VERSION "2023_6_12_103836"

NS_ :

BS_:

BU_: XPU SRR_RL Tester
BO_ 618 S4_SRR_RL_Obj_Mes_3: 64 SRR_RL
 SG_ S4_SRR_RL_Obj_ID_9 : 7|7@0+ (1,0) [0|126] "" Vector__XXX
 SG_ S4_SRR_RL_Obj_DistX_9 : 0|13@0+ (0.0625,-255.9375) [-255.9375|255.9375] "m" Vector__XXX
 SG_ S4_SRR_RL_Obj_RelVelX_9 : 19|11@0+ (0.125,-128) [-128|127.875] "mps" Vector__XXX
 SG_ S4_SRR_RL_Obj_AccelX_9 : 24|10@0+ (0.125,-44.5) [-44.5|44.5] "mps2" Vector__XXX
 SG_ S4_SRR_RL_Obj_DistY_9 : 46|13@0+ (0.0625,-255.9375) [-255.9375|255.9375] "m" Vector__XXX
 SG_ S4_SRR_RL_Obj_RelVelY_9 : 49|11@0+ (0.125,-128) [-128|127.875] "mps" Vector__XXX
 SG_ S4_SRR_RL_Obj_AccelY_9 : 70|10@0+ (0.125,-44.5) [-44.5|44.5] "mps2" Vector__XXX
 SG_ S4_SRR_RL_Obj_DistXStd_9 : 76|8@0+ (0.05,0) [0|12.75] "m" Vector__XXX
 SG_ S4_SRR_RL_Obj_RelVelXStd_9 : 84|6@0+ (0.2,0) [0|12.6] "mps" Vector__XXX
 SG_ S4_SRR_RL_Obj_RAccelXStd_9 : 94|5@0+ (0.35,0) [0|10.85] "mps2" Vector__XXX
 SG_ S4_SRR_RL_Obj_DistYStd_9 : 89|8@0+ (0.1,0) [0|25.5] "m" Vector__XXX
 SG_ S4_SRR_RL_Obj_RelVelYStd_9 : 97|6@0+ (0.2,0) [0|12.6] "mps" Vector__XXX
 SG_ S4_SRR_RL_Obj_RAccelYStd_9 : 107|5@0+ (0.35,0) [0|10.85] "mps2" Vector__XXX
 SG_ S4_SRR_RL_Obj_ValidFlag_9 : 118|1@0+ (1,0) [0|1] "" Vector__XXX
 SG_ S4_SRR_RL_Obj_UpdateFlag_9 : 117|1@0+ (1,0) [0|1] "" Vector__XXX
 SG_ S4_SRR_RL_Obj_ExistProb_9 : 116|7@0+ (1,0) [0|100] "percent" Vector__XXX
 SG_ S4_SRR_RL_Obj_Type_9 : 125|4@0+ (1,0) [0|15] "" Vector__XXX
 SG_ S4_SRR_RL_Obj_EDynProp_9 : 121|4@0+ (1,0) [0|15] "" Vector__XXX
 SG_ S4_SRR_RL_Obj_UiLifeCycles_9 : 133|7@0+ (1,0) [0|127] "" Vector__XXX
 SG_ S4_SRR_RL_Obj_RCS_9 : 142|11@0+ (0.1,-100) [-100|100] "dBm" Vector__XXX
 SG_ S4_SRR_RL_Obj_ID_10 : 147|7@0+ (1,0) [0|126] "" Vector__XXX
 SG_ S4_SRR_RL_Obj_DistX_10 : 156|13@0+ (0.0625,-255.9375) [-255.9375|255.9375] "m" Vector__XXX
 SG_ S4_SRR_RL_Obj_RelVelX_10 : 175|11@0+ (0.125,-128) [-128|127.875] "mps" Vector__XXX
 SG_ S4_SRR_RL_Obj_AccelX_10 : 180|10@0+ (0.125,-44.5) [-44.5|44.5] "mps2" Vector__XXX
 SG_ S4_SRR_RL_Obj_DistY_10 : 186|13@0+ (0.0625,-255.9375) [-255.9375|255.9375] "m" Vector__XXX
 SG_ S4_SRR_RL_Obj_RelVelY_10 : 205|11@0+ (0.125,-128) [-128|127.875] "mps" Vector__XXX
 SG_ S4_SRR_RL_Obj_AccelY_10 : 210|10@0+ (0.125,-44.5) [-44.5|44.5] "mps2" Vector__XXX
 SG_ S4_SRR_RL_Obj_DistXStd_10 : 216|8@0+ (0.05,0) [0|12.75] "m" Vector__XXX
 SG_ S4_SRR_RL_Obj_RelVelXStd_10 : 224|6@0+ (0.2,0) [0|12.6] "mps" Vector__XXX
 SG_ S4_SRR_RL_Obj_RAccelXStd_10 : 234|5@0+ (0.35,0) [0|10.85] "mps2" Vector__XXX
 SG_ S4_SRR_RL_Obj_DistYStd_10 : 245|8@0+ (0.1,0) [0|25.5] "m" Vector__XXX
 SG_ S4_SRR_RL_Obj_RelVelYStd_10 : 253|6@0+ (0.2,0) [0|12.6] "mps" Vector__XXX
 SG_ S4_SRR_RL_Obj_RAccelYStd_10 : 263|5@0+ (0.35,0) [0|10.85] "mps2" Vector__XXX
 SG_ S4_SRR_RL_Obj_ValidFlag_10 : 258|1@0+ (1,0) [0|1] "" Vector__XXX
 SG_ S4_SRR_RL_Obj_UpdateFlag_10 : 257|1@0+ (1,0) [0|1] "" Vector__XXX
 SG_ S4_SRR_RL_Obj_ExistProb_10 : 256|7@0+ (1,0) [0|100] "percent" Vector__XXX
 SG_ S4_SRR_RL_Obj_Type_10 : 265|4@0+ (1,0) [0|15] "" Vector__XXX
 SG_ S4_SRR_RL_Obj_EDynProp_10 : 277|4@0+ (1,0) [0|15] "" Vector__XXX
 SG_ S4_SRR_RL_Obj_UiLifeCycles_10 : 273|7@0+ (1,0) [0|127] "" Vector__XXX
 SG_ S4_SRR_RL_Obj_RCS_10 : 282|11@0+ (0.1,-100) [-100|100] "dBm" Vector__XXX
 SG_ S4_SRR_RL_Obj_ID_11 : 303|7@0+ (1,0) [0|126] "" Vector__XXX
 SG_ S4_SRR_RL_Obj_DistX_11 : 296|13@0+ (0.0625,-255.9375) [-255.9375|255.9375] "m" Vector__XXX
 SG_ S4_SRR_RL_Obj_RelVelX_11 : 315|11@0+ (0.125,-128) [-128|127.875] "mps" Vector__XXX
 SG_ S4_SRR_RL_Obj_AccelX_11 : 320|10@0+ (0.125,-44.5) [-44.5|44.5] "mps2" Vector__XXX
 SG_ S4_SRR_RL_Obj_DistY_11 : 342|13@0+ (0.0625,-255.9375) [-255.9375|255.9375] "m" Vector__XXX
 SG_ S4_SRR_RL_Obj_RelVelY_11 : 345|11@0+ (0.125,-128) [-128|127.875] "mps" Vector__XXX
 SG_ S4_SRR_RL_Obj_AccelY_11 : 366|10@0+ (0.125,-44.5) [-44.5|44.5] "mps2" Vector__XXX
 SG_ S4_SRR_RL_Obj_DistXStd_11 : 372|8@0+ (0.05,0) [0|12.75] "m" Vector__XXX
 SG_ S4_SRR_RL_Obj_RelVelXStd_11 : 380|6@0+ (0.2,0) [0|12.6] "mps" Vector__XXX
 SG_ S4_SRR_RL_Obj_RAccelXStd_11 : 390|5@0+ (0.35,0) [0|10.85] "mps2" Vector__XXX
 SG_ S4_SRR_RL_Obj_DistYStd_11 : 385|8@0+ (0.1,0) [0|25.5] "m" Vector__XXX
 SG_ S4_SRR_RL_Obj_RelVelYStd_11 : 393|6@0+ (0.2,0) [0|12.6] "mps" Vector__XXX
 SG_ S4_SRR_RL_Obj_RAccelYStd_11 : 403|5@0+ (0.35,0) [0|10.85] "mps2" Vector__XXX
 SG_ S4_SRR_RL_Obj_ValidFlag_11 : 414|1@0+ (1,0) [0|1] "" Vector__XXX
 SG_ S4_SRR_RL_Obj_UpdateFlag_11 : 413|1@0+ (1,0) [0|1] "" Vector__XXX
 SG_ S4_SRR_RL_Obj_ExistProb_11 : 412|7@0+ (1,0) [0|100] "percent" Vector__XXX
 SG_ S4_SRR_RL_Obj_Type_11 : 421|4@0+ (1,0) [0|15] "" Vector__XXX
 SG_ S4_SRR_RL_Obj_EDynProp_11 : 417|4@0+ (1,0) [0|15] "" Vector__XXX
 SG_ S4_SRR_RL_Obj_UiLifeCycles_11 : 429|7@0+ (1,0) [0|127] "" Vector__XXX
 SG_ S4_SRR_RL_Obj_RCS_11 : 438|11@0+ (0.1,-100) [-100|100] "dBm" Vector__XXX
 SG_ S4_SRR_RL_Obj_Mes_3_blockcounter : 503|4@0+ (1,0) [0|15] "" Vector__XXX
 SG_ S4_SRR_RL_Obj_3_MsgCounter : 499|4@0+ (1,0) [0|14] "" Vector__XXX
 SG_ S4_SRR_RL_Obj_3_E2EChecksum : 511|8@0+ (1,0) [0|255] "" Vector__XXX

BO_ 619 S4_SRR_RL_Obj_Mes_4: 64 SRR_RL
 SG_ S4_SRR_RL_Obj_ID_12 : 7|7@0+ (1,0) [0|126] "" Vector__XXX
 SG_ S4_SRR_RL_Obj_DistX_12 : 0|13@0+ (0.0625,-255.9375) [-255.9375|255.9375] "m" Vector__XXX
 SG_ S4_SRR_RL_Obj_RelVelX_12 : 19|11@0+ (0.125,-128) [-128|127.875] "mps" Vector__XXX
 SG_ S4_SRR_RL_Obj_AccelX_12 : 24|10@0+ (0.125,-44.5) [-44.5|44.5] "mps2" Vector__XXX
 SG_ S4_SRR_RL_Obj_DistY_12 : 46|13@0+ (0.0625,-255.9375) [-255.9375|255.9375] "m" Vector__XXX
 SG_ S4_SRR_RL_Obj_RelVelY_12 : 49|11@0+ (0.125,-128) [-128|127.875] "mps" Vector__XXX
 SG_ S4_SRR_RL_Obj_AccelY_12 : 70|10@0+ (0.125,-44.5) [-44.5|44.5] "mps2" Vector__XXX
 SG_ S4_SRR_RL_Obj_DistXStd_12 : 76|8@0+ (0.05,0) [0|12.75] "m" Vector__XXX
 SG_ S4_SRR_RL_Obj_RelVelXStd_12 : 84|6@0+ (0.2,0) [0|12.6] "mps" Vector__XXX
 SG_ S4_SRR_RL_Obj_RAccelXStd_12 : 94|5@0+ (0.35,0) [0|10.85] "mps2" Vector__XXX
 SG_ S4_SRR_RL_Obj_DistYStd_12 : 89|8@0+ (0.1,0) [0|25.5] "m" Vector__XXX
 SG_ S4_SRR_RL_Obj_RelVelYStd_12 : 97|6@0+ (0.2,0) [0|12.6] "mps" Vector__XXX
 SG_ S4_SRR_RL_Obj_RAccelYStd_12 : 107|5@0+ (0.35,0) [0|10.85] "mps2" Vector__XXX
 SG_ S4_SRR_RL_Obj_ValidFlag_12 : 118|1@0+ (1,0) [0|1] "" Vector__XXX
 SG_ S4_SRR_RL_Obj_UpdateFlag_12 : 117|1@0+ (1,0) [0|1] "" Vector__XXX
 SG_ S4_SRR_RL_Obj_ExistProb_12 : 116|7@0+ (1,0) [0|100] "percent" Vector__XXX
 SG_ S4_SRR_RL_Obj_Type_12 : 125|4@0+ (1,0) [0|15] "" Vector__XXX
 SG_ S4_SRR_RL_Obj_EDynProp_12 : 121|4@0+ (1,0) [0|15] "" Vector__XXX
 SG_ S4_SRR_RL_Obj_UiLifeCycles_12 : 133|7@0+ (1,0) [0|127] "" Vector__XXX
 SG_ S4_SRR_RL_Obj_RCS_12 : 142|11@0+ (0.1,-100) [-100|100] "dBm" Vector__XXX
 SG_ S4_SRR_RL_Obj_ID_13 : 147|7@0+ (1,0) [0|126] "" Vector__XXX
 SG_ S4_SRR_RL_Obj_DistX_13 : 156|13@0+ (0.0625,-255.9375) [-255.9375|255.9375] "m" Vector__XXX
 SG_ S4_SRR_RL_Obj_RelVelX_13 : 175|11@0+ (0.125,-128) [-128|127.875] "mps" Vector__XXX
 SG_ S4_SRR_RL_Obj_AccelX_13 : 180|10@0+ (0.125,-44.5) [-44.5|44.5] "mps2" Vector__XXX
 SG_ S4_SRR_RL_Obj_DistY_13 : 186|13@0+ (0.0625,-255.9375) [-255.9375|255.9375] "m" Vector__XXX
 SG_ S4_SRR_RL_Obj_RelVelY_13 : 205|11@0+ (0.125,-128) [-128|127.875] "mps" Vector__XXX
 SG_ S4_SRR_RL_Obj_AccelY_13 : 210|10@0+ (0.125,-44.5) [-44.5|44.5] "mps2" Vector__XXX
 SG_ S4_SRR_RL_Obj_DistXStd_13 : 216|8@0+ (0.05,0) [0|12.75] "m" Vector__XXX
 SG_ S4_SRR_RL_Obj_RelVelXStd_13 : 224|6@0+ (0.2,0) [0|12.6] "mps" Vector__XXX
 SG_ S4_SRR_RL_Obj_RAccelXStd_13 : 234|5@0+ (0.35,0) [0|10.85] "mps2" Vector__XXX
 SG_ S4_SRR_RL_Obj_DistYStd_13 : 245|8@0+ (0.1,0) [0|25.5] "m" Vector__XXX
 SG_ S4_SRR_RL_Obj_RelVelYStd_13 : 253|6@0+ (0.2,0) [0|12.6] "mps" Vector__XXX
 SG_ S4_SRR_RL_Obj_RAccelYStd_13 : 263|5@0+ (0.35,0) [0|10.85] "mps2" Vector__XXX
 SG_ S4_SRR_RL_Obj_ValidFlag_13 : 258|1@0+ (1,0) [0|1] "" Vector__XXX
 SG_ S4_SRR_RL_Obj_UpdateFlag_13 : 257|1@0+ (1,0) [0|1] "" Vector__XXX
 SG_ S4_SRR_RL_Obj_ExistProb_13 : 256|7@0+ (1,0) [0|100] "percent" Vector__XXX
 SG_ S4_SRR_RL_Obj_Type_13 : 265|4@0+ (1,0) [0|15] "" Vector__XXX
 SG_ S4_SRR_RL_Obj_EDynProp_13 : 277|4@0+ (1,0) [0|15] "" Vector__XXX
 SG_ S4_SRR_RL_Obj_UiLifeCycles_13 : 273|7@0+ (1,0) [0|127] "" Vector__XXX
 SG_ S4_SRR_RL_Obj_RCS_13 : 282|11@0+ (0.1,-100) [-100|100] "dBm" Vector__XXX
 SG_ S4_SRR_RL_Obj_ID_14 : 303|7@0+ (1,0) [0|126] "" Vector__XXX
 SG_ S4_SRR_RL_Obj_DistX_14 : 296|13@0+ (0.0625,-255.9375) [-255.9375|255.9375] "m" Vector__XXX
 SG_ S4_SRR_RL_Obj_RelVelX_14 : 315|11@0+ (0.125,-128) [-128|127.875] "mps" Vector__XXX
 SG_ S4_SRR_RL_Obj_AccelX_14 : 320|10@0+ (0.125,-44.5) [-44.5|44.5] "mps2" Vector__XXX
 SG_ S4_SRR_RL_Obj_DistY_14 : 342|13@0+ (0.0625,-255.9375) [-255.9375|255.9375] "m" Vector__XXX
 SG_ S4_SRR_RL_Obj_RelVelY_14 : 345|11@0+ (0.125,-128) [-128|127.875] "mps" Vector__XXX
 SG_ S4_SRR_RL_Obj_AccelY_14 : 366|10@0+ (0.125,-44.5) [-44.5|44.5] "mps2" Vector__XXX
 SG_ S4_SRR_RL_Obj_DistXStd_14 : 372|8@0+ (0.05,0) [0|12.75] "m" Vector__XXX
 SG_ S4_SRR_RL_Obj_RelVelXStd_14 : 380|6@0+ (0.2,0) [0|12.6] "mps" Vector__XXX
 SG_ S4_SRR_RL_Obj_RAccelXStd_14 : 390|5@0+ (0.35,0) [0|10.85] "mps2" Vector__XXX
 SG_ S4_SRR_RL_Obj_DistYStd_14 : 385|8@0+ (0.1,0) [0|25.5] "m" Vector__XXX
 SG_ S4_SRR_RL_Obj_RelVelYStd_14 : 393|6@0+ (0.2,0) [0|12.6] "mps" Vector__XXX
 SG_ S4_SRR_RL_Obj_RAccelYStd_14 : 403|5@0+ (0.35,0) [0|10.85] "mps2" Vector__XXX
 SG_ S4_SRR_RL_Obj_ValidFlag_14 : 414|1@0+ (1,0) [0|1] "" Vector__XXX
 SG_ S4_SRR_RL_Obj_UpdateFlag_14 : 413|1@0+ (1,0) [0|1] "" Vector__XXX
 SG_ S4_SRR_RL_Obj_ExistProb_14 : 412|7@0+ (1,0) [0|100] "percent" Vector__XXX
 SG_ S4_SRR_RL_Obj_Type_14 : 421|4@0+ (1,0) [0|15] "" Vector__XXX
 SG_ S4_SRR_RL_Obj_EDynProp_14 : 417|4@0+ (1,0) [0|15] "" Vector__XXX
 SG_ S4_SRR_RL_Obj_UiLifeCycles_14 : 429|7@0+ (1,0) [0|127] "" Vector__XXX
 SG_ S4_SRR_RL_Obj_RCS_14 : 438|11@0+ (0.1,-100) [-100|100] "dBm" Vector__XXX
 SG_ S4_SRR_RL_Obj_Mes_4_blockcounter : 503|4@0+ (1,0) [0|15] "" Vector__XXX
 SG_ S4_SRR_RL_Obj_4_MsgCounter : 499|4@0+ (1,0) [0|14] "" Vector__XXX
 SG_ S4_SRR_RL_Obj_4_E2EChecksum : 511|8@0+ (1,0) [0|255] "" Vector__XXX

BO_ 620 S4_SRR_RL_Obj_Mes_5: 64 SRR_RL
 SG_ S4_SRR_RL_Obj_ID_15 : 7|7@0+ (1,0) [0|126] "" Vector__XXX
 SG_ S4_SRR_RL_Obj_DistX_15 : 0|13@0+ (0.0625,-255.9375) [-255.9375|255.9375] "m" Vector__XXX
 SG_ S4_SRR_RL_Obj_RelVelX_15 : 19|11@0+ (0.125,-128) [-128|127.875] "mps" Vector__XXX
 SG_ S4_SRR_RL_Obj_AccelX_15 : 24|10@0+ (0.125,-44.5) [-44.5|44.5] "mps2" Vector__XXX
 SG_ S4_SRR_RL_Obj_DistY_15 : 46|13@0+ (0.0625,-255.9375) [-255.9375|255.9375] "m" Vector__XXX
 SG_ S4_SRR_RL_Obj_RelVelY_15 : 49|11@0+ (0.125,-128) [-128|127.875] "mps" Vector__XXX
 SG_ S4_SRR_RL_Obj_AccelY_15 : 70|10@0+ (0.125,-44.5) [-44.5|44.5] "mps2" Vector__XXX
 SG_ S4_SRR_RL_Obj_DistXStd_15 : 76|8@0+ (0.05,0) [0|12.75] "m" Vector__XXX
 SG_ S4_SRR_RL_Obj_RelVelXStd_15 : 84|6@0+ (0.2,0) [0|12.6] "mps" Vector__XXX
 SG_ S4_SRR_RL_Obj_RAccelXStd_15 : 94|5@0+ (0.35,0) [0|10.85] "mps2" Vector__XXX
 SG_ S4_SRR_RL_Obj_DistYStd_15 : 89|8@0+ (0.1,0) [0|25.5] "m" Vector__XXX
 SG_ S4_SRR_RL_Obj_RelVelYStd_15 : 97|6@0+ (0.2,0) [0|12.6] "mps" Vector__XXX
 SG_ S4_SRR_RL_Obj_RAccelYStd_15 : 107|5@0+ (0.35,0) [0|10.85] "mps2" Vector__XXX
 SG_ S4_SRR_RL_Obj_ValidFlag_15 : 118|1@0+ (1,0) [0|1] "" Vector__XXX
 SG_ S4_SRR_RL_Obj_UpdateFlag_15 : 117|1@0+ (1,0) [0|1] "" Vector__XXX
 SG_ S4_SRR_RL_Obj_ExistProb_15 : 116|7@0+ (1,0) [0|100] "percent" Vector__XXX
 SG_ S4_SRR_RL_Obj_Type_15 : 125|4@0+ (1,0) [0|15] "" Vector__XXX
 SG_ S4_SRR_RL_Obj_EDynProp_15 : 121|4@0+ (1,0) [0|15] "" Vector__XXX
 SG_ S4_SRR_RL_Obj_UiLifeCycles_15 : 133|7@0+ (1,0) [0|127] "" Vector__XXX
 SG_ S4_SRR_RL_Obj_RCS_15 : 142|11@0+ (0.1,-100) [-100|100] "dBm" Vector__XXX
 SG_ S4_SRR_RL_Obj_ID_16 : 147|7@0+ (1,0) [0|126] "" Vector__XXX
 SG_ S4_SRR_RL_Obj_DistX_16 : 156|13@0+ (0.0625,-255.9375) [-255.9375|255.9375] "m" Vector__XXX
 SG_ S4_SRR_RL_Obj_RelVelX_16 : 175|11@0+ (0.125,-128) [-128|127.875] "mps" Vector__XXX
 SG_ S4_SRR_RL_Obj_AccelX_16 : 180|10@0+ (0.125,-44.5) [-44.5|44.5] "mps2" Vector__XXX
 SG_ S4_SRR_RL_Obj_DistY_16 : 186|13@0+ (0.0625,-255.9375) [-255.9375|255.9375] "m" Vector__XXX
 SG_ S4_SRR_RL_Obj_RelVelY_16 : 205|11@0+ (0.125,-128) [-128|127.875] "mps" Vector__XXX
 SG_ S4_SRR_RL_Obj_AccelY_16 : 210|10@0+ (0.125,-44.5) [-44.5|44.5] "mps2" Vector__XXX
 SG_ S4_SRR_RL_Obj_DistXStd_16 : 216|8@0+ (0.05,0) [0|12.75] "m" Vector__XXX
 SG_ S4_SRR_RL_Obj_RelVelXStd_16 : 224|6@0+ (0.2,0) [0|12.6] "mps" Vector__XXX
 SG_ S4_SRR_RL_Obj_RAccelXStd_16 : 234|5@0+ (0.35,0) [0|10.85] "mps2" Vector__XXX
 SG_ S4_SRR_RL_Obj_DistYStd_16 : 245|8@0+ (0.1,0) [0|25.5] "m" Vector__XXX
 SG_ S4_SRR_RL_Obj_RelVelYStd_16 : 253|6@0+ (0.2,0) [0|12.6] "mps" Vector__XXX
 SG_ S4_SRR_RL_Obj_RAccelYStd_16 : 263|5@0+ (0.35,0) [0|10.85] "mps2" Vector__XXX
 SG_ S4_SRR_RL_Obj_ValidFlag_16 : 258|1@0+ (1,0) [0|1] "" Vector__XXX
 SG_ S4_SRR_RL_Obj_UpdateFlag_16 : 257|1@0+ (1,0) [0|1] "" Vector__XXX
 SG_ S4_SRR_RL_Obj_ExistProb_16 : 256|7@0+ (1,0) [0|100] "percent" Vector__XXX
 SG_ S4_SRR_RL_Obj_Type_16 : 265|4@0+ (1,0) [0|15] "" Vector__XXX
 SG_ S4_SRR_RL_Obj_EDynProp_16 : 277|4@0+ (1,0) [0|15] "" Vector__XXX
 SG_ S4_SRR_RL_Obj_UiLifeCycles_16 : 273|7@0+ (1,0) [0|127] "" Vector__XXX
 SG_ S4_SRR_RL_Obj_RCS_16 : 282|11@0+ (0.1,-100) [-100|100] "dBm" Vector__XXX
 SG_ S4_SRR_RL_Obj_ID_17 : 303|7@0+ (1,0) [0|126] "" Vector__XXX
 SG_ S4_SRR_RL_Obj_DistX_17 : 296|13@0+ (0.0625,-255.9375) [-255.9375|255.9375] "m" Vector__XXX
 SG_ S4_SRR_RL_Obj_RelVelX_17 : 315|11@0+ (0.125,-128) [-128|127.875] "mps" Vector__XXX
 SG_ S4_SRR_RL_Obj_AccelX_17 : 320|10@0+ (0.125,-44.5) [-44.5|44.5] "mps2" Vector__XXX
 SG_ S4_SRR_RL_Obj_DistY_17 : 342|13@0+ (0.0625,-255.9375) [-255.9375|255.9375] "m" Vector__XXX
 SG_ S4_SRR_RL_Obj_RelVelY_17 : 345|11@0+ (0.125,-128) [-128|127.875] "mps" Vector__XXX
 SG_ S4_SRR_RL_Obj_AccelY_17 : 366|10@0+ (0.125,-44.5) [-44.5|44.5] "mps2" Vector__XXX
 SG_ S4_SRR_RL_Obj_DistXStd_17 : 372|8@0+ (0.05,0) [0|12.75] "m" Vector__XXX
 SG_ S4_SRR_RL_Obj_RelVelXStd_17 : 380|6@0+ (0.2,0) [0|12.6] "mps" Vector__XXX
 SG_ S4_SRR_RL_Obj_RAccelXStd_17 : 390|5@0+ (0.35,0) [0|10.85] "mps2" Vector__XXX
 SG_ S4_SRR_RL_Obj_DistYStd_17 : 385|8@0+ (0.1,0) [0|25.5] "m" Vector__XXX
 SG_ S4_SRR_RL_Obj_RelVelYStd_17 : 393|6@0+ (0.2,0) [0|12.6] "mps" Vector__XXX
 SG_ S4_SRR_RL_Obj_RAccelYStd_17 : 403|5@0+ (0.35,0) [0|10.85] "mps2" Vector__XXX
 SG_ S4_SRR_RL_Obj_ValidFlag_17 : 414|1@0+ (1,0) [0|1] "" Vector__XXX
 SG_ S4_SRR_RL_Obj_UpdateFlag_17 : 413|1@0+ (1,0) [0|1] "" Vector__XXX
 SG_ S4_SRR_RL_Obj_ExistProb_17 : 412|7@0+ (1,0) [0|100] "percent" Vector__XXX
 SG_ S4_SRR_RL_Obj_Type_17 : 421|4@0+ (1,0) [0|15] "" Vector__XXX
 SG_ S4_SRR_RL_Obj_EDynProp_17 : 417|4@0+ (1,0) [0|15] "" Vector__XXX
 SG_ S4_SRR_RL_Obj_UiLifeCycles_17 : 429|7@0+ (1,0) [0|127] "" Vector__XXX
 SG_ S4_SRR_RL_Obj_RCS_17 : 438|11@0+ (0.1,-100) [-100|100] "dBm" Vector__XXX
 SG_ S4_SRR_RL_Obj_Mes_5_blockcounter : 503|4@0+ (1,0) [0|15] "" Vector__XXX
 SG_ S4_SRR_RL_Obj_5_MsgCounter : 499|4@0+ (1,0) [0|14] "" Vector__XXX
 SG_ S4_SRR_RL_Obj_5_E2EChecksum : 511|8@0+ (1,0) [0|255] "" Vector__XXX

BO_ 621 S4_SRR_RL_Obj_Mes_6: 64 SRR_RL
 SG_ S4_SRR_RL_Obj_ID_18 : 7|7@0+ (1,0) [0|126] "" Vector__XXX
 SG_ S4_SRR_RL_Obj_DistX_18 : 0|13@0+ (0.0625,-255.9375) [-255.9375|255.9375] "m" Vector__XXX
 SG_ S4_SRR_RL_Obj_RelVelX_18 : 19|11@0+ (0.125,-128) [-128|127.875] "mps" Vector__XXX
 SG_ S4_SRR_RL_Obj_AccelX_18 : 24|10@0+ (0.125,-44.5) [-44.5|44.5] "mps2" Vector__XXX
 SG_ S4_SRR_RL_Obj_DistY_18 : 46|13@0+ (0.0625,-255.9375) [-255.9375|255.9375] "m" Vector__XXX
 SG_ S4_SRR_RL_Obj_RelVelY_18 : 49|11@0+ (0.125,-128) [-128|127.875] "mps" Vector__XXX
 SG_ S4_SRR_RL_Obj_AccelY_18 : 70|10@0+ (0.125,-44.5) [-44.5|44.5] "mps2" Vector__XXX
 SG_ S4_SRR_RL_Obj_DistXStd_18 : 76|8@0+ (0.05,0) [0|12.75] "m" Vector__XXX
 SG_ S4_SRR_RL_Obj_RelVelXStd_18 : 84|6@0+ (0.2,0) [0|12.6] "mps" Vector__XXX
 SG_ S4_SRR_RL_Obj_RAccelXStd_18 : 94|5@0+ (0.35,0) [0|10.85] "mps2" Vector__XXX
 SG_ S4_SRR_RL_Obj_DistYStd_18 : 89|8@0+ (0.1,0) [0|25.5] "m" Vector__XXX
 SG_ S4_SRR_RL_Obj_RelVelYStd_18 : 97|6@0+ (0.2,0) [0|12.6] "mps" Vector__XXX
 SG_ S4_SRR_RL_Obj_RAccelYStd_18 : 107|5@0+ (0.35,0) [0|10.85] "mps2" Vector__XXX
 SG_ S4_SRR_RL_Obj_ValidFlag_18 : 118|1@0+ (1,0) [0|1] "" Vector__XXX
 SG_ S4_SRR_RL_Obj_UpdateFlag_18 : 117|1@0+ (1,0) [0|1] "" Vector__XXX
 SG_ S4_SRR_RL_Obj_ExistProb_18 : 116|7@0+ (1,0) [0|100] "percent" Vector__XXX
 SG_ S4_SRR_RL_Obj_Type_18 : 125|4@0+ (1,0) [0|15] "" Vector__XXX
 SG_ S4_SRR_RL_Obj_EDynProp_18 : 121|4@0+ (1,0) [0|15] "" Vector__XXX
 SG_ S4_SRR_RL_Obj_UiLifeCycles_18 : 133|7@0+ (1,0) [0|127] "" Vector__XXX
 SG_ S4_SRR_RL_Obj_RCS_18 : 142|11@0+ (0.1,-100) [-100|100] "dBm" Vector__XXX
 SG_ S4_SRR_RL_Obj_ID_19 : 147|7@0+ (1,0) [0|126] "" Vector__XXX
 SG_ S4_SRR_RL_Obj_DistX_19 : 156|13@0+ (0.0625,-255.9375) [-255.9375|255.9375] "m" Vector__XXX
 SG_ S4_SRR_RL_Obj_RelVelX_19 : 175|11@0+ (0.125,-128) [-128|127.875] "mps" Vector__XXX
 SG_ S4_SRR_RL_Obj_AccelX_19 : 180|10@0+ (0.125,-44.5) [-44.5|44.5] "mps2" Vector__XXX
 SG_ S4_SRR_RL_Obj_DistY_19 : 186|13@0+ (0.0625,-255.9375) [-255.9375|255.9375] "m" Vector__XXX
 SG_ S4_SRR_RL_Obj_RelVelY_19 : 205|11@0+ (0.125,-128) [-128|127.875] "mps" Vector__XXX
 SG_ S4_SRR_RL_Obj_AccelY_19 : 210|10@0+ (0.125,-44.5) [-44.5|44.5] "mps2" Vector__XXX
 SG_ S4_SRR_RL_Obj_DistXStd_19 : 216|8@0+ (0.05,0) [0|12.75] "m" Vector__XXX
 SG_ S4_SRR_RL_Obj_RelVelXStd_19 : 224|6@0+ (0.2,0) [0|12.6] "mps" Vector__XXX
 SG_ S4_SRR_RL_Obj_RAccelXStd_19 : 234|5@0+ (0.35,0) [0|10.85] "mps2" Vector__XXX
 SG_ S4_SRR_RL_Obj_DistYStd_19 : 245|8@0+ (0.1,0) [0|25.5] "m" Vector__XXX
 SG_ S4_SRR_RL_Obj_RelVelYStd_19 : 253|6@0+ (0.2,0) [0|12.6] "mps" Vector__XXX
 SG_ S4_SRR_RL_Obj_RAccelYStd_19 : 263|5@0+ (0.35,0) [0|10.85] "mps2" Vector__XXX
 SG_ S4_SRR_RL_Obj_ValidFlag_19 : 258|1@0+ (1,0) [0|1] "" Vector__XXX
 SG_ S4_SRR_RL_Obj_UpdateFlag_19 : 257|1@0+ (1,0) [0|1] "" Vector__XXX
 SG_ S4_SRR_RL_Obj_ExistProb_19 : 256|7@0+ (1,0) [0|100] "percent" Vector__XXX
 SG_ S4_SRR_RL_Obj_Type_19 : 265|4@0+ (1,0) [0|15] "" Vector__XXX
 SG_ S4_SRR_RL_Obj_EDynProp_19 : 277|4@0+ (1,0) [0|15] "" Vector__XXX
 SG_ S4_SRR_RL_Obj_UiLifeCycles_19 : 273|7@0+ (1,0) [0|127] "" Vector__XXX
 SG_ S4_SRR_RL_Obj_RCS_19 : 282|11@0+ (0.1,-100) [-100|100] "dBm" Vector__XXX
 SG_ S4_SRR_RL_Obj_ID_20 : 303|7@0+ (1,0) [0|126] "" Vector__XXX
 SG_ S4_SRR_RL_Obj_DistX_20 : 296|13@0+ (0.0625,-255.9375) [-255.9375|255.9375] "m" Vector__XXX
 SG_ S4_SRR_RL_Obj_RelVelX_20 : 315|11@0+ (0.125,-128) [-128|127.875] "mps" Vector__XXX
 SG_ S4_SRR_RL_Obj_AccelX_20 : 320|10@0+ (0.125,-44.5) [-44.5|44.5] "mps2" Vector__XXX
 SG_ S4_SRR_RL_Obj_DistY_20 : 342|13@0+ (0.0625,-255.9375) [-255.9375|255.9375] "m" Vector__XXX
 SG_ S4_SRR_RL_Obj_RelVelY_20 : 345|11@0+ (0.125,-128) [-128|127.875] "mps" Vector__XXX
 SG_ S4_SRR_RL_Obj_AccelY_20 : 366|10@0+ (0.125,-44.5) [-44.5|44.5] "mps2" Vector__XXX
 SG_ S4_SRR_RL_Obj_DistXStd_20 : 372|8@0+ (0.05,0) [0|12.75] "m" Vector__XXX
 SG_ S4_SRR_RL_Obj_RelVelXStd_20 : 380|6@0+ (0.2,0) [0|12.6] "mps" Vector__XXX
 SG_ S4_SRR_RL_Obj_RAccelXStd_20 : 390|5@0+ (0.35,0) [0|10.85] "mps2" Vector__XXX
 SG_ S4_SRR_RL_Obj_DistYStd_20 : 385|8@0+ (0.1,0) [0|25.5] "m" Vector__XXX
 SG_ S4_SRR_RL_Obj_RelVelYStd_20 : 393|6@0+ (0.2,0) [0|12.6] "mps" Vector__XXX
 SG_ S4_SRR_RL_Obj_RAccelYStd_20 : 403|5@0+ (0.35,0) [0|10.85] "mps2" Vector__XXX
 SG_ S4_SRR_RL_Obj_ValidFlag_20 : 414|1@0+ (1,0) [0|1] "" Vector__XXX
 SG_ S4_SRR_RL_Obj_UpdateFlag_20 : 413|1@0+ (1,0) [0|1] "" Vector__XXX
 SG_ S4_SRR_RL_Obj_ExistProb_20 : 412|7@0+ (1,0) [0|100] "percent" Vector__XXX
 SG_ S4_SRR_RL_Obj_Type_20 : 421|4@0+ (1,0) [0|15] "" Vector__XXX
 SG_ S4_SRR_RL_Obj_EDynProp_20 : 417|4@0+ (1,0) [0|15] "" Vector__XXX
 SG_ S4_SRR_RL_Obj_UiLifeCycles_20 : 429|7@0+ (1,0) [0|127] "" Vector__XXX
 SG_ S4_SRR_RL_Obj_RCS_20 : 438|11@0+ (0.1,-100) [-100|100] "dBm" Vector__XXX
 SG_ S4_SRR_RL_Obj_Mes_6_blockcounter : 503|4@0+ (1,0) [0|15] "" Vector__XXX
 SG_ S4_SRR_RL_Obj_6_MsgCounter : 499|4@0+ (1,0) [0|14] "" Vector__XXX
 SG_ S4_SRR_RL_Obj_6_E2EChecksum : 511|8@0+ (1,0) [0|255] "" Vector__XXX

BO_ 622 S4_SRR_RL_Obj_Mes_7: 64 SRR_RL
 SG_ S4_SRR_RL_Obj_ID_21 : 7|7@0+ (1,0) [0|126] "" Vector__XXX
 SG_ S4_SRR_RL_Obj_DistX_21 : 0|13@0+ (0.0625,-255.9375) [-255.9375|255.9375] "m" Vector__XXX
 SG_ S4_SRR_RL_Obj_RelVelX_21 : 19|11@0+ (0.125,-128) [-128|127.875] "mps" Vector__XXX
 SG_ S4_SRR_RL_Obj_AccelX_21 : 24|10@0+ (0.125,-44.5) [-44.5|44.5] "mps2" Vector__XXX
 SG_ S4_SRR_RL_Obj_DistY_21 : 46|13@0+ (0.0625,-255.9375) [-255.9375|255.9375] "m" Vector__XXX
 SG_ S4_SRR_RL_Obj_RelVelY_21 : 49|11@0+ (0.125,-128) [-128|127.875] "mps" Vector__XXX
 SG_ S4_SRR_RL_Obj_AccelY_21 : 70|10@0+ (0.125,-44.5) [-44.5|44.5] "mps2" Vector__XXX
 SG_ S4_SRR_RL_Obj_DistXStd_21 : 76|8@0+ (0.05,0) [0|12.75] "m" Vector__XXX
 SG_ S4_SRR_RL_Obj_RelVelXStd_21 : 84|6@0+ (0.2,0) [0|12.6] "mps" Vector__XXX
 SG_ S4_SRR_RL_Obj_RAccelXStd_21 : 94|5@0+ (0.35,0) [0|10.85] "mps2" Vector__XXX
 SG_ S4_SRR_RL_Obj_DistYStd_21 : 89|8@0+ (0.1,0) [0|25.5] "m" Vector__XXX
 SG_ S4_SRR_RL_Obj_RelVelYStd_21 : 97|6@0+ (0.2,0) [0|12.6] "mps" Vector__XXX
 SG_ S4_SRR_RL_Obj_RAccelYStd_21 : 107|5@0+ (0.35,0) [0|10.85] "mps2" Vector__XXX
 SG_ S4_SRR_RL_Obj_ValidFlag_21 : 118|1@0+ (1,0) [0|1] "" Vector__XXX
 SG_ S4_SRR_RL_Obj_UpdateFlag_21 : 117|1@0+ (1,0) [0|1] "" Vector__XXX
 SG_ S4_SRR_RL_Obj_ExistProb_21 : 116|7@0+ (1,0) [0|100] "percent" Vector__XXX
 SG_ S4_SRR_RL_Obj_Type_21 : 125|4@0+ (1,0) [0|15] "" Vector__XXX
 SG_ S4_SRR_RL_Obj_EDynProp_21 : 121|4@0+ (1,0) [0|15] "" Vector__XXX
 SG_ S4_SRR_RL_Obj_UiLifeCycles_21 : 133|7@0+ (1,0) [0|127] "" Vector__XXX
 SG_ S4_SRR_RL_Obj_RCS_21 : 142|11@0+ (0.1,-100) [-100|100] "dBm" Vector__XXX
 SG_ S4_SRR_RL_Obj_ID_22 : 147|7@0+ (1,0) [0|126] "" Vector__XXX
 SG_ S4_SRR_RL_Obj_DistX_22 : 156|13@0+ (0.0625,-255.9375) [-255.9375|255.9375] "m" Vector__XXX
 SG_ S4_SRR_RL_Obj_RelVelX_22 : 175|11@0+ (0.125,-128) [-128|127.875] "mps" Vector__XXX
 SG_ S4_SRR_RL_Obj_AccelX_22 : 180|10@0+ (0.125,-44.5) [-44.5|44.5] "mps2" Vector__XXX
 SG_ S4_SRR_RL_Obj_DistY_22 : 186|13@0+ (0.0625,-255.9375) [-255.9375|255.9375] "m" Vector__XXX
 SG_ S4_SRR_RL_Obj_RelVelY_22 : 205|11@0+ (0.125,-128) [-128|127.875] "mps" Vector__XXX
 SG_ S4_SRR_RL_Obj_AccelY_22 : 210|10@0+ (0.125,-44.5) [-44.5|44.5] "mps2" Vector__XXX
 SG_ S4_SRR_RL_Obj_DistXStd_22 : 216|8@0+ (0.05,0) [0|12.75] "m" Vector__XXX
 SG_ S4_SRR_RL_Obj_RelVelXStd_22 : 224|6@0+ (0.2,0) [0|12.6] "mps" Vector__XXX
 SG_ S4_SRR_RL_Obj_RAccelXStd_22 : 234|5@0+ (0.35,0) [0|10.85] "mps2" Vector__XXX
 SG_ S4_SRR_RL_Obj_DistYStd_22 : 245|8@0+ (0.1,0) [0|25.5] "m" Vector__XXX
 SG_ S4_SRR_RL_Obj_RelVelYStd_22 : 253|6@0+ (0.2,0) [0|12.6] "mps" Vector__XXX
 SG_ S4_SRR_RL_Obj_RAccelYStd_22 : 263|5@0+ (0.35,0) [0|10.85] "mps2" Vector__XXX
 SG_ S4_SRR_RL_Obj_ValidFlag_22 : 258|1@0+ (1,0) [0|1] "" Vector__XXX
 SG_ S4_SRR_RL_Obj_UpdateFlag_22 : 257|1@0+ (1,0) [0|1] "" Vector__XXX
 SG_ S4_SRR_RL_Obj_ExistProb_22 : 256|7@0+ (1,0) [0|100] "percent" Vector__XXX
 SG_ S4_SRR_RL_Obj_Type_22 : 265|4@0+ (1,0) [0|15] "" Vector__XXX
 SG_ S4_SRR_RL_Obj_EDynProp_22 : 277|4@0+ (1,0) [0|15] "" Vector__XXX
 SG_ S4_SRR_RL_Obj_UiLifeCycles_22 : 273|7@0+ (1,0) [0|127] "" Vector__XXX
 SG_ S4_SRR_RL_Obj_RCS_22 : 282|11@0+ (0.1,-100) [-100|100] "dBm" Vector__XXX
 SG_ S4_SRR_RL_Obj_ID_23 : 303|7@0+ (1,0) [0|126] "" Vector__XXX
 SG_ S4_SRR_RL_Obj_DistX_23 : 296|13@0+ (0.0625,-255.9375) [-255.9375|255.9375] "m" Vector__XXX
 SG_ S4_SRR_RL_Obj_RelVelX_23 : 315|11@0+ (0.125,-128) [-128|127.875] "mps" Vector__XXX
 SG_ S4_SRR_RL_Obj_AccelX_23 : 320|10@0+ (0.125,-44.5) [-44.5|44.5] "mps2" Vector__XXX
 SG_ S4_SRR_RL_Obj_DistY_23 : 342|13@0+ (0.0625,-255.9375) [-255.9375|255.9375] "m" Vector__XXX
 SG_ S4_SRR_RL_Obj_RelVelY_23 : 345|11@0+ (0.125,-128) [-128|127.875] "mps" Vector__XXX
 SG_ S4_SRR_RL_Obj_AccelY_23 : 366|10@0+ (0.125,-44.5) [-44.5|44.5] "mps2" Vector__XXX
 SG_ S4_SRR_RL_Obj_DistXStd_23 : 372|8@0+ (0.05,0) [0|12.75] "m" Vector__XXX
 SG_ S4_SRR_RL_Obj_RelVelXStd_23 : 380|6@0+ (0.2,0) [0|12.6] "mps" Vector__XXX
 SG_ S4_SRR_RL_Obj_RAccelXStd_23 : 390|5@0+ (0.35,0) [0|10.85] "mps2" Vector__XXX
 SG_ S4_SRR_RL_Obj_DistYStd_23 : 385|8@0+ (0.1,0) [0|25.5] "m" Vector__XXX
 SG_ S4_SRR_RL_Obj_RelVelYStd_23 : 393|6@0+ (0.2,0) [0|12.6] "mps" Vector__XXX
 SG_ S4_SRR_RL_Obj_RAccelYStd_23 : 403|5@0+ (0.35,0) [0|10.85] "mps2" Vector__XXX
 SG_ S4_SRR_RL_Obj_ValidFlag_23 : 414|1@0+ (1,0) [0|1] "" Vector__XXX
 SG_ S4_SRR_RL_Obj_UpdateFlag_23 : 413|1@0+ (1,0) [0|1] "" Vector__XXX
 SG_ S4_SRR_RL_Obj_ExistProb_23 : 412|7@0+ (1,0) [0|100] "percent" Vector__XXX
 SG_ S4_SRR_RL_Obj_Type_23 : 421|4@0+ (1,0) [0|15] "" Vector__XXX
 SG_ S4_SRR_RL_Obj_EDynProp_23 : 417|4@0+ (1,0) [0|15] "" Vector__XXX
 SG_ S4_SRR_RL_Obj_UiLifeCycles_23 : 429|7@0+ (1,0) [0|127] "" Vector__XXX
 SG_ S4_SRR_RL_Obj_RCS_23 : 438|11@0+ (0.1,-100) [-100|100] "dBm" Vector__XXX
 SG_ S4_SRR_RL_Obj_Mes_7_blockcounter : 503|4@0+ (1,0) [0|15] "" Vector__XXX
 SG_ S4_SRR_RL_Obj_7_MsgCounter : 499|4@0+ (1,0) [0|14] "" Vector__XXX
 SG_ S4_SRR_RL_Obj_7_E2EChecksum : 511|8@0+ (1,0) [0|255] "" Vector__XXX

BO_ 623 S4_SRR_RL_Obj_Mes_8: 64 SRR_RL
 SG_ S4_SRR_RL_Obj_ID_24 : 7|7@0+ (1,0) [0|126] "" Vector__XXX
 SG_ S4_SRR_RL_Obj_DistX_24 : 0|13@0+ (0.0625,-255.9375) [-255.9375|255.9375] "m" Vector__XXX
 SG_ S4_SRR_RL_Obj_RelVelX_24 : 19|11@0+ (0.125,-128) [-128|127.875] "mps" Vector__XXX
 SG_ S4_SRR_RL_Obj_AccelX_24 : 24|10@0+ (0.125,-44.5) [-44.5|44.5] "mps2" Vector__XXX
 SG_ S4_SRR_RL_Obj_DistY_24 : 46|13@0+ (0.0625,-255.9375) [-255.9375|255.9375] "m" Vector__XXX
 SG_ S4_SRR_RL_Obj_RelVelY_24 : 49|11@0+ (0.125,-128) [-128|127.875] "mps" Vector__XXX
 SG_ S4_SRR_RL_Obj_AccelY_24 : 70|10@0+ (0.125,-44.5) [-44.5|44.5] "mps2" Vector__XXX
 SG_ S4_SRR_RL_Obj_DistXStd_24 : 76|8@0+ (0.05,0) [0|12.75] "m" Vector__XXX
 SG_ S4_SRR_RL_Obj_RelVelXStd_24 : 84|6@0+ (0.2,0) [0|12.6] "mps" Vector__XXX
 SG_ S4_SRR_RL_Obj_RAccelXStd_24 : 94|5@0+ (0.35,0) [0|10.85] "mps2" Vector__XXX
 SG_ S4_SRR_RL_Obj_DistYStd_24 : 89|8@0+ (0.1,0) [0|25.5] "m" Vector__XXX
 SG_ S4_SRR_RL_Obj_RelVelYStd_24 : 97|6@0+ (0.2,0) [0|12.6] "mps" Vector__XXX
 SG_ S4_SRR_RL_Obj_RAccelYStd_24 : 107|5@0+ (0.35,0) [0|10.85] "mps2" Vector__XXX
 SG_ S4_SRR_RL_Obj_ValidFlag_24 : 118|1@0+ (1,0) [0|1] "" Vector__XXX
 SG_ S4_SRR_RL_Obj_UpdateFlag_24 : 117|1@0+ (1,0) [0|1] "" Vector__XXX
 SG_ S4_SRR_RL_Obj_ExistProb_24 : 116|7@0+ (1,0) [0|100] "percent" Vector__XXX
 SG_ S4_SRR_RL_Obj_Type_24 : 125|4@0+ (1,0) [0|15] "" Vector__XXX
 SG_ S4_SRR_RL_Obj_EDynProp_24 : 121|4@0+ (1,0) [0|15] "" Vector__XXX
 SG_ S4_SRR_RL_Obj_UiLifeCycles_24 : 133|7@0+ (1,0) [0|127] "" Vector__XXX
 SG_ S4_SRR_RL_Obj_RCS_24 : 142|11@0+ (0.1,-100) [-100|100] "dBm" Vector__XXX
 SG_ S4_SRR_RL_Obj_ID_25 : 147|7@0+ (1,0) [0|126] "" Vector__XXX
 SG_ S4_SRR_RL_Obj_DistX_25 : 156|13@0+ (0.0625,-255.9375) [-255.9375|255.9375] "m" Vector__XXX
 SG_ S4_SRR_RL_Obj_RelVelX_25 : 175|11@0+ (0.125,-128) [-128|127.875] "mps" Vector__XXX
 SG_ S4_SRR_RL_Obj_AccelX_25 : 180|10@0+ (0.125,-44.5) [-44.5|44.5] "mps2" Vector__XXX
 SG_ S4_SRR_RL_Obj_DistY_25 : 186|13@0+ (0.0625,-255.9375) [-255.9375|255.9375] "m" Vector__XXX
 SG_ S4_SRR_RL_Obj_RelVelY_25 : 205|11@0+ (0.125,-128) [-128|127.875] "mps" Vector__XXX
 SG_ S4_SRR_RL_Obj_AccelY_25 : 210|10@0+ (0.125,-44.5) [-44.5|44.5] "mps2" Vector__XXX
 SG_ S4_SRR_RL_Obj_DistXStd_25 : 216|8@0+ (0.05,0) [0|12.75] "m" Vector__XXX
 SG_ S4_SRR_RL_Obj_RelVelXStd_25 : 224|6@0+ (0.2,0) [0|12.6] "mps" Vector__XXX
 SG_ S4_SRR_RL_Obj_RAccelXStd_25 : 234|5@0+ (0.35,0) [0|10.85] "mps2" Vector__XXX
 SG_ S4_SRR_RL_Obj_DistYStd_25 : 245|8@0+ (0.1,0) [0|25.5] "m" Vector__XXX
 SG_ S4_SRR_RL_Obj_RelVelYStd_25 : 253|6@0+ (0.2,0) [0|12.6] "mps" Vector__XXX
 SG_ S4_SRR_RL_Obj_RAccelYStd_25 : 263|5@0+ (0.35,0) [0|10.85] "mps2" Vector__XXX
 SG_ S4_SRR_RL_Obj_ValidFlag_25 : 258|1@0+ (1,0) [0|1] "" Vector__XXX
 SG_ S4_SRR_RL_Obj_UpdateFlag_25 : 257|1@0+ (1,0) [0|1] "" Vector__XXX
 SG_ S4_SRR_RL_Obj_ExistProb_25 : 256|7@0+ (1,0) [0|100] "percent" Vector__XXX
 SG_ S4_SRR_RL_Obj_Type_25 : 265|4@0+ (1,0) [0|15] "" Vector__XXX
 SG_ S4_SRR_RL_Obj_EDynProp_25 : 277|4@0+ (1,0) [0|15] "" Vector__XXX
 SG_ S4_SRR_RL_Obj_UiLifeCycles_25 : 273|7@0+ (1,0) [0|127] "" Vector__XXX
 SG_ S4_SRR_RL_Obj_RCS_25 : 282|11@0+ (0.1,-100) [-100|100] "dBm" Vector__XXX
 SG_ S4_SRR_RL_Obj_ID_26 : 303|7@0+ (1,0) [0|126] "" Vector__XXX
 SG_ S4_SRR_RL_Obj_DistX_26 : 296|13@0+ (0.0625,-255.9375) [-255.9375|255.9375] "m" Vector__XXX
 SG_ S4_SRR_RL_Obj_RelVelX_26 : 315|11@0+ (0.125,-128) [-128|127.875] "mps" Vector__XXX
 SG_ S4_SRR_RL_Obj_AccelX_26 : 320|10@0+ (0.125,-44.5) [-44.5|44.5] "mps2" Vector__XXX
 SG_ S4_SRR_RL_Obj_DistY_26 : 342|13@0+ (0.0625,-255.9375) [-255.9375|255.9375] "m" Vector__XXX
 SG_ S4_SRR_RL_Obj_RelVelY_26 : 345|11@0+ (0.125,-128) [-128|127.875] "mps" Vector__XXX
 SG_ S4_SRR_RL_Obj_AccelY_26 : 366|10@0+ (0.125,-44.5) [-44.5|44.5] "mps2" Vector__XXX
 SG_ S4_SRR_RL_Obj_DistXStd_26 : 372|8@0+ (0.05,0) [0|12.75] "m" Vector__XXX
 SG_ S4_SRR_RL_Obj_RelVelXStd_26 : 380|6@0+ (0.2,0) [0|12.6] "mps" Vector__XXX
 SG_ S4_SRR_RL_Obj_RAccelXStd_26 : 390|5@0+ (0.35,0) [0|10.85] "mps2" Vector__XXX
 SG_ S4_SRR_RL_Obj_DistYStd_26 : 385|8@0+ (0.1,0) [0|25.5] "m" Vector__XXX
 SG_ S4_SRR_RL_Obj_RelVelYStd_26 : 393|6@0+ (0.2,0) [0|12.6] "mps" Vector__XXX
 SG_ S4_SRR_RL_Obj_RAccelYStd_26 : 403|5@0+ (0.35,0) [0|10.85] "mps2" Vector__XXX
 SG_ S4_SRR_RL_Obj_ValidFlag_26 : 414|1@0+ (1,0) [0|1] "" Vector__XXX
 SG_ S4_SRR_RL_Obj_UpdateFlag_26 : 413|1@0+ (1,0) [0|1] "" Vector__XXX
 SG_ S4_SRR_RL_Obj_ExistProb_26 : 412|7@0+ (1,0) [0|100] "percent" Vector__XXX
 SG_ S4_SRR_RL_Obj_Type_26 : 421|4@0+ (1,0) [0|15] "" Vector__XXX
 SG_ S4_SRR_RL_Obj_EDynProp_26 : 417|4@0+ (1,0) [0|15] "" Vector__XXX
 SG_ S4_SRR_RL_Obj_UiLifeCycles_26 : 429|7@0+ (1,0) [0|127] "" Vector__XXX
 SG_ S4_SRR_RL_Obj_RCS_26 : 438|11@0+ (0.1,-100) [-100|100] "dBm" Vector__XXX
 SG_ S4_SRR_RL_Obj_Mes_8_blockcounter : 503|4@0+ (1,0) [0|15] "" Vector__XXX
 SG_ S4_SRR_RL_Obj_8_MsgCounter : 499|4@0+ (1,0) [0|14] "" Vector__XXX
 SG_ S4_SRR_RL_Obj_8_E2EChecksum : 511|8@0+ (1,0) [0|255] "" Vector__XXX

BO_ 624 S4_SRR_RL_Obj_Mes_9: 64 SRR_RL
 SG_ S4_SRR_RL_Obj_ID_27 : 7|7@0+ (1,0) [0|126] "" Vector__XXX
 SG_ S4_SRR_RL_Obj_DistX_27 : 0|13@0+ (0.0625,-255.9375) [-255.9375|255.9375] "m" Vector__XXX
 SG_ S4_SRR_RL_Obj_RelVelX_27 : 19|11@0+ (0.125,-128) [-128|127.875] "mps" Vector__XXX
 SG_ S4_SRR_RL_Obj_AccelX_27 : 24|10@0+ (0.125,-44.5) [-44.5|44.5] "mps2" Vector__XXX
 SG_ S4_SRR_RL_Obj_DistY_27 : 46|13@0+ (0.0625,-255.9375) [-255.9375|255.9375] "m" Vector__XXX
 SG_ S4_SRR_RL_Obj_RelVelY_27 : 49|11@0+ (0.125,-128) [-128|127.875] "mps" Vector__XXX
 SG_ S4_SRR_RL_Obj_AccelY_27 : 70|10@0+ (0.125,-44.5) [-44.5|44.5] "mps2" Vector__XXX
 SG_ S4_SRR_RL_Obj_DistXStd_27 : 76|8@0+ (0.05,0) [0|12.75] "m" Vector__XXX
 SG_ S4_SRR_RL_Obj_RelVelXStd_27 : 84|6@0+ (0.2,0) [0|12.6] "mps" Vector__XXX
 SG_ S4_SRR_RL_Obj_RAccelXStd_27 : 94|5@0+ (0.35,0) [0|10.85] "mps2" Vector__XXX
 SG_ S4_SRR_RL_Obj_DistYStd_27 : 89|8@0+ (0.1,0) [0|25.5] "m" Vector__XXX
 SG_ S4_SRR_RL_Obj_RelVelYStd_27 : 97|6@0+ (0.2,0) [0|12.6] "mps" Vector__XXX
 SG_ S4_SRR_RL_Obj_RAccelYStd_27 : 107|5@0+ (0.35,0) [0|10.85] "mps2" Vector__XXX
 SG_ S4_SRR_RL_Obj_ValidFlag_27 : 118|1@0+ (1,0) [0|1] "" Vector__XXX
 SG_ S4_SRR_RL_Obj_UpdateFlag_27 : 117|1@0+ (1,0) [0|1] "" Vector__XXX
 SG_ S4_SRR_RL_Obj_ExistProb_27 : 116|7@0+ (1,0) [0|100] "percent" Vector__XXX
 SG_ S4_SRR_RL_Obj_Type_27 : 125|4@0+ (1,0) [0|15] "" Vector__XXX
 SG_ S4_SRR_RL_Obj_EDynProp_27 : 121|4@0+ (1,0) [0|15] "" Vector__XXX
 SG_ S4_SRR_RL_Obj_UiLifeCycles_27 : 133|7@0+ (1,0) [0|127] "" Vector__XXX
 SG_ S4_SRR_RL_Obj_RCS_27 : 142|11@0+ (0.1,-100) [-100|100] "dBm" Vector__XXX
 SG_ S4_SRR_RL_Obj_ID_28 : 147|7@0+ (1,0) [0|126] "" Vector__XXX
 SG_ S4_SRR_RL_Obj_DistX_28 : 156|13@0+ (0.0625,-255.9375) [-255.9375|255.9375] "m" Vector__XXX
 SG_ S4_SRR_RL_Obj_RelVelX_28 : 175|11@0+ (0.125,-128) [-128|127.875] "mps" Vector__XXX
 SG_ S4_SRR_RL_Obj_AccelX_28 : 180|10@0+ (0.125,-44.5) [-44.5|44.5] "mps2" Vector__XXX
 SG_ S4_SRR_RL_Obj_DistY_28 : 186|13@0+ (0.0625,-255.9375) [-255.9375|255.9375] "m" Vector__XXX
 SG_ S4_SRR_RL_Obj_RelVelY_28 : 205|11@0+ (0.125,-128) [-128|127.875] "mps" Vector__XXX
 SG_ S4_SRR_RL_Obj_AccelY_28 : 210|10@0+ (0.125,-44.5) [-44.5|44.5] "mps2" Vector__XXX
 SG_ S4_SRR_RL_Obj_DistXStd_28 : 216|8@0+ (0.05,0) [0|12.75] "m" Vector__XXX
 SG_ S4_SRR_RL_Obj_RelVelXStd_28 : 224|6@0+ (0.2,0) [0|12.6] "mps" Vector__XXX
 SG_ S4_SRR_RL_Obj_RAccelXStd_28 : 234|5@0+ (0.35,0) [0|10.85] "mps2" Vector__XXX
 SG_ S4_SRR_RL_Obj_DistYStd_28 : 245|8@0+ (0.1,0) [0|25.5] "m" Vector__XXX
 SG_ S4_SRR_RL_Obj_RelVelYStd_28 : 253|6@0+ (0.2,0) [0|12.6] "mps" Vector__XXX
 SG_ S4_SRR_RL_Obj_RAccelYStd_28 : 263|5@0+ (0.35,0) [0|10.85] "mps2" Vector__XXX
 SG_ S4_SRR_RL_Obj_ValidFlag_28 : 258|1@0+ (1,0) [0|1] "" Vector__XXX
 SG_ S4_SRR_RL_Obj_UpdateFlag_28 : 257|1@0+ (1,0) [0|1] "" Vector__XXX
 SG_ S4_SRR_RL_Obj_ExistProb_28 : 256|7@0+ (1,0) [0|100] "percent" Vector__XXX
 SG_ S4_SRR_RL_Obj_Type_28 : 265|4@0+ (1,0) [0|15] "" Vector__XXX
 SG_ S4_SRR_RL_Obj_EDynProp_28 : 277|4@0+ (1,0) [0|15] "" Vector__XXX
 SG_ S4_SRR_RL_Obj_UiLifeCycles_28 : 273|7@0+ (1,0) [0|127] "" Vector__XXX
 SG_ S4_SRR_RL_Obj_RCS_28 : 282|11@0+ (0.1,-100) [-100|100] "dBm" Vector__XXX
 SG_ S4_SRR_RL_Obj_ID_29 : 303|7@0+ (1,0) [0|126] "" Vector__XXX
 SG_ S4_SRR_RL_Obj_DistX_29 : 296|13@0+ (0.0625,-255.9375) [-255.9375|255.9375] "m" Vector__XXX
 SG_ S4_SRR_RL_Obj_RelVelX_29 : 315|11@0+ (0.125,-128) [-128|127.875] "mps" Vector__XXX
 SG_ S4_SRR_RL_Obj_AccelX_29 : 320|10@0+ (0.125,-44.5) [-44.5|44.5] "mps2" Vector__XXX
 SG_ S4_SRR_RL_Obj_DistY_29 : 342|13@0+ (0.0625,-255.9375) [-255.9375|255.9375] "m" Vector__XXX
 SG_ S4_SRR_RL_Obj_RelVelY_29 : 345|11@0+ (0.125,-128) [-128|127.875] "mps" Vector__XXX
 SG_ S4_SRR_RL_Obj_AccelY_29 : 366|10@0+ (0.125,-44.5) [-44.5|44.5] "mps2" Vector__XXX
 SG_ S4_SRR_RL_Obj_DistXStd_29 : 372|8@0+ (0.05,0) [0|12.75] "m" Vector__XXX
 SG_ S4_SRR_RL_Obj_RelVelXStd_29 : 380|6@0+ (0.2,0) [0|12.6] "mps" Vector__XXX
 SG_ S4_SRR_RL_Obj_RAccelXStd_29 : 390|5@0+ (0.35,0) [0|10.85] "mps2" Vector__XXX
 SG_ S4_SRR_RL_Obj_DistYStd_29 : 385|8@0+ (0.1,0) [0|25.5] "m" Vector__XXX
 SG_ S4_SRR_RL_Obj_RelVelYStd_29 : 393|6@0+ (0.2,0) [0|12.6] "mps" Vector__XXX
 SG_ S4_SRR_RL_Obj_RAccelYStd_29 : 403|5@0+ (0.35,0) [0|10.85] "mps2" Vector__XXX
 SG_ S4_SRR_RL_Obj_ValidFlag_29 : 414|1@0+ (1,0) [0|1] "" Vector__XXX
 SG_ S4_SRR_RL_Obj_UpdateFlag_29 : 413|1@0+ (1,0) [0|1] "" Vector__XXX
 SG_ S4_SRR_RL_Obj_ExistProb_29 : 412|7@0+ (1,0) [0|100] "percent" Vector__XXX
 SG_ S4_SRR_RL_Obj_Type_29 : 421|4@0+ (1,0) [0|15] "" Vector__XXX
 SG_ S4_SRR_RL_Obj_EDynProp_29 : 417|4@0+ (1,0) [0|15] "" Vector__XXX
 SG_ S4_SRR_RL_Obj_UiLifeCycles_29 : 429|7@0+ (1,0) [0|127] "" Vector__XXX
 SG_ S4_SRR_RL_Obj_RCS_29 : 438|11@0+ (0.1,-100) [-100|100] "dBm" Vector__XXX
 SG_ S4_SRR_RL_Obj_Mes_9_blockcounter : 503|4@0+ (1,0) [0|15] "" Vector__XXX
 SG_ S4_SRR_RL_Obj_9_MsgCounter : 499|4@0+ (1,0) [0|14] "" Vector__XXX
 SG_ S4_SRR_RL_Obj_9_E2EChecksum : 511|8@0+ (1,0) [0|255] "" Vector__XXX

BO_ 627 S4_SRR_RL_Obj_Mes_10: 64 SRR_RL
 SG_ S4_SRR_RL_Obj_ID_30 : 7|7@0+ (1,0) [0|126] "" Vector__XXX
 SG_ S4_SRR_RL_Obj_DistX_30 : 0|13@0+ (0.0625,-255.9375) [-255.9375|255.9375] "m" Vector__XXX
 SG_ S4_SRR_RL_Obj_RelVelX_30 : 19|11@0+ (0.125,-128) [-128|127.875] "mps" Vector__XXX
 SG_ S4_SRR_RL_Obj_AccelX_30 : 24|10@0+ (0.125,-44.5) [-44.5|44.5] "mps2" Vector__XXX
 SG_ S4_SRR_RL_Obj_DistY_30 : 46|13@0+ (0.0625,-255.9375) [-255.9375|255.9375] "m" Vector__XXX
 SG_ S4_SRR_RL_Obj_RelVelY_30 : 49|11@0+ (0.125,-128) [-128|127.875] "mps" Vector__XXX
 SG_ S4_SRR_RL_Obj_AccelY_30 : 70|10@0+ (0.125,-44.5) [-44.5|44.5] "mps2" Vector__XXX
 SG_ S4_SRR_RL_Obj_DistXStd_30 : 76|8@0+ (0.05,0) [0|12.75] "m" Vector__XXX
 SG_ S4_SRR_RL_Obj_RelVelXStd_30 : 84|6@0+ (0.2,0) [0|12.6] "mps" Vector__XXX
 SG_ S4_SRR_RL_Obj_RAccelXStd_30 : 94|5@0+ (0.35,0) [0|10.85] "mps2" Vector__XXX
 SG_ S4_SRR_RL_Obj_DistYStd_30 : 89|8@0+ (0.1,0) [0|25.5] "m" Vector__XXX
 SG_ S4_SRR_RL_Obj_RelVelYStd_30 : 97|6@0+ (0.2,0) [0|12.6] "mps" Vector__XXX
 SG_ S4_SRR_RL_Obj_RAccelYStd_30 : 107|5@0+ (0.35,0) [0|10.85] "mps2" Vector__XXX
 SG_ S4_SRR_RL_Obj_ValidFlag_30 : 118|1@0+ (1,0) [0|1] "" Vector__XXX
 SG_ S4_SRR_RL_Obj_UpdateFlag_30 : 117|1@0+ (1,0) [0|1] "" Vector__XXX
 SG_ S4_SRR_RL_Obj_ExistProb_30 : 116|7@0+ (1,0) [0|100] "percent" Vector__XXX
 SG_ S4_SRR_RL_Obj_Type_30 : 125|4@0+ (1,0) [0|15] "" Vector__XXX
 SG_ S4_SRR_RL_Obj_EDynProp_30 : 121|4@0+ (1,0) [0|15] "" Vector__XXX
 SG_ S4_SRR_RL_Obj_UiLifeCycles_30 : 133|7@0+ (1,0) [0|127] "" Vector__XXX
 SG_ S4_SRR_RL_Obj_RCS_30 : 142|11@0+ (0.1,-100) [-100|100] "dBm" Vector__XXX
 SG_ S4_SRR_RL_Obj_ID_31 : 147|7@0+ (1,0) [0|126] "" Vector__XXX
 SG_ S4_SRR_RL_Obj_DistX_31 : 156|13@0+ (0.0625,-255.9375) [-255.9375|255.9375] "m" Vector__XXX
 SG_ S4_SRR_RL_Obj_RelVelX_31 : 175|11@0+ (0.125,-128) [-128|127.875] "mps" Vector__XXX
 SG_ S4_SRR_RL_Obj_AccelX_31 : 180|10@0+ (0.125,-44.5) [-44.5|44.5] "mps2" Vector__XXX
 SG_ S4_SRR_RL_Obj_DistY_31 : 186|13@0+ (0.0625,-255.9375) [-255.9375|255.9375] "m" Vector__XXX
 SG_ S4_SRR_RL_Obj_RelVelY_31 : 205|11@0+ (0.125,-128) [-128|127.875] "mps" Vector__XXX
 SG_ S4_SRR_RL_Obj_AccelY_31 : 210|10@0+ (0.125,-44.5) [-44.5|44.5] "mps2" Vector__XXX
 SG_ S4_SRR_RL_Obj_DistXStd_31 : 216|8@0+ (0.05,0) [0|12.75] "m" Vector__XXX
 SG_ S4_SRR_RL_Obj_RelVelXStd_31 : 224|6@0+ (0.2,0) [0|12.6] "mps" Vector__XXX
 SG_ S4_SRR_RL_Obj_RAccelXStd_31 : 234|5@0+ (0.35,0) [0|10.85] "mps2" Vector__XXX
 SG_ S4_SRR_RL_Obj_DistYStd_31 : 245|8@0+ (0.1,0) [0|25.5] "m" Vector__XXX
 SG_ S4_SRR_RL_Obj_RelVelYStd_31 : 253|6@0+ (0.2,0) [0|12.6] "mps" Vector__XXX
 SG_ S4_SRR_RL_Obj_RAccelYStd_31 : 263|5@0+ (0.35,0) [0|10.85] "mps2" Vector__XXX
 SG_ S4_SRR_RL_Obj_ValidFlag_31 : 258|1@0+ (1,0) [0|1] "" Vector__XXX
 SG_ S4_SRR_RL_Obj_UpdateFlag_31 : 257|1@0+ (1,0) [0|1] "" Vector__XXX
 SG_ S4_SRR_RL_Obj_ExistProb_31 : 256|7@0+ (1,0) [0|100] "percent" Vector__XXX
 SG_ S4_SRR_RL_Obj_Type_31 : 265|4@0+ (1,0) [0|15] "" Vector__XXX
 SG_ S4_SRR_RL_Obj_EDynProp_31 : 277|4@0+ (1,0) [0|15] "" Vector__XXX
 SG_ S4_SRR_RL_Obj_UiLifeCycles_31 : 273|7@0+ (1,0) [0|127] "" Vector__XXX
 SG_ S4_SRR_RL_Obj_RCS_31 : 282|11@0+ (0.1,-100) [-100|100] "dBm" Vector__XXX
 SG_ S4_SRR_RL_Obj_ID_32 : 303|7@0+ (1,0) [0|126] "" Vector__XXX
 SG_ S4_SRR_RL_Obj_DistX_32 : 296|13@0+ (0.0625,-255.9375) [-255.9375|255.9375] "m" Vector__XXX
 SG_ S4_SRR_RL_Obj_RelVelX_32 : 315|11@0+ (0.125,-128) [-128|127.875] "mps" Vector__XXX
 SG_ S4_SRR_RL_Obj_AccelX_32 : 320|10@0+ (0.125,-44.5) [-44.5|44.5] "mps2" Vector__XXX
 SG_ S4_SRR_RL_Obj_DistY_32 : 342|13@0+ (0.0625,-255.9375) [-255.9375|255.9375] "m" Vector__XXX
 SG_ S4_SRR_RL_Obj_RelVelY_32 : 345|11@0+ (0.125,-128) [-128|127.875] "mps" Vector__XXX
 SG_ S4_SRR_RL_Obj_AccelY_32 : 366|10@0+ (0.125,-44.5) [-44.5|44.5] "mps2" Vector__XXX
 SG_ S4_SRR_RL_Obj_DistXStd_32 : 372|8@0+ (0.05,0) [0|12.75] "m" Vector__XXX
 SG_ S4_SRR_RL_Obj_RelVelXStd_32 : 380|6@0+ (0.2,0) [0|12.6] "mps" Vector__XXX
 SG_ S4_SRR_RL_Obj_RAccelXStd_32 : 390|5@0+ (0.35,0) [0|10.85] "mps2" Vector__XXX
 SG_ S4_SRR_RL_Obj_DistYStd_32 : 385|8@0+ (0.1,0) [0|25.5] "m" Vector__XXX
 SG_ S4_SRR_RL_Obj_RelVelYStd_32 : 393|6@0+ (0.2,0) [0|12.6] "mps" Vector__XXX
 SG_ S4_SRR_RL_Obj_RAccelYStd_32 : 403|5@0+ (0.35,0) [0|10.85] "mps2" Vector__XXX
 SG_ S4_SRR_RL_Obj_ValidFlag_32 : 414|1@0+ (1,0) [0|1] "" Vector__XXX
 SG_ S4_SRR_RL_Obj_UpdateFlag_32 : 413|1@0+ (1,0) [0|1] "" Vector__XXX
 SG_ S4_SRR_RL_Obj_ExistProb_32 : 412|7@0+ (1,0) [0|100] "percent" Vector__XXX
 SG_ S4_SRR_RL_Obj_Type_32 : 421|4@0+ (1,0) [0|15] "" Vector__XXX
 SG_ S4_SRR_RL_Obj_EDynProp_32 : 417|4@0+ (1,0) [0|15] "" Vector__XXX
 SG_ S4_SRR_RL_Obj_UiLifeCycles_32 : 429|7@0+ (1,0) [0|127] "" Vector__XXX
 SG_ S4_SRR_RL_Obj_RCS_32 : 438|11@0+ (0.1,-100) [-100|100] "dBm" Vector__XXX
 SG_ S4_SRR_RL_Obj_Mes_10_blockcounter : 503|4@0+ (1,0) [0|15] "" Vector__XXX
 SG_ S4_SRR_RL_Obj_10_MsgCounter : 499|4@0+ (1,0) [0|14] "" Vector__XXX
 SG_ S4_SRR_RL_Obj_10_E2EChecksum : 511|8@0+ (1,0) [0|255] "" Vector__XXX

BO_ 629 S4_SRR_RL_Obj_Mes_11: 64 SRR_RL
 SG_ S4_SRR_RL_Obj_ID_33 : 7|7@0+ (1,0) [0|126] "" Vector__XXX
 SG_ S4_SRR_RL_Obj_DistX_33 : 0|13@0+ (0.0625,-255.9375) [-255.9375|255.9375] "m" Vector__XXX
 SG_ S4_SRR_RL_Obj_RelVelX_33 : 19|11@0+ (0.125,-128) [-128|127.875] "mps" Vector__XXX
 SG_ S4_SRR_RL_Obj_AccelX_33 : 24|10@0+ (0.125,-44.5) [-44.5|44.5] "mps2" Vector__XXX
 SG_ S4_SRR_RL_Obj_DistY_33 : 46|13@0+ (0.0625,-255.9375) [-255.9375|255.9375] "m" Vector__XXX
 SG_ S4_SRR_RL_Obj_RelVelY_33 : 49|11@0+ (0.125,-128) [-128|127.875] "mps" Vector__XXX
 SG_ S4_SRR_RL_Obj_AccelY_33 : 70|10@0+ (0.125,-44.5) [-44.5|44.5] "mps2" Vector__XXX
 SG_ S4_SRR_RL_Obj_DistXStd_33 : 76|8@0+ (0.05,0) [0|12.75] "m" Vector__XXX
 SG_ S4_SRR_RL_Obj_RelVelXStd_33 : 84|6@0+ (0.2,0) [0|12.6] "mps" Vector__XXX
 SG_ S4_SRR_RL_Obj_RAccelXStd_33 : 94|5@0+ (0.35,0) [0|10.85] "mps2" Vector__XXX
 SG_ S4_SRR_RL_Obj_DistYStd_33 : 89|8@0+ (0.1,0) [0|25.5] "m" Vector__XXX
 SG_ S4_SRR_RL_Obj_RelVelYStd_33 : 97|6@0+ (0.2,0) [0|12.6] "mps" Vector__XXX
 SG_ S4_SRR_RL_Obj_RAccelYStd_33 : 107|5@0+ (0.35,0) [0|10.85] "mps2" Vector__XXX
 SG_ S4_SRR_RL_Obj_ValidFlag_33 : 118|1@0+ (1,0) [0|1] "" Vector__XXX
 SG_ S4_SRR_RL_Obj_UpdateFlag_33 : 117|1@0+ (1,0) [0|1] "" Vector__XXX
 SG_ S4_SRR_RL_Obj_ExistProb_33 : 116|7@0+ (1,0) [0|100] "percent" Vector__XXX
 SG_ S4_SRR_RL_Obj_Type_33 : 125|4@0+ (1,0) [0|15] "" Vector__XXX
 SG_ S4_SRR_RL_Obj_EDynProp_33 : 121|4@0+ (1,0) [0|15] "" Vector__XXX
 SG_ S4_SRR_RL_Obj_UiLifeCycles_33 : 133|7@0+ (1,0) [0|127] "" Vector__XXX
 SG_ S4_SRR_RL_Obj_RCS_33 : 142|11@0+ (0.1,-100) [-100|100] "dBm" Vector__XXX
 SG_ S4_SRR_RL_Obj_ID_34 : 147|7@0+ (1,0) [0|126] "" Vector__XXX
 SG_ S4_SRR_RL_Obj_DistX_34 : 156|13@0+ (0.0625,-255.9375) [-255.9375|255.9375] "m" Vector__XXX
 SG_ S4_SRR_RL_Obj_RelVelX_34 : 175|11@0+ (0.125,-128) [-128|127.875] "mps" Vector__XXX
 SG_ S4_SRR_RL_Obj_AccelX_34 : 180|10@0+ (0.125,-44.5) [-44.5|44.5] "mps2" Vector__XXX
 SG_ S4_SRR_RL_Obj_DistY_34 : 186|13@0+ (0.0625,-255.9375) [-255.9375|255.9375] "m" Vector__XXX
 SG_ S4_SRR_RL_Obj_RelVelY_34 : 205|11@0+ (0.125,-128) [-128|127.875] "mps" Vector__XXX
 SG_ S4_SRR_RL_Obj_AccelY_34 : 210|10@0+ (0.125,-44.5) [-44.5|44.5] "mps2" Vector__XXX
 SG_ S4_SRR_RL_Obj_DistXStd_34 : 216|8@0+ (0.05,0) [0|12.75] "m" Vector__XXX
 SG_ S4_SRR_RL_Obj_RelVelXStd_34 : 224|6@0+ (0.2,0) [0|12.6] "mps" Vector__XXX
 SG_ S4_SRR_RL_Obj_RAccelXStd_34 : 234|5@0+ (0.35,0) [0|10.85] "mps2" Vector__XXX
 SG_ S4_SRR_RL_Obj_DistYStd_34 : 245|8@0+ (0.1,0) [0|25.5] "m" Vector__XXX
 SG_ S4_SRR_RL_Obj_RelVelYStd_34 : 253|6@0+ (0.2,0) [0|12.6] "mps" Vector__XXX
 SG_ S4_SRR_RL_Obj_RAccelYStd_34 : 263|5@0+ (0.35,0) [0|10.85] "mps2" Vector__XXX
 SG_ S4_SRR_RL_Obj_ValidFlag_34 : 258|1@0+ (1,0) [0|1] "" Vector__XXX
 SG_ S4_SRR_RL_Obj_UpdateFlag_34 : 257|1@0+ (1,0) [0|1] "" Vector__XXX
 SG_ S4_SRR_RL_Obj_ExistProb_34 : 256|7@0+ (1,0) [0|100] "percent" Vector__XXX
 SG_ S4_SRR_RL_Obj_Type_34 : 265|4@0+ (1,0) [0|15] "" Vector__XXX
 SG_ S4_SRR_RL_Obj_EDynProp_34 : 277|4@0+ (1,0) [0|15] "" Vector__XXX
 SG_ S4_SRR_RL_Obj_UiLifeCycles_34 : 273|7@0+ (1,0) [0|127] "" Vector__XXX
 SG_ S4_SRR_RL_Obj_RCS_34 : 282|11@0+ (0.1,-100) [-100|100] "dBm" Vector__XXX
 SG_ S4_SRR_RL_Obj_ID_35 : 303|7@0+ (1,0) [0|126] "" Vector__XXX
 SG_ S4_SRR_RL_Obj_DistX_35 : 296|13@0+ (0.0625,-255.9375) [-255.9375|255.9375] "m" Vector__XXX
 SG_ S4_SRR_RL_Obj_RelVelX_35 : 315|11@0+ (0.125,-128) [-128|127.875] "mps" Vector__XXX
 SG_ S4_SRR_RL_Obj_AccelX_35 : 320|10@0+ (0.125,-44.5) [-44.5|44.5] "mps2" Vector__XXX
 SG_ S4_SRR_RL_Obj_DistY_35 : 342|13@0+ (0.0625,-255.9375) [-255.9375|255.9375] "m" Vector__XXX
 SG_ S4_SRR_RL_Obj_RelVelY_35 : 345|11@0+ (0.125,-128) [-128|127.875] "mps" Vector__XXX
 SG_ S4_SRR_RL_Obj_AccelY_35 : 366|10@0+ (0.125,-44.5) [-44.5|44.5] "mps2" Vector__XXX
 SG_ S4_SRR_RL_Obj_DistXStd_35 : 372|8@0+ (0.05,0) [0|12.75] "m" Vector__XXX
 SG_ S4_SRR_RL_Obj_RelVelXStd_35 : 380|6@0+ (0.2,0) [0|12.6] "mps" Vector__XXX
 SG_ S4_SRR_RL_Obj_RAccelXStd_35 : 390|5@0+ (0.35,0) [0|10.85] "mps2" Vector__XXX
 SG_ S4_SRR_RL_Obj_DistYStd_35 : 385|8@0+ (0.1,0) [0|25.5] "m" Vector__XXX
 SG_ S4_SRR_RL_Obj_RelVelYStd_35 : 393|6@0+ (0.2,0) [0|12.6] "mps" Vector__XXX
 SG_ S4_SRR_RL_Obj_RAccelYStd_35 : 403|5@0+ (0.35,0) [0|10.85] "mps2" Vector__XXX
 SG_ S4_SRR_RL_Obj_ValidFlag_35 : 414|1@0+ (1,0) [0|1] "" Vector__XXX
 SG_ S4_SRR_RL_Obj_UpdateFlag_35 : 413|1@0+ (1,0) [0|1] "" Vector__XXX
 SG_ S4_SRR_RL_Obj_ExistProb_35 : 412|7@0+ (1,0) [0|100] "percent" Vector__XXX
 SG_ S4_SRR_RL_Obj_Type_35 : 421|4@0+ (1,0) [0|15] "" Vector__XXX
 SG_ S4_SRR_RL_Obj_EDynProp_35 : 417|4@0+ (1,0) [0|15] "" Vector__XXX
 SG_ S4_SRR_RL_Obj_UiLifeCycles_35 : 429|7@0+ (1,0) [0|127] "" Vector__XXX
 SG_ S4_SRR_RL_Obj_RCS_35 : 438|11@0+ (0.1,-100) [-100|100] "dBm" Vector__XXX
 SG_ S4_SRR_RL_Obj_Mes_11_blockcounter : 503|4@0+ (1,0) [0|15] "" Vector__XXX
 SG_ S4_SRR_RL_Obj_11_MsgCounter : 499|4@0+ (1,0) [0|14] "" Vector__XXX
 SG_ S4_SRR_RL_Obj_11_E2EChecksum : 511|8@0+ (1,0) [0|255] "" Vector__XXX

BO_ 630 S4_SRR_RL_Obj_Mes_12: 64 SRR_RL
 SG_ S4_SRR_RL_Obj_ID_36 : 7|7@0+ (1,0) [0|126] "" Vector__XXX
 SG_ S4_SRR_RL_Obj_DistX_36 : 0|13@0+ (0.0625,-255.9375) [-255.9375|255.9375] "m" Vector__XXX
 SG_ S4_SRR_RL_Obj_RelVelX_36 : 19|11@0+ (0.125,-128) [-128|127.875] "mps" Vector__XXX
 SG_ S4_SRR_RL_Obj_AccelX_36 : 24|10@0+ (0.125,-44.5) [-44.5|44.5] "mps2" Vector__XXX
 SG_ S4_SRR_RL_Obj_DistY_36 : 46|13@0+ (0.0625,-255.9375) [-255.9375|255.9375] "m" Vector__XXX
 SG_ S4_SRR_RL_Obj_RelVelY_36 : 49|11@0+ (0.125,-128) [-128|127.875] "mps" Vector__XXX
 SG_ S4_SRR_RL_Obj_AccelY_36 : 70|10@0+ (0.125,-44.5) [-44.5|44.5] "mps2" Vector__XXX
 SG_ S4_SRR_RL_Obj_DistXStd_36 : 76|8@0+ (0.05,0) [0|12.75] "m" Vector__XXX
 SG_ S4_SRR_RL_Obj_RelVelXStd_36 : 84|6@0+ (0.2,0) [0|12.6] "mps" Vector__XXX
 SG_ S4_SRR_RL_Obj_RAccelXStd_36 : 94|5@0+ (0.35,0) [0|10.85] "mps2" Vector__XXX
 SG_ S4_SRR_RL_Obj_DistYStd_36 : 89|8@0+ (0.1,0) [0|25.5] "m" Vector__XXX
 SG_ S4_SRR_RL_Obj_RelVelYStd_36 : 97|6@0+ (0.2,0) [0|12.6] "mps" Vector__XXX
 SG_ S4_SRR_RL_Obj_RAccelYStd_36 : 107|5@0+ (0.35,0) [0|10.85] "mps2" Vector__XXX
 SG_ S4_SRR_RL_Obj_ValidFlag_36 : 118|1@0+ (1,0) [0|1] "" Vector__XXX
 SG_ S4_SRR_RL_Obj_UpdateFlag_36 : 117|1@0+ (1,0) [0|1] "" Vector__XXX
 SG_ S4_SRR_RL_Obj_ExistProb_36 : 116|7@0+ (1,0) [0|100] "percent" Vector__XXX
 SG_ S4_SRR_RL_Obj_Type_36 : 125|4@0+ (1,0) [0|15] "" Vector__XXX
 SG_ S4_SRR_RL_Obj_EDynProp_36 : 121|4@0+ (1,0) [0|15] "" Vector__XXX
 SG_ S4_SRR_RL_Obj_UiLifeCycles_36 : 133|7@0+ (1,0) [0|127] "" Vector__XXX
 SG_ S4_SRR_RL_Obj_RCS_36 : 142|11@0+ (0.1,-100) [-100|100] "dBm" Vector__XXX
 SG_ S4_SRR_RL_Obj_ID_37 : 147|7@0+ (1,0) [0|126] "" Vector__XXX
 SG_ S4_SRR_RL_Obj_DistX_37 : 156|13@0+ (0.0625,-255.9375) [-255.9375|255.9375] "m" Vector__XXX
 SG_ S4_SRR_RL_Obj_RelVelX_37 : 175|11@0+ (0.125,-128) [-128|127.875] "mps" Vector__XXX
 SG_ S4_SRR_RL_Obj_AccelX_37 : 180|10@0+ (0.125,-44.5) [-44.5|44.5] "mps2" Vector__XXX
 SG_ S4_SRR_RL_Obj_DistY_37 : 186|13@0+ (0.0625,-255.9375) [-255.9375|255.9375] "m" Vector__XXX
 SG_ S4_SRR_RL_Obj_RelVelY_37 : 205|11@0+ (0.125,-128) [-128|127.875] "mps" Vector__XXX
 SG_ S4_SRR_RL_Obj_AccelY_37 : 210|10@0+ (0.125,-44.5) [-44.5|44.5] "mps2" Vector__XXX
 SG_ S4_SRR_RL_Obj_DistXStd_37 : 216|8@0+ (0.05,0) [0|12.75] "m" Vector__XXX
 SG_ S4_SRR_RL_Obj_RelVelXStd_37 : 224|6@0+ (0.2,0) [0|12.6] "mps" Vector__XXX
 SG_ S4_SRR_RL_Obj_RAccelXStd_37 : 234|5@0+ (0.35,0) [0|10.85] "mps2" Vector__XXX
 SG_ S4_SRR_RL_Obj_DistYStd_37 : 245|8@0+ (0.1,0) [0|25.5] "m" Vector__XXX
 SG_ S4_SRR_RL_Obj_RelVelYStd_37 : 253|6@0+ (0.2,0) [0|12.6] "mps" Vector__XXX
 SG_ S4_SRR_RL_Obj_RAccelYStd_37 : 263|5@0+ (0.35,0) [0|10.85] "mps2" Vector__XXX
 SG_ S4_SRR_RL_Obj_ValidFlag_37 : 258|1@0+ (1,0) [0|1] "" Vector__XXX
 SG_ S4_SRR_RL_Obj_UpdateFlag_37 : 257|1@0+ (1,0) [0|1] "" Vector__XXX
 SG_ S4_SRR_RL_Obj_ExistProb_37 : 256|7@0+ (1,0) [0|100] "percent" Vector__XXX
 SG_ S4_SRR_RL_Obj_Type_37 : 265|4@0+ (1,0) [0|15] "" Vector__XXX
 SG_ S4_SRR_RL_Obj_EDynProp_37 : 277|4@0+ (1,0) [0|15] "" Vector__XXX
 SG_ S4_SRR_RL_Obj_UiLifeCycles_37 : 273|7@0+ (1,0) [0|127] "" Vector__XXX
 SG_ S4_SRR_RL_Obj_RCS_37 : 282|11@0+ (0.1,-100) [-100|100] "dBm" Vector__XXX
 SG_ S4_SRR_RL_Obj_ID_38 : 303|7@0+ (1,0) [0|126] "" Vector__XXX
 SG_ S4_SRR_RL_Obj_DistX_38 : 296|13@0+ (0.0625,-255.9375) [-255.9375|255.9375] "m" Vector__XXX
 SG_ S4_SRR_RL_Obj_RelVelX_38 : 315|11@0+ (0.125,-128) [-128|127.875] "mps" Vector__XXX
 SG_ S4_SRR_RL_Obj_AccelX_38 : 320|10@0+ (0.125,-44.5) [-44.5|44.5] "mps2" Vector__XXX
 SG_ S4_SRR_RL_Obj_DistY_38 : 342|13@0+ (0.0625,-255.9375) [-255.9375|255.9375] "m" Vector__XXX
 SG_ S4_SRR_RL_Obj_RelVelY_38 : 345|11@0+ (0.125,-128) [-128|127.875] "mps" Vector__XXX
 SG_ S4_SRR_RL_Obj_AccelY_38 : 366|10@0+ (0.125,-44.5) [-44.5|44.5] "mps2" Vector__XXX
 SG_ S4_SRR_RL_Obj_DistXStd_38 : 372|8@0+ (0.05,0) [0|12.75] "m" Vector__XXX
 SG_ S4_SRR_RL_Obj_RelVelXStd_38 : 380|6@0+ (0.2,0) [0|12.6] "mps" Vector__XXX
 SG_ S4_SRR_RL_Obj_RAccelXStd_38 : 390|5@0+ (0.35,0) [0|10.85] "mps2" Vector__XXX
 SG_ S4_SRR_RL_Obj_DistYStd_38 : 385|8@0+ (0.1,0) [0|25.5] "m" Vector__XXX
 SG_ S4_SRR_RL_Obj_RelVelYStd_38 : 393|6@0+ (0.2,0) [0|12.6] "mps" Vector__XXX
 SG_ S4_SRR_RL_Obj_RAccelYStd_38 : 403|5@0+ (0.35,0) [0|10.85] "mps2" Vector__XXX
 SG_ S4_SRR_RL_Obj_ValidFlag_38 : 414|1@0+ (1,0) [0|1] "" Vector__XXX
 SG_ S4_SRR_RL_Obj_UpdateFlag_38 : 413|1@0+ (1,0) [0|1] "" Vector__XXX
 SG_ S4_SRR_RL_Obj_ExistProb_38 : 412|7@0+ (1,0) [0|100] "percent" Vector__XXX
 SG_ S4_SRR_RL_Obj_Type_38 : 421|4@0+ (1,0) [0|15] "" Vector__XXX
 SG_ S4_SRR_RL_Obj_EDynProp_38 : 417|4@0+ (1,0) [0|15] "" Vector__XXX
 SG_ S4_SRR_RL_Obj_UiLifeCycles_38 : 429|7@0+ (1,0) [0|127] "" Vector__XXX
 SG_ S4_SRR_RL_Obj_RCS_38 : 438|11@0+ (0.1,-100) [-100|100] "dBm" Vector__XXX
 SG_ S4_SRR_RL_Obj_Mes_12_blockcounter : 503|4@0+ (1,0) [0|15] "" Vector__XXX
 SG_ S4_SRR_RL_Obj_12_MsgCounter : 499|4@0+ (1,0) [0|14] "" Vector__XXX
 SG_ S4_SRR_RL_Obj_12_E2EChecksum : 511|8@0+ (1,0) [0|255] "" Vector__XXX

BO_ 631 S4_SRR_RL_Obj_Mes_13: 64 SRR_RL
 SG_ S4_SRR_RL_Obj_ID_39 : 7|7@0+ (1,0) [0|126] "" Vector__XXX
 SG_ S4_SRR_RL_Obj_DistX_39 : 0|13@0+ (0.0625,-255.9375) [-255.9375|255.9375] "m" Vector__XXX
 SG_ S4_SRR_RL_Obj_RelVelX_39 : 19|11@0+ (0.125,-128) [-128|127.875] "mps" Vector__XXX
 SG_ S4_SRR_RL_Obj_AccelX_39 : 24|10@0+ (0.125,-44.5) [-44.5|44.5] "mps2" Vector__XXX
 SG_ S4_SRR_RL_Obj_DistY_39 : 46|13@0+ (0.0625,-255.9375) [-255.9375|255.9375] "m" Vector__XXX
 SG_ S4_SRR_RL_Obj_RelVelY_39 : 49|11@0+ (0.125,-128) [-128|127.875] "mps" Vector__XXX
 SG_ S4_SRR_RL_Obj_AccelY_39 : 70|10@0+ (0.125,-44.5) [-44.5|44.5] "mps2" Vector__XXX
 SG_ S4_SRR_RL_Obj_DistXStd_39 : 76|8@0+ (0.05,0) [0|12.75] "m" Vector__XXX
 SG_ S4_SRR_RL_Obj_RelVelXStd_39 : 84|6@0+ (0.2,0) [0|12.6] "mps" Vector__XXX
 SG_ S4_SRR_RL_Obj_RAccelXStd_39 : 94|5@0+ (0.35,0) [0|10.85] "mps2" Vector__XXX
 SG_ S4_SRR_RL_Obj_DistYStd_39 : 89|8@0+ (0.1,0) [0|25.5] "m" Vector__XXX
 SG_ S4_SRR_RL_Obj_RelVelYStd_39 : 97|6@0+ (0.2,0) [0|12.6] "mps" Vector__XXX
 SG_ S4_SRR_RL_Obj_RAccelYStd_39 : 107|5@0+ (0.35,0) [0|10.85] "mps2" Vector__XXX
 SG_ S4_SRR_RL_Obj_ValidFlag_39 : 118|1@0+ (1,0) [0|1] "" Vector__XXX
 SG_ S4_SRR_RL_Obj_UpdateFlag_39 : 117|1@0+ (1,0) [0|1] "" Vector__XXX
 SG_ S4_SRR_RL_Obj_ExistProb_39 : 116|7@0+ (1,0) [0|100] "percent" Vector__XXX
 SG_ S4_SRR_RL_Obj_Type_39 : 125|4@0+ (1,0) [0|15] "" Vector__XXX
 SG_ S4_SRR_RL_Obj_EDynProp_39 : 121|4@0+ (1,0) [0|15] "" Vector__XXX
 SG_ S4_SRR_RL_Obj_UiLifeCycles_39 : 133|7@0+ (1,0) [0|127] "" Vector__XXX
 SG_ S4_SRR_RL_Obj_RCS_39 : 142|11@0+ (0.1,-100) [-100|100] "dBm" Vector__XXX
 SG_ S4_SRR_RL_Obj_Mes_13_blockcounter : 503|4@0+ (1,0) [0|15] "" Vector__XXX
 SG_ S4_SRR_RL_Obj_13_MsgCounter : 499|4@0+ (1,0) [0|14] "" Vector__XXX
 SG_ S4_SRR_RL_Obj_13_E2EChecksum : 511|8@0+ (1,0) [0|255] "" Vector__XXX

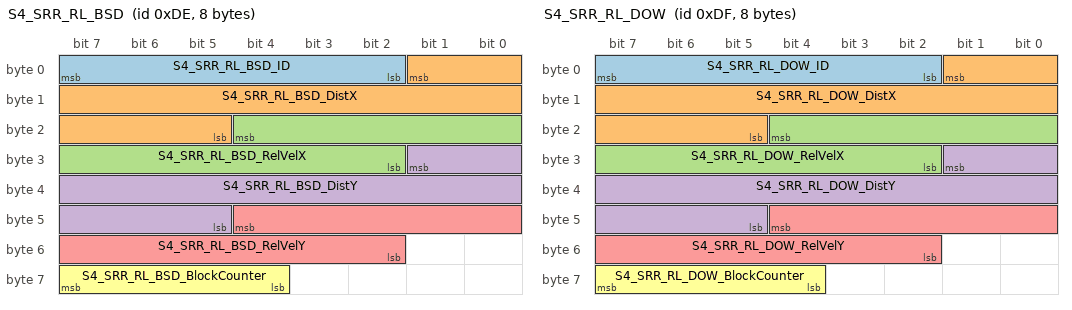
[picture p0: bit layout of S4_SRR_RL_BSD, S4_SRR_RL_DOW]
BO_ 222 S4_SRR_RL_BSD: 8 SRR_RL
 SG_ S4_SRR_RL_BSD_ID : 7|6@0+ (1,0) [0|62] "" Vector__XXX
 SG_ S4_SRR_RL_BSD_DistX : 1|13@0+ (0.0625,-255.9375) [-255.9375|255.9375] "" Vector__XXX
 SG_ S4_SRR_RL_BSD_RelVelX : 20|11@0+ (0.125,-128) [-128|127.875] "" Vector__XXX
 SG_ S4_SRR_RL_BSD_DistY : 25|13@0+ (0.0625,-255.9375) [-255.9375|255.9375] "" Vector__XXX
 SG_ S4_SRR_RL_BSD_RelVelY : 44|11@0+ (0.125,-128) [-128|127.875] "" Vector__XXX
 SG_ S4_SRR_RL_BSD_BlockCounter : 63|4@0+ (1,0) [0|15] "" Vector__XXX

BO_ 223 S4_SRR_RL_DOW: 8 SRR_RL
 SG_ S4_SRR_RL_DOW_ID : 7|6@0+ (1,0) [0|62] "" Vector__XXX
 SG_ S4_SRR_RL_DOW_DistX : 1|13@0+ (0.0625,-255.9375) [-255.9375|255.9375] "" Vector__XXX
 SG_ S4_SRR_RL_DOW_RelVelX : 20|11@0+ (0.125,-128) [-128|127.875] "" Vector__XXX
 SG_ S4_SRR_RL_DOW_DistY : 25|13@0+ (0.0625,-255.9375) [-255.9375|255.9375] "" Vector__XXX
 SG_ S4_SRR_RL_DOW_RelVelY : 44|11@0+ (0.125,-128) [-128|127.875] "" Vector__XXX
 SG_ S4_SRR_RL_DOW_BlockCounter : 63|4@0+ (1,0) [0|15] "" Vector__XXX

BO_ 634 S4_SRR_RL_AssistSysSt: 24 SRR_RL
 SG_ S4_SRR_RL_Clu_Valid : 7|1@0+ (1,0) [0|1] "" Vector__XXX
 SG_ S4_SRR_RL_Obj_Valid : 6|1@0+ (1,0) [0|1] "" Vector__XXX
 SG_ S4_SRR_RL_HWFailureSt : 4|1@0+ (1,0) [0|1] "" Vector__XXX
 SG_ S4_SRR_RL_EolHoriAng : 2|11@0+ (0.01,-10) [-10|10] "" Vector__XXX
 SG_ S4_SRR_RL_OnlineHoriAng : 28|11@0+ (0.01,-10) [-10|10] "" Vector__XXX
 SG_ S4_SRR_RL_MisAliSt : 54|1@0+ (1,0) [0|1] "" Vector__XXX
 SG_ S4_SRR_RL_BlockSt : 53|1@0+ (1,0) [0|1] "" Vector__XXX
 SG_ S4_SRR_RL_ICTemp : 52|8@0+ (1,-50) [-50|205] "deg" Vector__XXX
 SG_ S4_SRR_RL_TempOutofRange : 60|1@0+ (1,0) [0|1] "" Vector__XXX
 SG_ S4_SRR_RL_Modulation_Status : 59|2@0+ (1,0) [0|3] "" Vector__XXX
 SG_ S4_SRR_RL_BSDLeftSt : 44|3@0+ (1,0) [0|7] "" Vector__XXX
 SG_ S4_SRR_RL_BSDLeftWarning : 71|2@0+ (1,0) [0|3] "" Vector__XXX
 SG_ S4_SRR_RL_DOWLeft : 47|3@0+ (1,0) [0|7] "" Vector__XXX
 SG_ S4_SRR_RL_DOWLeftWarning : 67|2@0+ (1,0) [0|3] "" Vector__XXX
 SG_ S4_SRR_RL_RCTALeftSt : 79|3@0+ (1,0) [0|7] "" Vector__XXX
 SG_ S4_SRR_RL_RCTALeftWarning : 65|2@0+ (1,0) [0|3] "" Vector__XXX
 SG_ S4_SRR_RL_RCWLeftSt : 76|3@0+ (1,0) [0|7] "" Vector__XXX
 SG_ S4_SRR_RL_RCWLeftWarn : 73|2@0+ (1,0) [0|3] "" Vector__XXX
 SG_ S4_SRR_RL_TStampGlobNsec_ObjSt : 87|32@0+ (1,0) [0|4294967295] "ns" Vector__XXX
 SG_ S4_SRR_RL_TStampGlobsec_ObjSt : 119|32@0+ (1,0) [0|4294967295] "s" Vector__XXX
 SG_ S4_SRR_RL_CalibratedSt : 31|3@0+ (1,0) [0|7] "" Vector__XXX
 SG_ S4_SRR_RL_RadarEmissionSt : 41|3@0+ (1,0) [0|7] "" Vector__XXX
 SG_ S4_SRR_RL_DataUpload_St : 23|3@0+ (1,0) [0|7] "" Vector__XXX
 SG_ S4_SRR_RL_EolVerAng : 151|11@0+ (0.01,-5) [-5|5] "" Vector__XXX
 SG_ S4_SRR_RL_OnlineVerAng : 156|11@0+ (0.01,-5) [-5|5] "" Vector__XXX
 SG_ S4_SRR_RL_Assist_MsgCounter : 175|8@0+ (1,0) [0|255] "" Vector__XXX
 SG_ S4_SRR_RL_Assist_CRC16Checksum : 183|16@0+ (1,0) [0|65535] "" Vector__XXX
 SG_ S4_SRR_RL_InitialState : 20|3@0+ (1,0) [0|3] "" Vector__XXX

BO_ 950 S4_SRR_RL_DTC: 16 SRR_RL
 SG_ S4_SRR_RL_VBAT_HIGH : 0|1@0+ (1,0) [0|1] "" Vector__XXX
 SG_ S4_SRR_RL_VBAT_LOW : 1|1@0+ (1,0) [0|1] "" Vector__XXX
 SG_ S4_SRR_RL_SFCAN_CANBUS : 2|1@0+ (1,0) [0|1] "" Vector__XXX
 SG_ S4_SRR_RL_XPU_TIMEOUT : 3|1@0+ (1,0) [0|1] "" Vector__XXX
 SG_ S4_SRR_RL_OVERTEMP_FAIL : 4|1@0+ (1,0) [0|1] "" Vector__XXX
 SG_ S4_SRR_RL_UNDERTEMP_FAIL : 5|1@0+ (1,0) [0|1] "" Vector__XXX
 SG_ S4_SRR_RL_RFCOM_ERROR : 6|1@0+ (1,0) [0|1] "" Vector__XXX
 SG_ S4_SRR_RL_SPT_ERROR : 7|1@0+ (1,0) [0|1] "" Vector__XXX
 SG_ S4_SRR_RL_RFWAVE_CHECK_ERROR : 8|1@0+ (1,0) [0|1] "" Vector__XXX
 SG_ S4_SRR_RL_SWEXETIMING_VIOLATION : 9|1@0+ (1,0) [0|1] "" Vector__XXX
 SG_ S4_SRR_RL_SRR_PERMHW_FAIL : 10|1@0+ (1,0) [0|1] "" Vector__XXX
 SG_ S4_SRR_RL_ECU_SELFTEST_FAIL : 11|1@0+ (1,0) [0|1] "" Vector__XXX
 SG_ S4_SRR_RL_SWHW_COMPAT_CHECK : 12|1@0+ (1,0) [0|1] "" Vector__XXX
 SG_ S4_SRR_RL_PLCM_SYS_ERROR : 13|1@0+ (1,0) [0|1] "" Vector__XXX
 SG_ S4_SRR_RL_RF_VOLT_FAULT : 14|1@0+ (1,0) [0|1] "" Vector__XXX
 SG_ S4_SRR_RL_RF_TEMP_FAULT : 15|1@0+ (1,0) [0|1] "" Vector__XXX
 SG_ S4_SRR_RL_SRR_NVM_FAIL : 16|1@0+ (1,0) [0|1] "" Vector__XXX
 SG_ S4_SRR_RL_TIME_SYN_FAIL : 17|1@0+ (1,0) [0|1] "" Vector__XXX
 SG_ S4_SRR_RL_SRR_POSNOTCONFIG : 18|1@0+ (1,0) [0|1] "" Vector__XXX
 SG_ S4_SRR_RL_SRR_POSCONFIG_FAIL : 19|1@0+ (1,0) [0|1] "" Vector__XXX
 SG_ S4_SRR_RL_SRR_POSCONFIG_UPDATE : 20|1@0+ (1,0) [0|1] "" Vector__XXX
 SG_ S4_SRR_RL_SRR_VDY_SIG_EXCEPTION : 21|1@0+ (1,0) [0|1] "" Vector__XXX
 SG_ S4_SRR_RL_CDCU_TotOdo_Miss_ERR : 22|1@0+ (1,0) [0|1] "" Vector__XXX
 SG_ S4_SRR_RL_LDCU_SysSt_Miss_ERR : 23|1@0+ (1,0) [0|1] "" Vector__XXX
 SG_ S4_SRR_RL_LDCU_BSysSt1_Miss_ERR : 24|1@0+ (1,0) [0|1] "" Vector__XXX
 SG_ S4_SRR_RL_RDCU_BSysSt1_Miss_ERR : 25|1@0+ (1,0) [0|1] "" Vector__XXX
 SG_ S4_SRR_RL_RDCU_BSysSt2_Miss_ERR : 26|1@0+ (1,0) [0|1] "" Vector__XXX
 SG_ S4_SRR_RL_ESP_SpdInfoF_Miss_ERR : 27|1@0+ (1,0) [0|1] "" Vector__XXX
 SG_ S4_SRR_RL_ESP_SpdInfoR_ERR : 28|1@0+ (1,0) [0|1] "" Vector__XXX
 SG_ S4_SRR_RL_ESP_SysSt_ERR : 29|1@0+ (1,0) [0|1] "" Vector__XXX
 SG_ S4_SRR_RL_ESP_Accel_ERR : 30|1@0+ (1,0) [0|1] "" Vector__XXX
 SG_ S4_SRR_RL_ESP_AccelOffset_ERR : 31|1@0+ (1,0) [0|1] "" Vector__XXX
 SG_ S4_SRR_RL_EPS_SASInfo_ERR : 32|1@0+ (1,0) [0|1] "" Vector__XXX
 SG_ S4_SRR_RL_TBOX_TimeInfo_ERR : 33|1@0+ (1,0) [0|1] "" Vector__XXX
 SG_ S4_SRR_RL_TBOX_GPSInfo_ERR : 34|1@0+ (1,0) [0|1] "" Vector__XXX
 SG_ S4_SRR_RL_LDCU_ALC_ERR : 35|1@0+ (1,0) [0|1] "" Vector__XXX
 SG_ S4_SRR_RL_ESP_ALC_ERR : 36|1@0+ (1,0) [0|1] "" Vector__XXX
 SG_ S4_SRR_RL_EPS_ALC_ERR : 37|1@0+ (1,0) [0|1] "" Vector__XXX
 SG_ S4_SRR_RL_XPU_ALC_ERR : 38|1@0+ (1,0) [0|1] "" Vector__XXX
 SG_ S4_SRR_RL_LDCU_CRC_ERR : 39|1@0+ (1,0) [0|1] "" Vector__XXX
 SG_ S4_SRR_RL_ESP_CRC_ERR : 40|1@0+ (1,0) [0|1] "" Vector__XXX
 SG_ S4_SRR_RL_EPS_CRC_ERR : 41|1@0+ (1,0) [0|1] "" Vector__XXX
 SG_ S4_SRR_RL_XPU_CRC_ERR : 42|1@0+ (1,0) [0|1] "" Vector__XXX
 SG_ S4_SRR_RL_ESP_WHLSPD_INVALID : 43|1@0+ (1,0) [0|1] "" Vector__XXX
 SG_ S4_SRR_RL_EPS_SASFAULT_INVALID : 44|1@0+ (1,0) [0|1] "" Vector__XXX
 SG_ S4_SRR_RL_ESP_LGTACCE_INVALID : 45|1@0+ (1,0) [0|1] "" Vector__XXX
 SG_ S4_SRR_RL_ESP_LATACCE_INVALID : 46|1@0+ (1,0) [0|1] "" Vector__XXX
 SG_ S4_SRR_RL_ESP_YAWRATE_INVALID : 47|1@0+ (1,0) [0|1] "" Vector__XXX
 SG_ S4_SRR_RL_ESP_WHLMOVGDIR_IVD : 48|1@0+ (1,0) [0|1] "" Vector__XXX
 SG_ S4_SRR_RL_EPS_SAVD_INVALID : 49|1@0+ (1,0) [0|1] "" Vector__XXX
 SG_ S4_SRR_RL_EPS_SASCALST_INVALID : 50|1@0+ (1,0) [0|1] "" Vector__XXX
 SG_ S4_SRR_RL_LDCU_CurGearLev_ivd : 51|1@0+ (1,0) [0|1] "" Vector__XXX
 SG_ S4_SRR_RL_LDCU_AccPedalSig_IVD : 52|1@0+ (1,0) [0|1] "" Vector__XXX
 SG_ S4_SRR_RL_LDCU_BrkPedalSt_IVD : 53|1@0+ (1,0) [0|1] "" Vector__XXX
 SG_ S4_SRR_RL_EPS_SASPDSIG_IVD : 54|1@0+ (1,0) [0|1] "" Vector__XXX
 SG_ S4_SRR_RL_SRR_BLIND_FAIL : 55|1@0+ (1,0) [0|1] "" Vector__XXX
 SG_ S4_SRR_RL_SENSOR_POS_FAIL : 56|1@0+ (1,0) [0|1] "" Vector__XXX
 SG_ S4_SRR_RL_SRR_NOT_ALN_FAIL : 57|1@0+ (1,0) [0|1] "" Vector__XXX
 SG_ S4_SRR_RL_SENSOR_MISALN_FAIL : 58|1@0+ (1,0) [0|1] "" Vector__XXX
 SG_ S4_SRR_RL_Distortion_Flag : 59|1@0+ (1,0) [0|1] "" Vector__XXX
 SG_ S4_SRR_RL_Absorption_Flag : 60|1@0+ (1,0) [0|1] "" Vector__XXX
 SG_ S4_SRR_RL_Distortion_Indicator : 71|8@0+ (0.01,0) [0|1] "" Vector__XXX
 SG_ S4_SRR_RL_Absorption_Indicator : 79|8@0+ (0.01,0) [0|1] "" Vector__XXX
 SG_ S4_SRR_RL_Location_Num : 87|8@0+ (1,0) [0|255] "" Vector__XXX
 SG_ S4_SRR_RL_Object_Num : 95|8@0+ (1,0) [0|255] "" Vector__XXX
 SG_ S4_SRR_RL_Driverset_Active_FAIL : 61|1@0+ (1,0) [0|1] "" Vector__XXX
 SG_ S4_SRR_RL_Production_Data_FAIL : 62|1@0+ (1,0) [0|1] "" Vector__XXX
 SG_ S4_SRR_RL_Powermanege_Over_Voltage_FAIL : 63|1@0+ (1,0) [0|1] "" Vector__XXX
 SG_ S4_SRR_RL_MMIC_Over_Voltage_FAIL : 96|1@0+ (1,0) [0|1] "" Vector__XXX
 SG_ S4_SRR_RL_Powermanege_Under_Voltage_FAIL : 97|1@0+ (1,0) [0|1] "" Vector__XXX
 SG_ S4_SRR_RL_MMIC_Under_Voltage_FAIL : 98|1@0+ (1,0) [0|1] "" Vector__XXX
 SG_ S4_SRR_RL_Modulation_config_FAIL : 99|1@0+ (1,0) [0|1] "" Vector__XXX
 SG_ S4_SRR_RL_Modulation_FAIL : 100|1@0+ (1,0) [0|1] "" Vector__XXX
 SG_ S4_SRR_RL_SW_FAIL : 101|1@0+ (1,0) [0|1] "" Vector__XXX
 SG_ S4_SRR_RL_SW_TEMP_FAIL : 102|1@0+ (1,0) [0|1] "" Vector__XXX
 SG_ S4_SRR_RL_UC_Over_TEMP_FAIL : 103|1@0+ (1,0) [0|1] "" Vector__XXX
 SG_ S4_SRR_RL_Radar_HW_FAIL : 104|1@0+ (1,0) [0|1] "" Vector__XXX
 SG_ S4_SRR_RL_Production_Mode_FAIL : 105|1@0+ (1,0) [0|1] "" Vector__XXX
 SG_ S4_SRR_RL_SYNC_timebase_FAIL : 106|1@0+ (1,0) [0|1] "" Vector__XXX
 SG_ S4_SRR_RL_SYNC_timeout_FAIL : 107|1@0+ (1,0) [0|1] "" Vector__XXX
 SG_ S4_SRR_RL_SYNC_timeleap_FAIL : 108|1@0+ (1,0) [0|1] "" Vector__XXX
 SG_ S4_SRR_RL_Variant_FAIL : 109|1@0+ (1,0) [0|1] "" Vector__XXX
 SG_ S4_SRR_RL_ESP_SysSt_E2E_ERR : 110|1@0+ (1,0) [0|1] "" Vector__XXX
 SG_ S4_SRR_RL_AS_SysSt1_Missing_ERR : 111|1@0+ (1,0) [0|1] "" Vector__XXX
 SG_ S4_SRR_RL_AS_SysSt2_Missing_ERR : 112|1@0+ (1,0) [0|1] "" Vector__XXX
 SG_ S4_SRR_RL_RWS_Sys_Missing_ERR : 113|1@0+ (1,0) [0|1] "" Vector__XXX
 SG_ S4_SRR_RL_RWS_CRC_ERR : 114|1@0+ (1,0) [0|1] "" Vector__XXX
 SG_ S4_SRR_RL_RWS_ALC_ERR : 115|1@0+ (1,0) [0|1] "" Vector__XXX
 SG_ S4_SRR_RL_IPB_Wheelspd_INVALID : 116|1@0+ (1,0) [0|1] "" Vector__XXX
 SG_ S4_SRR_RL_ESP_ABS_fault : 117|1@0+ (1,0) [0|1] "" Vector__XXX
 SG_ S4_SRR_RL_ESP_Standstill_INVALID : 118|1@0+ (1,0) [0|1] "" Vector__XXX
 SG_ S4_SRR_RL_IPB_LGTACCE_INVALID : 119|1@0+ (1,0) [0|1] "" Vector__XXX
 SG_ S4_SRR_RL_IPB_LATACCE_INVALID : 120|1@0+ (1,0) [0|1] "" Vector__XXX
 SG_ S4_SRR_RL_IPB_YAWRATE_INVALID : 121|1@0+ (1,0) [0|1] "" Vector__XXX
 SG_ S4_SRR_RL_AS_level_invalid : 122|1@0+ (1,0) [0|1] "" Vector__XXX
 SG_ S4_SRR_RL_RWS_wheelangle_invalid : 123|1@0+ (1,0) [0|1] "" Vector__XXX

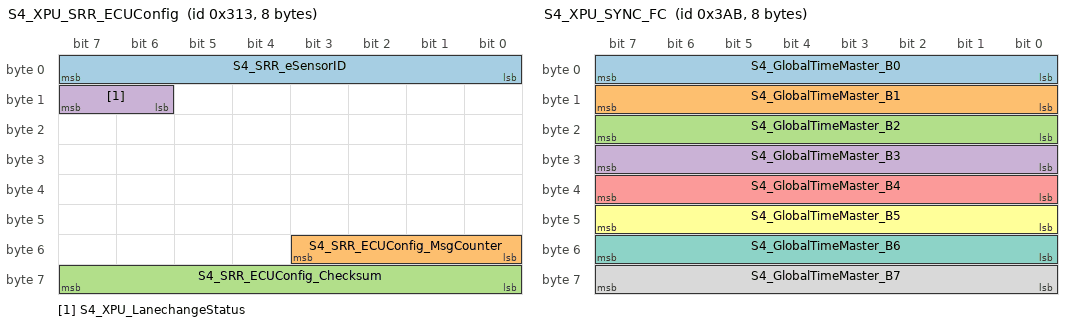
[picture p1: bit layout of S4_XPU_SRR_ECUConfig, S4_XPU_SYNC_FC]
BO_ 787 S4_XPU_SRR_ECUConfig: 8 XPU
 SG_ S4_SRR_eSensorID : 7|8@0+ (1,0) [0|255] "" SRR_RL
 SG_ S4_SRR_ECUConfig_MsgCounter : 51|4@0+ (1,0) [0|15] "" SRR_RL
 SG_ S4_SRR_ECUConfig_Checksum : 63|8@0+ (1,0) [0|255] "" SRR_RL
 SG_ S4_XPU_LanechangeStatus : 15|2@0+ (1,0) [0|3] "" SRR_RL

BO_ 939 S4_XPU_SYNC_FC: 8 XPU
 SG_ S4_GlobalTimeMaster_B0 : 7|8@0+ (1,0) [0|255] "" SRR_RL
 SG_ S4_GlobalTimeMaster_B1 : 15|8@0+ (1,0) [0|255] "" SRR_RL
 SG_ S4_GlobalTimeMaster_B2 : 23|8@0+ (1,0) [0|255] "" SRR_RL
 SG_ S4_GlobalTimeMaster_B3 : 31|8@0+ (1,0) [0|255] "" SRR_RL
 SG_ S4_GlobalTimeMaster_B4 : 39|8@0+ (1,0) [0|255] "" SRR_RL
 SG_ S4_GlobalTimeMaster_B5 : 47|8@0+ (1,0) [0|255] "" SRR_RL
 SG_ S4_GlobalTimeMaster_B6 : 55|8@0+ (1,0) [0|255] "" SRR_RL
 SG_ S4_GlobalTimeMaster_B7 : 63|8@0+ (1,0) [0|255] "" SRR_RL

BO_ 1842 S4_TESTER_SRR_RL_DiagReq: 64 Tester
 SG_ S4_TETSER_SRR_RL_DiagReq_Sig : 7|64@0+ (1,0) [0|65535] "" SRR_RL

BO_ 1970 S4_SRR_RL_TESTER_DiagResp: 64 SRR_RL
 SG_ S4_SRR_RL_TETSER_DiagResp_Sig : 7|64@0+ (1,0) [0|65535] "" Vector__XXX

BO_ 2015 S4_TESTER_FunctionDiagReq: 64 Tester
 SG_ S4_TETSER_FunctionDiagReq_Sig : 7|64@0+ (1,0) [0|65535] "" SRR_RL

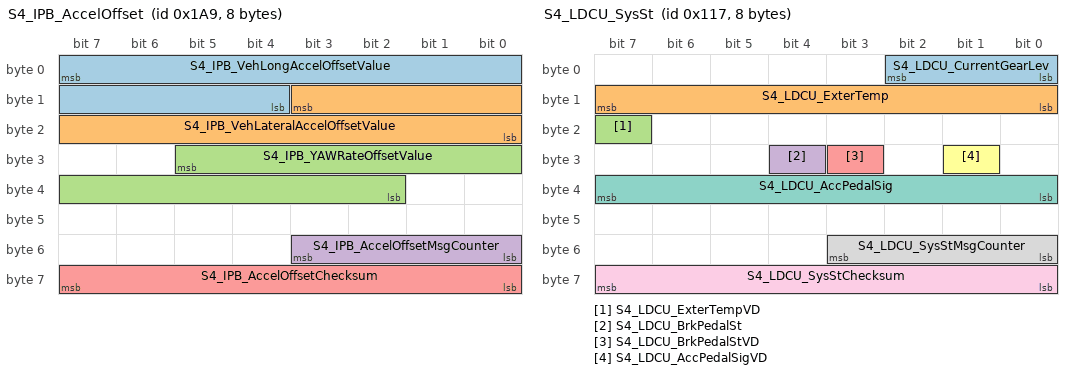
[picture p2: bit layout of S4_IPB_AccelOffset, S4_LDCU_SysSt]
BO_ 425 S4_IPB_AccelOffset: 8 XPU
 SG_ S4_IPB_VehLongAccelOffsetValue : 7|12@0+ (0.002768,-1.73) [-1.73|1.73] "g" SRR_RL
 SG_ S4_IPB_VehLateralAccelOffsetValue : 11|12@0+ (0.002768,-1.73) [-1.73|1.73] "g" SRR_RL
 SG_ S4_IPB_YAWRateOffsetValue : 29|12@0+ (0.0625,-93) [-93|93] "degps" SRR_RL
 SG_ S4_IPB_AccelOffsetMsgCounter : 51|4@0+ (1,0) [0|15] "" SRR_RL
 SG_ S4_IPB_AccelOffsetChecksum : 63|8@0+ (1,0) [0|255] "" SRR_RL

BO_ 279 S4_LDCU_SysSt: 8 XPU
 SG_ S4_LDCU_CurrentGearLev : 2|3@0+ (1,0) [0|7] "" SRR_RL
 SG_ S4_LDCU_ExterTemp : 15|8@0+ (0.5,-40) [-40|87.5] "degC" SRR_RL
 SG_ S4_LDCU_ExterTempVD : 23|1@0+ (1,0) [0|1] "" SRR_RL
 SG_ S4_LDCU_BrkPedalSt : 28|1@0+ (1,0) [0|1] "" SRR_RL
 SG_ S4_LDCU_BrkPedalStVD : 27|1@0+ (1,0) [0|1] "" SRR_RL
 SG_ S4_LDCU_AccPedalSigVD : 25|1@0+ (1,0) [0|1] "" SRR_RL
 SG_ S4_LDCU_AccPedalSig : 39|8@0+ (1,0) [0|100] "" SRR_RL
 SG_ S4_LDCU_SysStMsgCounter : 51|4@0+ (1,0) [0|15] "" SRR_RL
 SG_ S4_LDCU_SysStChecksum : 63|8@0+ (1,0) [0|255] "" SRR_RL

BO_ 870 S4_CDCU_TotalOdoMeter: 8 XPU
 SG_ S4_CDCU_TotalOdometer : 7|20@0+ (1,0) [0|999999] "km" SRR_RL
 SG_ S4_CDCU_TotalOdometerVD : 19|1@0+ (1,0) [0|1] "" SRR_RL

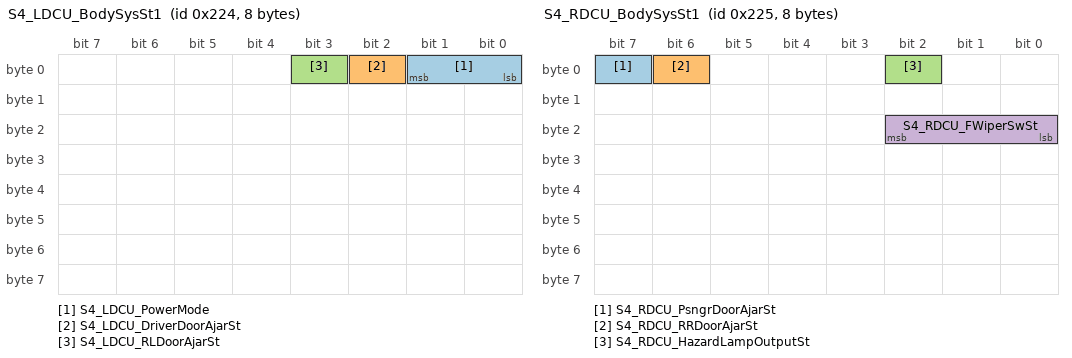
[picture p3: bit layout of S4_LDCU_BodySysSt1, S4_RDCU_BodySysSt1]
BO_ 548 S4_LDCU_BodySysSt1: 8 XPU
 SG_ S4_LDCU_PowerMode : 1|2@0+ (1,0) [0|3] "" SRR_RL
 SG_ S4_LDCU_DriverDoorAjarSt : 2|1@0+ (1,0) [0|1] "" SRR_RL
 SG_ S4_LDCU_RLDoorAjarSt : 3|1@0+ (1,0) [0|1] "" SRR_RL

BO_ 549 S4_RDCU_BodySysSt1: 8 XPU
 SG_ S4_RDCU_PsngrDoorAjarSt : 7|1@0+ (1,0) [0|1] "" SRR_RL
 SG_ S4_RDCU_RRDoorAjarSt : 6|1@0+ (1,0) [0|1] "" SRR_RL
 SG_ S4_RDCU_HazardLampOutputSt : 2|1@0+ (1,0) [0|1] "" SRR_RL
 SG_ S4_RDCU_FWiperSwSt : 18|3@0+ (1,0) [0|7] "" SRR_RL

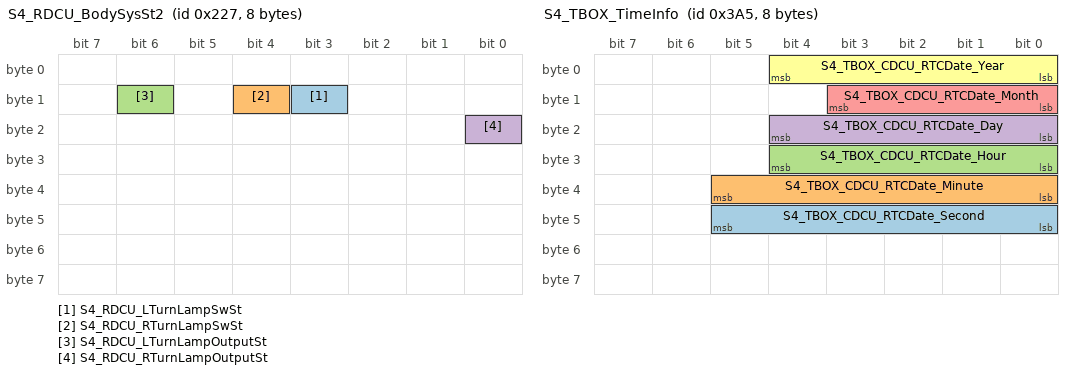
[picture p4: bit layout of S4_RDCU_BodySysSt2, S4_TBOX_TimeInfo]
BO_ 551 S4_RDCU_BodySysSt2: 8 XPU
 SG_ S4_RDCU_LTurnLampSwSt : 11|1@0+ (1,0) [0|1] "" SRR_RL
 SG_ S4_RDCU_RTurnLampSwSt : 12|1@0+ (1,0) [0|1] "" SRR_RL
 SG_ S4_RDCU_LTurnLampOutputSt : 14|1@0+ (1,0) [0|1] "" SRR_RL
 SG_ S4_RDCU_RTurnLampOutputSt : 16|1@0+ (1,0) [0|1] "" SRR_RL

BO_ 933 S4_TBOX_TimeInfo: 8 XPU
 SG_ S4_TBOX_CDCU_RTCDate_Second : 45|6@0+ (1,0) [0|60] "" SRR_RL
 SG_ S4_TBOX_CDCU_RTCDate_Minute : 37|6@0+ (1,0) [0|60] "" SRR_RL
 SG_ S4_TBOX_CDCU_RTCDate_Hour : 28|5@0+ (1,0) [0|24] "" SRR_RL
 SG_ S4_TBOX_CDCU_RTCDate_Day : 20|5@0+ (1,0) [0|31] "" SRR_RL
 SG_ S4_TBOX_CDCU_RTCDate_Month : 11|4@0+ (1,0) [0|12] "" SRR_RL
 SG_ S4_TBOX_CDCU_RTCDate_Year : 4|5@0+ (1,2015) [2015|2046] "" SRR_RL

BO_ 539 S4_CDCU_AssistSysSwSt: 16 XPU
 SG_ S4_CDCU_BSDSwSt : 13|2@0+ (1,0) [0|3] "" SRR_RL
 SG_ S4_CDCU_RCTASwSt : 11|2@0+ (1,0) [0|3] "" SRR_RL
 SG_ S4_CDCU_RCWSwSt : 9|2@0+ (1,0) [0|3] "" SRR_RL
 SG_ S4_CDCU_DOWSwSt : 23|2@0+ (1,0) [0|3] "" SRR_RL
 SG_ S4_CDCU_RadarEmissionSwSt : 31|2@0+ (1,0) [0|3] "" SRR_RL

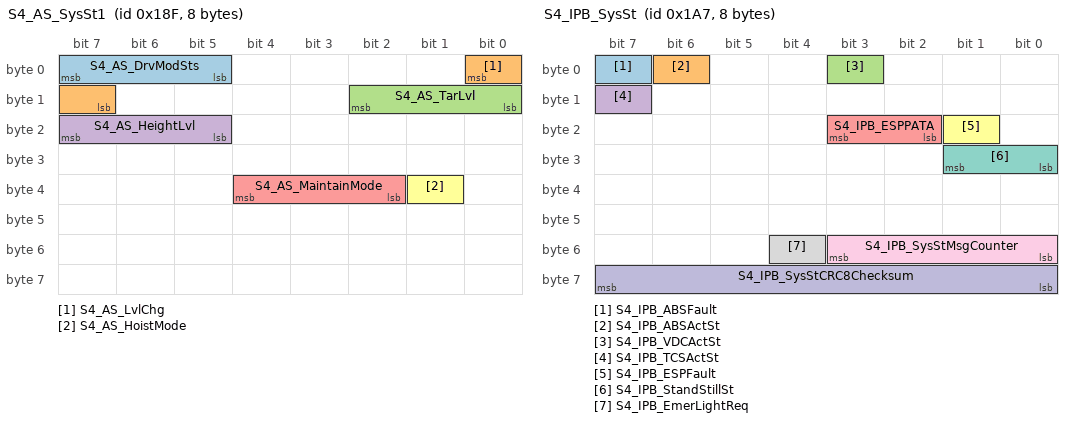
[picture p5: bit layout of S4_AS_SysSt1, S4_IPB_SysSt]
BO_ 399 S4_AS_SysSt1: 8 XPU
 SG_ S4_AS_DrvModSts : 7|3@0+ (1,0) [0|7] "" SRR_RL
 SG_ S4_AS_LvlChg : 0|2@0+ (1,0) [0|3] "" SRR_RL
 SG_ S4_AS_TarLvl : 10|3@0+ (1,0) [0|7] "" SRR_RL
 SG_ S4_AS_HeightLvl : 23|3@0+ (1,0) [0|7] "" SRR_RL
 SG_ S4_AS_MaintainMode : 36|3@0+ (1,0) [0|7] "" SRR_RL
 SG_ S4_AS_HoistMode : 33|1@0+ (1,0) [0|1] "" SRR_RL

BO_ 658 S4_AS_SysSt2: 48 XPU
 SG_ S4_AS_wheelPosFLFilt_mm : 7|11@0+ (1,-1000) [-1000|1000] "mm" SRR_RL
 SG_ S4_AS_wheelPosFRFilt_mm : 12|11@0+ (1,-1000) [-1000|1000] "mm" SRR_RL
 SG_ S4_AS_wheelPosRLFilt_mm : 17|11@0+ (1,-1000) [-1000|1000] "mm" SRR_RL
 SG_ S4_AS_wheelPosRRFilt_mm : 38|11@0+ (1,-1000) [-1000|1000] "mm" SRR_RL
 SG_ S4_AS_PVlvBlk_kPa : 43|12@0+ (1,0) [0|3000] "kPa" SRR_RL
 SG_ S4_AS_LvlFLVD : 56|1@0+ (1,0) [0|1] "" SRR_RL
 SG_ S4_AS_LvlFRVD : 57|1@0+ (1,0) [0|1] "" SRR_RL
 SG_ S4_AS_LvlRLVD : 58|1@0+ (1,0) [0|1] "" SRR_RL
 SG_ S4_AS_LvlRRVD : 59|1@0+ (1,0) [0|1] "" SRR_RL
 SG_ S4_AS_bodyHeaveAccRaw_g : 63|4@0+ (1,-2) [-2|2] "g" SRR_RL

BO_ 281 S4_RWS_Sys: 16 XPU
 SG_ S4_RWS_Wheelangle : 7|16@0+ (0.0005,-16.384) [-16.384|16.3835] "deg" SRR_RL
 SG_ S4_RWS_WheelangleValid : 31|1@0+ (1,0) [0|1] "" SRR_RL
 SG_ S4_RWS_SysWarning : 30|2@0+ (1,0) [0|3] "" SRR_RL
 SG_ S4_RWS_ActualSts : 28|4@0+ (1,0) [0|15] "" SRR_RL
 SG_ S4_RWS_EndVMCCtrlReason : 23|8@0+ (1,0) [0|255] "" SRR_RL
 SG_ S4_RWS_Sys_RollingCounter : 115|4@0+ (1,0) [0|14] "" SRR_RL
 SG_ S4_RWS_Sys_E2EChecksum : 127|8@0+ (1,0) [0|255] "" SRR_RL

BO_ 294 S4_IPB_SpdInfo_E2E: 16 XPU
 SG_ S4_IPB_FLWheelSpd_E2E : 7|15@0+ (0.01,0) [0|239.99] "kmph" SRR_RL
 SG_ S4_IPB_FLWheelSpdVD_E2E : 8|1@0+ (1,0) [0|1] "" SRR_RL
 SG_ S4_IPB_FRWheelSpd_E2E : 23|15@0+ (0.01,0) [0|239.99] "kmph" SRR_RL
 SG_ S4_IPB_FRWheelSpdVD_E2E : 24|1@0+ (1,0) [0|1] "" SRR_RL
 SG_ S4_IPB_VehSpd_E2E : 39|15@0+ (0.01,0) [0|239.99] "kmph" SRR_RL
 SG_ S4_IPB_VehSpdVD_E2E : 53|2@0+ (1,0) [0|3] "" SRR_RL
 SG_ S4_IPB_RLWheelSpd_E2E : 63|15@0+ (0.01,0) [0|239.99] "kmph" SRR_RL
 SG_ S4_IPB_RLWheelSpdVD_E2E : 64|1@0+ (1,0) [0|1] "" SRR_RL
 SG_ S4_IPB_RRWheelSpd_E2E : 79|15@0+ (0.01,0) [0|239.99] "kmph" SRR_RL
 SG_ S4_IPB_RRWheelSpdVD_E2E : 80|1@0+ (1,0) [0|1] "" SRR_RL
 SG_ S4_IPB_SpdInfo1_E2EMsgCounter : 115|4@0+ (1,0) [0|14] "" SRR_RL
 SG_ S4_IPB_SpdInfo1_E2EChecksum : 127|8@0+ (1,0) [0|255] "" SRR_RL

BO_ 422 S4_IPB_SysSt_E2E: 12 XPU
 SG_ S4_IPB_BrkPedalSt_E2E : 7|1@0+ (1,0) [0|1] "" SRR_RL
 SG_ S4_IPB_BrkPedalStVD_E2E : 6|1@0+ (1,0) [0|1] "" SRR_RL
 SG_ S4_IPB_CDPAvl_E2E : 5|1@0+ (1,0) [0|1] "" SRR_RL
 SG_ S4_IPB_HpsAcknowledge_E2E : 4|1@0+ (1,0) [0|1] "" SRR_RL
 SG_ S4_IPB_HpsAvailability_E2E : 3|1@0+ (1,0) [0|1] "" SRR_RL
 SG_ S4_IPB_ABSFault_E2E : 2|1@0+ (1,0) [0|1] "" SRR_RL
 SG_ S4_IPB_ABSActSt_E2E : 1|1@0+ (1,0) [0|1] "" SRR_RL
 SG_ S4_IPB_VDCActSt_E2E : 0|1@0+ (1,0) [0|1] "" SRR_RL
 SG_ S4_IPB_TCSActSt_E2E : 15|1@0+ (1,0) [0|1] "" SRR_RL
 SG_ S4_IPB_BrkLightOnReq_E2E : 14|1@0+ (1,0) [0|1] "" SRR_RL
 SG_ S4_IPB_CDDFaultSt_E2E : 13|1@0+ (1,0) [0|1] "" SRR_RL
 SG_ S4_IPB_CddAvl_E2E : 12|1@0+ (1,0) [0|1] "" SRR_RL
 SG_ S4_IPB_VehLongAccel_E2E : 11|12@0+ (0.002768,-1.73) [-1.73|1.73] "g" SRR_RL
 SG_ S4_IPB_VehLateralAccel_E2E : 31|12@0+ (0.002768,-1.73) [-1.73|1.73] "g" SRR_RL
 SG_ S4_IPB_VehLongAccelVD_E2E : 35|1@0+ (1,0) [0|1] "" SRR_RL
 SG_ S4_IPB_VehLateralAccelVD_E2E : 34|1@0+ (1,0) [0|1] "" SRR_RL
 SG_ S4_IPB_YAWRate_E2E : 33|12@0+ (0.0625,-93) [-93|93] "degps" SRR_RL
 SG_ S4_IPB_YAWRateVD_E2E : 53|1@0+ (1,0) [0|1] "" SRR_RL
 SG_ S4_IPB_FLWheelRotatedDirct_E2E : 52|2@0+ (1,0) [0|3] "" SRR_RL
 SG_ S4_IPB_FLWheelRotatedDirctVD_E2E : 50|1@0+ (1,0) [0|1] "" SRR_RL
 SG_ S4_IPB_FRWheelRotatedDirct_E2E : 49|2@0+ (1,0) [0|3] "" SRR_RL
 SG_ S4_IPB_FRWheelRotatedDirctVD_E2E : 63|1@0+ (1,0) [0|1] "" SRR_RL
 SG_ S4_IPB_RLWheelRotatedDirct_E2E : 62|2@0+ (1,0) [0|3] "" SRR_RL
 SG_ S4_IPB_RLWheelRotatedDirctVD_E2E : 60|1@0+ (1,0) [0|1] "" SRR_RL
 SG_ S4_IPB_RRWheelRotatedDirct_E2E : 59|2@0+ (1,0) [0|3] "" SRR_RL
 SG_ S4_IPB_RRWheelRotatedDirctVD_E2E : 71|1@0+ (1,0) [0|1] "" SRR_RL
 SG_ S4_IPB_EPB_ParkReq_E2E : 57|2@0+ (1,0) [0|3] "" SRR_RL
 SG_ S4_IPB_SysSt_E2EMsgCounter : 83|4@0+ (1,0) [0|14] "" SRR_RL
 SG_ S4_IPB_SysSt_E2EChecksum : 95|8@0+ (1,0) [0|255] "" SRR_RL

BO_ 275 S4_EPS_SASInfo_E2E: 16 XPU
 SG_ S4_EPS_SteeringAngleVD_E2E : 7|1@0+ (1,0) [0|1] "" SRR_RL
 SG_ S4_EPS_SASCalibratedSt_E2E : 6|1@0+ (1,0) [0|1] "" SRR_RL
 SG_ S4_EPS_SASFault_E2E : 5|1@0+ (1,0) [0|1] "" SRR_RL
 SG_ S4_EPS_SASInterStFlags_E2E : 4|5@0+ (1,0) [0|1] "" SRR_RL
 SG_ S4_EPS_SteeringAngle_E2E : 15|16@0+ (0.1,-780) [-780|779.9] "deg" SRR_RL
 SG_ S4_EPS_LDWCtrlSt_E2E : 31|2@0+ (1,0) [0|3] "" SRR_RL
 SG_ S4_EPS_PowerVoltage_E2E : 29|8@0+ (1,0) [0|33] "V" SRR_RL
 SG_ S4_EPS_SteeringAngleSpd_E2E : 37|15@0+ (1,-1016) [-1016|1016] "degps" SRR_RL
 SG_ S4_EPS_TorqCtrlMode : 95|3@0+ (1,0) [0|7] "" SRR_RL
 SG_ S4_EPS_SASInfo_E2EMsgCounter : 115|4@0+ (1,0) [0|14] "" SRR_RL
 SG_ S4_EPS_SASInfo_E2EChecksum : 127|8@0+ (1,0) [0|255] "" SRR_RL

BO_ 423 S4_IPB_SysSt: 8 XPU
 SG_ S4_IPB_ABSFault : 7|1@0+ (1,0) [0|1] "" SRR_RL
 SG_ S4_IPB_ABSActSt : 6|1@0+ (1,0) [0|1] "" SRR_RL
 SG_ S4_IPB_VDCActSt : 3|1@0+ (1,0) [0|1] "" SRR_RL
 SG_ S4_IPB_TCSActSt : 15|1@0+ (1,0) [0|1] "" SRR_RL
 SG_ S4_IPB_ESPPATA : 19|2@0+ (1,0) [0|3] "" SRR_RL
 SG_ S4_IPB_ESPFault : 17|1@0+ (1,0) [0|1] "" SRR_RL
 SG_ S4_IPB_StandStillSt : 25|2@0+ (1,0) [0|3] "" SRR_RL
 SG_ S4_IPB_EmerLightReq : 52|1@0+ (1,0) [0|1] "" SRR_RL
 SG_ S4_IPB_SysStMsgCounter : 51|4@0+ (1,0) [0|15] "" SRR_RL
 SG_ S4_IPB_SysStCRC8Checksum : 63|8@0+ (1,0) [0|255] "" SRR_RL

BO_ 638 S4_TTM_MotorSysSt: 8 XPU
 SG_ S4_TTM_HookStatus : 5|2@0+ (1,0) [0|3] "" SRR_RL
 SG_ S4_TTM_SysErr : 1|1@0+ (1,0) [0|1] "" SRR_RL

CM_ BO_ 618 "The sending period is unstable, ranging from 40 to 80ms
E2E Profile1 Message";
CM_ SG_ 618 S4_SRR_RL_Obj_ID_9 "E2E_Order1";
CM_ SG_ 618 S4_SRR_RL_Obj_DistX_9 "E2E_Order2";
CM_ SG_ 618 S4_SRR_RL_Obj_RelVelX_9 "E2E_Order3";
CM_ SG_ 618 S4_SRR_RL_Obj_AccelX_9 "E2E_Order4";
CM_ SG_ 618 S4_SRR_RL_Obj_DistY_9 "E2E_Order5";
CM_ SG_ 618 S4_SRR_RL_Obj_RelVelY_9 "E2E_Order6";
CM_ SG_ 618 S4_SRR_RL_Obj_AccelY_9 "E2E_Order7";
CM_ SG_ 618 S4_SRR_RL_Obj_DistXStd_9 "E2E_Order8";
CM_ SG_ 618 S4_SRR_RL_Obj_RelVelXStd_9 "E2E_Order9";
CM_ SG_ 618 S4_SRR_RL_Obj_RAccelXStd_9 "E2E_Order10";
CM_ SG_ 618 S4_SRR_RL_Obj_DistYStd_9 "E2E_Order11";
CM_ SG_ 618 S4_SRR_RL_Obj_RelVelYStd_9 "E2E_Order12";
CM_ SG_ 618 S4_SRR_RL_Obj_RAccelYStd_9 "E2E_Order13";
CM_ SG_ 618 S4_SRR_RL_Obj_ValidFlag_9 "E2E_Order14";
CM_ SG_ 618 S4_SRR_RL_Obj_UpdateFlag_9 "E2E_Order15";
CM_ SG_ 618 S4_SRR_RL_Obj_ExistProb_9 "E2E_Order16";
CM_ SG_ 618 S4_SRR_RL_Obj_Type_9 "E2E_Order17";
CM_ SG_ 618 S4_SRR_RL_Obj_EDynProp_9 "E2E_Order18";
CM_ SG_ 618 S4_SRR_RL_Obj_UiLifeCycles_9 "E2E_Order19";
CM_ SG_ 618 S4_SRR_RL_Obj_RCS_9 "E2E_Order20";
CM_ SG_ 618 S4_SRR_RL_Obj_ID_10 "E2E_Order21";
CM_ SG_ 618 S4_SRR_RL_Obj_DistX_10 "E2E_Order22";
CM_ SG_ 618 S4_SRR_RL_Obj_RelVelX_10 "E2E_Order23";
CM_ SG_ 618 S4_SRR_RL_Obj_AccelX_10 "E2E_Order24";
CM_ SG_ 618 S4_SRR_RL_Obj_DistY_10 "E2E_Order25";
CM_ SG_ 618 S4_SRR_RL_Obj_RelVelY_10 "E2E_Order26";
CM_ SG_ 618 S4_SRR_RL_Obj_AccelY_10 "E2E_Order27";
CM_ SG_ 618 S4_SRR_RL_Obj_DistXStd_10 "E2E_Order28";
CM_ SG_ 618 S4_SRR_RL_Obj_RelVelXStd_10 "E2E_Order29";
CM_ SG_ 618 S4_SRR_RL_Obj_RAccelXStd_10 "E2E_Order30";
CM_ SG_ 618 S4_SRR_RL_Obj_DistYStd_10 "E2E_Order31";
CM_ SG_ 618 S4_SRR_RL_Obj_RelVelYStd_10 "E2E_Order32";
CM_ SG_ 618 S4_SRR_RL_Obj_RAccelYStd_10 "E2E_Order33";
CM_ SG_ 618 S4_SRR_RL_Obj_ValidFlag_10 "E2E_Order34";
CM_ SG_ 618 S4_SRR_RL_Obj_UpdateFlag_10 "E2E_Order35";
CM_ SG_ 618 S4_SRR_RL_Obj_ExistProb_10 "E2E_Order36";
CM_ SG_ 618 S4_SRR_RL_Obj_Type_10 "E2E_Order37";
CM_ SG_ 618 S4_SRR_RL_Obj_EDynProp_10 "E2E_Order38";
CM_ SG_ 618 S4_SRR_RL_Obj_UiLifeCycles_10 "E2E_Order39";
CM_ SG_ 618 S4_SRR_RL_Obj_RCS_10 "E2E_Order40";
CM_ SG_ 618 S4_SRR_RL_Obj_ID_11 "E2E_Order41";
CM_ SG_ 618 S4_SRR_RL_Obj_DistX_11 "E2E_Order42";
CM_ SG_ 618 S4_SRR_RL_Obj_RelVelX_11 "E2E_Order43";
CM_ SG_ 618 S4_SRR_RL_Obj_AccelX_11 "E2E_Order44";
CM_ SG_ 618 S4_SRR_RL_Obj_DistY_11 "E2E_Order45";
CM_ SG_ 618 S4_SRR_RL_Obj_RelVelY_11 "E2E_Order46";
CM_ SG_ 618 S4_SRR_RL_Obj_AccelY_11 "E2E_Order47";
CM_ SG_ 618 S4_SRR_RL_Obj_DistXStd_11 "E2E_Order48";
CM_ SG_ 618 S4_SRR_RL_Obj_RelVelXStd_11 "E2E_Order49";
CM_ SG_ 618 S4_SRR_RL_Obj_RAccelXStd_11 "E2E_Order50";
CM_ SG_ 618 S4_SRR_RL_Obj_DistYStd_11 "E2E_Order51";
CM_ SG_ 618 S4_SRR_RL_Obj_RelVelYStd_11 "E2E_Order52";
CM_ SG_ 618 S4_SRR_RL_Obj_RAccelYStd_11 "E2E_Order53";
CM_ SG_ 618 S4_SRR_RL_Obj_ValidFlag_11 "E2E_Order54";
CM_ SG_ 618 S4_SRR_RL_Obj_UpdateFlag_11 "E2E_Order55";
CM_ SG_ 618 S4_SRR_RL_Obj_ExistProb_11 "E2E_Order56";
CM_ SG_ 618 S4_SRR_RL_Obj_Type_11 "E2E_Order57";
CM_ SG_ 618 S4_SRR_RL_Obj_EDynProp_11 "E2E_Order58";
CM_ SG_ 618 S4_SRR_RL_Obj_UiLifeCycles_11 "E2E_Order59";
CM_ SG_ 618 S4_SRR_RL_Obj_RCS_11 "E2E_Order60";
CM_ SG_ 618 S4_SRR_RL_Obj_3_E2EChecksum "DataID = 0xA62";
CM_ BO_ 619 "The sending period is unstable, ranging from 40 to 80ms
E2E Profile1 Message";
CM_ SG_ 619 S4_SRR_RL_Obj_ID_12 "E2E_Order1";
CM_ SG_ 619 S4_SRR_RL_Obj_DistX_12 "E2E_Order2";
CM_ SG_ 619 S4_SRR_RL_Obj_RelVelX_12 "E2E_Order3";
CM_ SG_ 619 S4_SRR_RL_Obj_AccelX_12 "E2E_Order4";
CM_ SG_ 619 S4_SRR_RL_Obj_DistY_12 "E2E_Order5";
CM_ SG_ 619 S4_SRR_RL_Obj_RelVelY_12 "E2E_Order6";
CM_ SG_ 619 S4_SRR_RL_Obj_AccelY_12 "E2E_Order7";
CM_ SG_ 619 S4_SRR_RL_Obj_DistXStd_12 "E2E_Order8";
CM_ SG_ 619 S4_SRR_RL_Obj_RelVelXStd_12 "E2E_Order9";
CM_ SG_ 619 S4_SRR_RL_Obj_RAccelXStd_12 "E2E_Order10";
CM_ SG_ 619 S4_SRR_RL_Obj_DistYStd_12 "E2E_Order11";
CM_ SG_ 619 S4_SRR_RL_Obj_RelVelYStd_12 "E2E_Order12";
CM_ SG_ 619 S4_SRR_RL_Obj_RAccelYStd_12 "E2E_Order13";
CM_ SG_ 619 S4_SRR_RL_Obj_ValidFlag_12 "E2E_Order14";
CM_ SG_ 619 S4_SRR_RL_Obj_UpdateFlag_12 "E2E_Order15";
CM_ SG_ 619 S4_SRR_RL_Obj_ExistProb_12 "E2E_Order16";
CM_ SG_ 619 S4_SRR_RL_Obj_Type_12 "E2E_Order17";
CM_ SG_ 619 S4_SRR_RL_Obj_EDynProp_12 "E2E_Order18";
CM_ SG_ 619 S4_SRR_RL_Obj_UiLifeCycles_12 "E2E_Order19";
CM_ SG_ 619 S4_SRR_RL_Obj_RCS_12 "E2E_Order20";
CM_ SG_ 619 S4_SRR_RL_Obj_ID_13 "E2E_Order21";
CM_ SG_ 619 S4_SRR_RL_Obj_DistX_13 "E2E_Order22";
CM_ SG_ 619 S4_SRR_RL_Obj_RelVelX_13 "E2E_Order23";
CM_ SG_ 619 S4_SRR_RL_Obj_AccelX_13 "E2E_Order24";
CM_ SG_ 619 S4_SRR_RL_Obj_DistY_13 "E2E_Order25";
CM_ SG_ 619 S4_SRR_RL_Obj_RelVelY_13 "E2E_Order26";
CM_ SG_ 619 S4_SRR_RL_Obj_AccelY_13 "E2E_Order27";
CM_ SG_ 619 S4_SRR_RL_Obj_DistXStd_13 "E2E_Order28";
CM_ SG_ 619 S4_SRR_RL_Obj_RelVelXStd_13 "E2E_Order29";
CM_ SG_ 619 S4_SRR_RL_Obj_RAccelXStd_13 "E2E_Order30";
CM_ SG_ 619 S4_SRR_RL_Obj_DistYStd_13 "E2E_Order31";
CM_ SG_ 619 S4_SRR_RL_Obj_RelVelYStd_13 "E2E_Order32";
CM_ SG_ 619 S4_SRR_RL_Obj_RAccelYStd_13 "E2E_Order33";
CM_ SG_ 619 S4_SRR_RL_Obj_ValidFlag_13 "E2E_Order34";
CM_ SG_ 619 S4_SRR_RL_Obj_UpdateFlag_13 "E2E_Order35";
CM_ SG_ 619 S4_SRR_RL_Obj_ExistProb_13 "E2E_Order36";
CM_ SG_ 619 S4_SRR_RL_Obj_Type_13 "E2E_Order37";
CM_ SG_ 619 S4_SRR_RL_Obj_EDynProp_13 "E2E_Order38";
CM_ SG_ 619 S4_SRR_RL_Obj_UiLifeCycles_13 "E2E_Order39";
CM_ SG_ 619 S4_SRR_RL_Obj_RCS_13 "E2E_Order40";
CM_ SG_ 619 S4_SRR_RL_Obj_ID_14 "E2E_Order41";
CM_ SG_ 619 S4_SRR_RL_Obj_DistX_14 "E2E_Order42";
CM_ SG_ 619 S4_SRR_RL_Obj_RelVelX_14 "E2E_Order43";
CM_ SG_ 619 S4_SRR_RL_Obj_AccelX_14 "E2E_Order44";
CM_ SG_ 619 S4_SRR_RL_Obj_DistY_14 "E2E_Order45";
CM_ SG_ 619 S4_SRR_RL_Obj_RelVelY_14 "E2E_Order46";
CM_ SG_ 619 S4_SRR_RL_Obj_AccelY_14 "E2E_Order47";
CM_ SG_ 619 S4_SRR_RL_Obj_DistXStd_14 "E2E_Order48";
CM_ SG_ 619 S4_SRR_RL_Obj_RelVelXStd_14 "E2E_Order49";
CM_ SG_ 619 S4_SRR_RL_Obj_RAccelXStd_14 "E2E_Order50";
CM_ SG_ 619 S4_SRR_RL_Obj_DistYStd_14 "E2E_Order51";
CM_ SG_ 619 S4_SRR_RL_Obj_RelVelYStd_14 "E2E_Order52";
CM_ SG_ 619 S4_SRR_RL_Obj_RAccelYStd_14 "E2E_Order53";
CM_ SG_ 619 S4_SRR_RL_Obj_ValidFlag_14 "E2E_Order54";
CM_ SG_ 619 S4_SRR_RL_Obj_UpdateFlag_14 "E2E_Order55";
CM_ SG_ 619 S4_SRR_RL_Obj_ExistProb_14 "E2E_Order56";
CM_ SG_ 619 S4_SRR_RL_Obj_Type_14 "E2E_Order57";
CM_ SG_ 619 S4_SRR_RL_Obj_EDynProp_14 "E2E_Order58";
CM_ SG_ 619 S4_SRR_RL_Obj_UiLifeCycles_14 "E2E_Order59";
CM_ SG_ 619 S4_SRR_RL_Obj_RCS_14 "E2E_Order60";
CM_ SG_ 619 S4_SRR_RL_Obj_4_E2EChecksum "DataID = 0x0B62";
CM_ BO_ 620 "The sending period is unstable, ranging from 40 to 80ms
E2E Profile1 Message";
CM_ SG_ 620 S4_SRR_RL_Obj_ID_15 "E2E_Order1";
CM_ SG_ 620 S4_SRR_RL_Obj_DistX_15 "E2E_Order2";
CM_ SG_ 620 S4_SRR_RL_Obj_RelVelX_15 "E2E_Order3";
CM_ SG_ 620 S4_SRR_RL_Obj_AccelX_15 "E2E_Order4";
CM_ SG_ 620 S4_SRR_RL_Obj_DistY_15 "E2E_Order5";
CM_ SG_ 620 S4_SRR_RL_Obj_RelVelY_15 "E2E_Order6";
CM_ SG_ 620 S4_SRR_RL_Obj_AccelY_15 "E2E_Order7";
CM_ SG_ 620 S4_SRR_RL_Obj_DistXStd_15 "E2E_Order8";
CM_ SG_ 620 S4_SRR_RL_Obj_RelVelXStd_15 "E2E_Order9";
CM_ SG_ 620 S4_SRR_RL_Obj_RAccelXStd_15 "E2E_Order10";
CM_ SG_ 620 S4_SRR_RL_Obj_DistYStd_15 "E2E_Order11";
CM_ SG_ 620 S4_SRR_RL_Obj_RelVelYStd_15 "E2E_Order12";
CM_ SG_ 620 S4_SRR_RL_Obj_RAccelYStd_15 "E2E_Order13";
CM_ SG_ 620 S4_SRR_RL_Obj_ValidFlag_15 "E2E_Order14";
CM_ SG_ 620 S4_SRR_RL_Obj_UpdateFlag_15 "E2E_Order15";
CM_ SG_ 620 S4_SRR_RL_Obj_ExistProb_15 "E2E_Order16";
CM_ SG_ 620 S4_SRR_RL_Obj_Type_15 "E2E_Order17";
CM_ SG_ 620 S4_SRR_RL_Obj_EDynProp_15 "E2E_Order18";
CM_ SG_ 620 S4_SRR_RL_Obj_UiLifeCycles_15 "E2E_Order19";
CM_ SG_ 620 S4_SRR_RL_Obj_RCS_15 "E2E_Order20";
CM_ SG_ 620 S4_SRR_RL_Obj_ID_16 "E2E_Order21";
CM_ SG_ 620 S4_SRR_RL_Obj_DistX_16 "E2E_Order22";
CM_ SG_ 620 S4_SRR_RL_Obj_RelVelX_16 "E2E_Order23";
CM_ SG_ 620 S4_SRR_RL_Obj_AccelX_16 "E2E_Order24";
CM_ SG_ 620 S4_SRR_RL_Obj_DistY_16 "E2E_Order25";
CM_ SG_ 620 S4_SRR_RL_Obj_RelVelY_16 "E2E_Order26";
CM_ SG_ 620 S4_SRR_RL_Obj_AccelY_16 "E2E_Order27";
CM_ SG_ 620 S4_SRR_RL_Obj_DistXStd_16 "E2E_Order28";
CM_ SG_ 620 S4_SRR_RL_Obj_RelVelXStd_16 "E2E_Order29";
CM_ SG_ 620 S4_SRR_RL_Obj_RAccelXStd_16 "E2E_Order30";
CM_ SG_ 620 S4_SRR_RL_Obj_DistYStd_16 "E2E_Order31";
CM_ SG_ 620 S4_SRR_RL_Obj_RelVelYStd_16 "E2E_Order32";
CM_ SG_ 620 S4_SRR_RL_Obj_RAccelYStd_16 "E2E_Order33";
CM_ SG_ 620 S4_SRR_RL_Obj_ValidFlag_16 "E2E_Order34";
CM_ SG_ 620 S4_SRR_RL_Obj_UpdateFlag_16 "E2E_Order35";
CM_ SG_ 620 S4_SRR_RL_Obj_ExistProb_16 "E2E_Order36";
CM_ SG_ 620 S4_SRR_RL_Obj_Type_16 "E2E_Order37";
CM_ SG_ 620 S4_SRR_RL_Obj_EDynProp_16 "E2E_Order38";
CM_ SG_ 620 S4_SRR_RL_Obj_UiLifeCycles_16 "E2E_Order39";
CM_ SG_ 620 S4_SRR_RL_Obj_RCS_16 "E2E_Order40";
CM_ SG_ 620 S4_SRR_RL_Obj_ID_17 "E2E_Order41";
CM_ SG_ 620 S4_SRR_RL_Obj_DistX_17 "E2E_Order42";
CM_ SG_ 620 S4_SRR_RL_Obj_RelVelX_17 "E2E_Order43";
CM_ SG_ 620 S4_SRR_RL_Obj_AccelX_17 "E2E_Order44";
CM_ SG_ 620 S4_SRR_RL_Obj_DistY_17 "E2E_Order45";
CM_ SG_ 620 S4_SRR_RL_Obj_RelVelY_17 "E2E_Order46";
CM_ SG_ 620 S4_SRR_RL_Obj_AccelY_17 "E2E_Order47";
CM_ SG_ 620 S4_SRR_RL_Obj_DistXStd_17 "E2E_Order48";
CM_ SG_ 620 S4_SRR_RL_Obj_RelVelXStd_17 "E2E_Order49";
CM_ SG_ 620 S4_SRR_RL_Obj_RAccelXStd_17 "E2E_Order50";
CM_ SG_ 620 S4_SRR_RL_Obj_DistYStd_17 "E2E_Order51";
CM_ SG_ 620 S4_SRR_RL_Obj_RelVelYStd_17 "E2E_Order52";
CM_ SG_ 620 S4_SRR_RL_Obj_RAccelYStd_17 "E2E_Order53";
CM_ SG_ 620 S4_SRR_RL_Obj_ValidFlag_17 "E2E_Order54";
CM_ SG_ 620 S4_SRR_RL_Obj_UpdateFlag_17 "E2E_Order55";
CM_ SG_ 620 S4_SRR_RL_Obj_ExistProb_17 "E2E_Order56";
CM_ SG_ 620 S4_SRR_RL_Obj_Type_17 "E2E_Order57";
CM_ SG_ 620 S4_SRR_RL_Obj_EDynProp_17 "E2E_Order58";
CM_ SG_ 620 S4_SRR_RL_Obj_UiLifeCycles_17 "E2E_Order59";
CM_ SG_ 620 S4_SRR_RL_Obj_RCS_17 "E2E_Order60";
CM_ SG_ 620 S4_SRR_RL_Obj_5_E2EChecksum "DataID = 0x0C62";
CM_ BO_ 621 "The sending period is unstable, ranging from 40 to 80ms
E2E Profile1 Message";
CM_ SG_ 621 S4_SRR_RL_Obj_ID_18 "E2E_Order1";
CM_ SG_ 621 S4_SRR_RL_Obj_DistX_18 "E2E_Order2";
CM_ SG_ 621 S4_SRR_RL_Obj_RelVelX_18 "E2E_Order3";
CM_ SG_ 621 S4_SRR_RL_Obj_AccelX_18 "E2E_Order4";
CM_ SG_ 621 S4_SRR_RL_Obj_DistY_18 "E2E_Order5";
CM_ SG_ 621 S4_SRR_RL_Obj_RelVelY_18 "E2E_Order6";
CM_ SG_ 621 S4_SRR_RL_Obj_AccelY_18 "E2E_Order7";
CM_ SG_ 621 S4_SRR_RL_Obj_DistXStd_18 "E2E_Order8";
CM_ SG_ 621 S4_SRR_RL_Obj_RelVelXStd_18 "E2E_Order9";
CM_ SG_ 621 S4_SRR_RL_Obj_RAccelXStd_18 "E2E_Order10";
CM_ SG_ 621 S4_SRR_RL_Obj_DistYStd_18 "E2E_Order11";
CM_ SG_ 621 S4_SRR_RL_Obj_RelVelYStd_18 "E2E_Order12";
CM_ SG_ 621 S4_SRR_RL_Obj_RAccelYStd_18 "E2E_Order13";
CM_ SG_ 621 S4_SRR_RL_Obj_ValidFlag_18 "E2E_Order14";
CM_ SG_ 621 S4_SRR_RL_Obj_UpdateFlag_18 "E2E_Order15";
CM_ SG_ 621 S4_SRR_RL_Obj_ExistProb_18 "E2E_Order16";
CM_ SG_ 621 S4_SRR_RL_Obj_Type_18 "E2E_Order17";
CM_ SG_ 621 S4_SRR_RL_Obj_EDynProp_18 "E2E_Order18";
CM_ SG_ 621 S4_SRR_RL_Obj_UiLifeCycles_18 "E2E_Order19";
CM_ SG_ 621 S4_SRR_RL_Obj_RCS_18 "E2E_Order20";
CM_ SG_ 621 S4_SRR_RL_Obj_ID_19 "E2E_Order21";
CM_ SG_ 621 S4_SRR_RL_Obj_DistX_19 "E2E_Order22";
CM_ SG_ 621 S4_SRR_RL_Obj_RelVelX_19 "E2E_Order23";
CM_ SG_ 621 S4_SRR_RL_Obj_AccelX_19 "E2E_Order24";
CM_ SG_ 621 S4_SRR_RL_Obj_DistY_19 "E2E_Order25";
CM_ SG_ 621 S4_SRR_RL_Obj_RelVelY_19 "E2E_Order26";
CM_ SG_ 621 S4_SRR_RL_Obj_AccelY_19 "E2E_Order27";
CM_ SG_ 621 S4_SRR_RL_Obj_DistXStd_19 "E2E_Order28";
CM_ SG_ 621 S4_SRR_RL_Obj_RelVelXStd_19 "E2E_Order29";
CM_ SG_ 621 S4_SRR_RL_Obj_RAccelXStd_19 "E2E_Order30";
CM_ SG_ 621 S4_SRR_RL_Obj_DistYStd_19 "E2E_Order31";
CM_ SG_ 621 S4_SRR_RL_Obj_RelVelYStd_19 "E2E_Order32";
CM_ SG_ 621 S4_SRR_RL_Obj_RAccelYStd_19 "E2E_Order33";
CM_ SG_ 621 S4_SRR_RL_Obj_ValidFlag_19 "E2E_Order34";
CM_ SG_ 621 S4_SRR_RL_Obj_UpdateFlag_19 "E2E_Order35";
CM_ SG_ 621 S4_SRR_RL_Obj_ExistProb_19 "E2E_Order36";
CM_ SG_ 621 S4_SRR_RL_Obj_Type_19 "E2E_Order37";
CM_ SG_ 621 S4_SRR_RL_Obj_EDynProp_19 "E2E_Order38";
CM_ SG_ 621 S4_SRR_RL_Obj_UiLifeCycles_19 "E2E_Order39";
CM_ SG_ 621 S4_SRR_RL_Obj_RCS_19 "E2E_Order40";
CM_ SG_ 621 S4_SRR_RL_Obj_ID_20 "E2E_Order41";
CM_ SG_ 621 S4_SRR_RL_Obj_DistX_20 "E2E_Order42";
CM_ SG_ 621 S4_SRR_RL_Obj_RelVelX_20 "E2E_Order43";
CM_ SG_ 621 S4_SRR_RL_Obj_AccelX_20 "E2E_Order44";
CM_ SG_ 621 S4_SRR_RL_Obj_DistY_20 "E2E_Order45";
CM_ SG_ 621 S4_SRR_RL_Obj_RelVelY_20 "E2E_Order46";
CM_ SG_ 621 S4_SRR_RL_Obj_AccelY_20 "E2E_Order47";
CM_ SG_ 621 S4_SRR_RL_Obj_DistXStd_20 "E2E_Order48";
CM_ SG_ 621 S4_SRR_RL_Obj_RelVelXStd_20 "E2E_Order49";
CM_ SG_ 621 S4_SRR_RL_Obj_RAccelXStd_20 "E2E_Order50";
CM_ SG_ 621 S4_SRR_RL_Obj_DistYStd_20 "E2E_Order51";
CM_ SG_ 621 S4_SRR_RL_Obj_RelVelYStd_20 "E2E_Order52";
CM_ SG_ 621 S4_SRR_RL_Obj_RAccelYStd_20 "E2E_Order53";
CM_ SG_ 621 S4_SRR_RL_Obj_ValidFlag_20 "E2E_Order54";
CM_ SG_ 621 S4_SRR_RL_Obj_UpdateFlag_20 "E2E_Order55";
CM_ SG_ 621 S4_SRR_RL_Obj_ExistProb_20 "E2E_Order56";
CM_ SG_ 621 S4_SRR_RL_Obj_Type_20 "E2E_Order57";
CM_ SG_ 621 S4_SRR_RL_Obj_EDynProp_20 "E2E_Order58";
CM_ SG_ 621 S4_SRR_RL_Obj_UiLifeCycles_20 "E2E_Order59";
CM_ SG_ 621 S4_SRR_RL_Obj_RCS_20 "E2E_Order60";
CM_ SG_ 621 S4_SRR_RL_Obj_6_E2EChecksum "DataID = 0x0D62";
CM_ BO_ 622 "The sending period is unstable, ranging from 40 to 80ms
E2E Profile1 Message";
CM_ SG_ 622 S4_SRR_RL_Obj_ID_21 "E2E_Order1";
CM_ SG_ 622 S4_SRR_RL_Obj_DistX_21 "E2E_Order2";
CM_ SG_ 622 S4_SRR_RL_Obj_RelVelX_21 "E2E_Order3";
CM_ SG_ 622 S4_SRR_RL_Obj_AccelX_21 "E2E_Order4";
CM_ SG_ 622 S4_SRR_RL_Obj_DistY_21 "E2E_Order5";
CM_ SG_ 622 S4_SRR_RL_Obj_RelVelY_21 "E2E_Order6";
CM_ SG_ 622 S4_SRR_RL_Obj_AccelY_21 "E2E_Order7";
CM_ SG_ 622 S4_SRR_RL_Obj_DistXStd_21 "E2E_Order8";
CM_ SG_ 622 S4_SRR_RL_Obj_RelVelXStd_21 "E2E_Order9";
CM_ SG_ 622 S4_SRR_RL_Obj_RAccelXStd_21 "E2E_Order10";
CM_ SG_ 622 S4_SRR_RL_Obj_DistYStd_21 "E2E_Order11";
CM_ SG_ 622 S4_SRR_RL_Obj_RelVelYStd_21 "E2E_Order12";
CM_ SG_ 622 S4_SRR_RL_Obj_RAccelYStd_21 "E2E_Order13";
CM_ SG_ 622 S4_SRR_RL_Obj_ValidFlag_21 "E2E_Order14";
CM_ SG_ 622 S4_SRR_RL_Obj_UpdateFlag_21 "E2E_Order15";
CM_ SG_ 622 S4_SRR_RL_Obj_ExistProb_21 "E2E_Order16";
CM_ SG_ 622 S4_SRR_RL_Obj_Type_21 "E2E_Order17";
CM_ SG_ 622 S4_SRR_RL_Obj_EDynProp_21 "E2E_Order18";
CM_ SG_ 622 S4_SRR_RL_Obj_UiLifeCycles_21 "E2E_Order19";
CM_ SG_ 622 S4_SRR_RL_Obj_RCS_21 "E2E_Order20";
CM_ SG_ 622 S4_SRR_RL_Obj_ID_22 "E2E_Order21";
CM_ SG_ 622 S4_SRR_RL_Obj_DistX_22 "E2E_Order22";
CM_ SG_ 622 S4_SRR_RL_Obj_RelVelX_22 "E2E_Order23";
CM_ SG_ 622 S4_SRR_RL_Obj_AccelX_22 "E2E_Order24";
CM_ SG_ 622 S4_SRR_RL_Obj_DistY_22 "E2E_Order25";
CM_ SG_ 622 S4_SRR_RL_Obj_RelVelY_22 "E2E_Order26";
CM_ SG_ 622 S4_SRR_RL_Obj_AccelY_22 "E2E_Order27";
CM_ SG_ 622 S4_SRR_RL_Obj_DistXStd_22 "E2E_Order28";
CM_ SG_ 622 S4_SRR_RL_Obj_RelVelXStd_22 "E2E_Order29";
CM_ SG_ 622 S4_SRR_RL_Obj_RAccelXStd_22 "E2E_Order30";
CM_ SG_ 622 S4_SRR_RL_Obj_DistYStd_22 "E2E_Order31";
CM_ SG_ 622 S4_SRR_RL_Obj_RelVelYStd_22 "E2E_Order32";
CM_ SG_ 622 S4_SRR_RL_Obj_RAccelYStd_22 "E2E_Order33";
CM_ SG_ 622 S4_SRR_RL_Obj_ValidFlag_22 "E2E_Order34";
CM_ SG_ 622 S4_SRR_RL_Obj_UpdateFlag_22 "E2E_Order35";
CM_ SG_ 622 S4_SRR_RL_Obj_ExistProb_22 "E2E_Order36";
CM_ SG_ 622 S4_SRR_RL_Obj_Type_22 "E2E_Order37";
CM_ SG_ 622 S4_SRR_RL_Obj_EDynProp_22 "E2E_Order38";
CM_ SG_ 622 S4_SRR_RL_Obj_UiLifeCycles_22 "E2E_Order39";
CM_ SG_ 622 S4_SRR_RL_Obj_RCS_22 "E2E_Order40";
CM_ SG_ 622 S4_SRR_RL_Obj_ID_23 "E2E_Order41";
CM_ SG_ 622 S4_SRR_RL_Obj_DistX_23 "E2E_Order42";
CM_ SG_ 622 S4_SRR_RL_Obj_RelVelX_23 "E2E_Order43";
CM_ SG_ 622 S4_SRR_RL_Obj_AccelX_23 "E2E_Order44";
CM_ SG_ 622 S4_SRR_RL_Obj_DistY_23 "E2E_Order45";
CM_ SG_ 622 S4_SRR_RL_Obj_RelVelY_23 "E2E_Order46";
CM_ SG_ 622 S4_SRR_RL_Obj_AccelY_23 "E2E_Order47";
CM_ SG_ 622 S4_SRR_RL_Obj_DistXStd_23 "E2E_Order48";
CM_ SG_ 622 S4_SRR_RL_Obj_RelVelXStd_23 "E2E_Order49";
CM_ SG_ 622 S4_SRR_RL_Obj_RAccelXStd_23 "E2E_Order50";
CM_ SG_ 622 S4_SRR_RL_Obj_DistYStd_23 "E2E_Order51";
CM_ SG_ 622 S4_SRR_RL_Obj_RelVelYStd_23 "E2E_Order52";
CM_ SG_ 622 S4_SRR_RL_Obj_RAccelYStd_23 "E2E_Order53";
CM_ SG_ 622 S4_SRR_RL_Obj_ValidFlag_23 "E2E_Order54";
CM_ SG_ 622 S4_SRR_RL_Obj_UpdateFlag_23 "E2E_Order55";
CM_ SG_ 622 S4_SRR_RL_Obj_ExistProb_23 "E2E_Order56";
CM_ SG_ 622 S4_SRR_RL_Obj_Type_23 "E2E_Order57";
CM_ SG_ 622 S4_SRR_RL_Obj_EDynProp_23 "E2E_Order58";
CM_ SG_ 622 S4_SRR_RL_Obj_UiLifeCycles_23 "E2E_Order59";
CM_ SG_ 622 S4_SRR_RL_Obj_RCS_23 "E2E_Order60";
CM_ SG_ 622 S4_SRR_RL_Obj_7_E2EChecksum "DataID = 0x0E62";
CM_ BO_ 623 "The sending period is unstable, ranging from 40 to 80ms
E2E Profile1 Message";
CM_ SG_ 623 S4_SRR_RL_Obj_ID_24 "E2E_Order1";
CM_ SG_ 623 S4_SRR_RL_Obj_DistX_24 "E2E_Order2";
CM_ SG_ 623 S4_SRR_RL_Obj_RelVelX_24 "E2E_Order3";
CM_ SG_ 623 S4_SRR_RL_Obj_AccelX_24 "E2E_Order4";
CM_ SG_ 623 S4_SRR_RL_Obj_DistY_24 "E2E_Order5";
CM_ SG_ 623 S4_SRR_RL_Obj_RelVelY_24 "E2E_Order6";
CM_ SG_ 623 S4_SRR_RL_Obj_AccelY_24 "E2E_Order7";
CM_ SG_ 623 S4_SRR_RL_Obj_DistXStd_24 "E2E_Order8";
CM_ SG_ 623 S4_SRR_RL_Obj_RelVelXStd_24 "E2E_Order9";
CM_ SG_ 623 S4_SRR_RL_Obj_RAccelXStd_24 "E2E_Order10";
CM_ SG_ 623 S4_SRR_RL_Obj_DistYStd_24 "E2E_Order11";
CM_ SG_ 623 S4_SRR_RL_Obj_RelVelYStd_24 "E2E_Order12";
CM_ SG_ 623 S4_SRR_RL_Obj_RAccelYStd_24 "E2E_Order13";
CM_ SG_ 623 S4_SRR_RL_Obj_ValidFlag_24 "E2E_Order14";
CM_ SG_ 623 S4_SRR_RL_Obj_UpdateFlag_24 "E2E_Order15";
CM_ SG_ 623 S4_SRR_RL_Obj_ExistProb_24 "E2E_Order16";
CM_ SG_ 623 S4_SRR_RL_Obj_Type_24 "E2E_Order17";
CM_ SG_ 623 S4_SRR_RL_Obj_EDynProp_24 "E2E_Order18";
CM_ SG_ 623 S4_SRR_RL_Obj_UiLifeCycles_24 "E2E_Order19";
CM_ SG_ 623 S4_SRR_RL_Obj_RCS_24 "E2E_Order20";
CM_ SG_ 623 S4_SRR_RL_Obj_ID_25 "E2E_Order21";
CM_ SG_ 623 S4_SRR_RL_Obj_DistX_25 "E2E_Order22";
CM_ SG_ 623 S4_SRR_RL_Obj_RelVelX_25 "E2E_Order23";
CM_ SG_ 623 S4_SRR_RL_Obj_AccelX_25 "E2E_Order24";
CM_ SG_ 623 S4_SRR_RL_Obj_DistY_25 "E2E_Order25";
CM_ SG_ 623 S4_SRR_RL_Obj_RelVelY_25 "E2E_Order26";
CM_ SG_ 623 S4_SRR_RL_Obj_AccelY_25 "E2E_Order27";
CM_ SG_ 623 S4_SRR_RL_Obj_DistXStd_25 "E2E_Order28";
CM_ SG_ 623 S4_SRR_RL_Obj_RelVelXStd_25 "E2E_Order29";
CM_ SG_ 623 S4_SRR_RL_Obj_RAccelXStd_25 "E2E_Order30";
CM_ SG_ 623 S4_SRR_RL_Obj_DistYStd_25 "E2E_Order31";
CM_ SG_ 623 S4_SRR_RL_Obj_RelVelYStd_25 "E2E_Order32";
CM_ SG_ 623 S4_SRR_RL_Obj_RAccelYStd_25 "E2E_Order33";
CM_ SG_ 623 S4_SRR_RL_Obj_ValidFlag_25 "E2E_Order34";
CM_ SG_ 623 S4_SRR_RL_Obj_UpdateFlag_25 "E2E_Order35";
CM_ SG_ 623 S4_SRR_RL_Obj_ExistProb_25 "E2E_Order36";
CM_ SG_ 623 S4_SRR_RL_Obj_Type_25 "E2E_Order37";
CM_ SG_ 623 S4_SRR_RL_Obj_EDynProp_25 "E2E_Order38";
CM_ SG_ 623 S4_SRR_RL_Obj_UiLifeCycles_25 "E2E_Order39";
CM_ SG_ 623 S4_SRR_RL_Obj_RCS_25 "E2E_Order40";
CM_ SG_ 623 S4_SRR_RL_Obj_ID_26 "E2E_Order41";
CM_ SG_ 623 S4_SRR_RL_Obj_DistX_26 "E2E_Order42";
CM_ SG_ 623 S4_SRR_RL_Obj_RelVelX_26 "E2E_Order43";
CM_ SG_ 623 S4_SRR_RL_Obj_AccelX_26 "E2E_Order44";
CM_ SG_ 623 S4_SRR_RL_Obj_DistY_26 "E2E_Order45";
CM_ SG_ 623 S4_SRR_RL_Obj_RelVelY_26 "E2E_Order46";
CM_ SG_ 623 S4_SRR_RL_Obj_AccelY_26 "E2E_Order47";
CM_ SG_ 623 S4_SRR_RL_Obj_DistXStd_26 "E2E_Order48";
CM_ SG_ 623 S4_SRR_RL_Obj_RelVelXStd_26 "E2E_Order49";
CM_ SG_ 623 S4_SRR_RL_Obj_RAccelXStd_26 "E2E_Order50";
CM_ SG_ 623 S4_SRR_RL_Obj_DistYStd_26 "E2E_Order51";
CM_ SG_ 623 S4_SRR_RL_Obj_RelVelYStd_26 "E2E_Order52";
CM_ SG_ 623 S4_SRR_RL_Obj_RAccelYStd_26 "E2E_Order53";
CM_ SG_ 623 S4_SRR_RL_Obj_ValidFlag_26 "E2E_Order54";
CM_ SG_ 623 S4_SRR_RL_Obj_UpdateFlag_26 "E2E_Order55";
CM_ SG_ 623 S4_SRR_RL_Obj_ExistProb_26 "E2E_Order56";
CM_ SG_ 623 S4_SRR_RL_Obj_Type_26 "E2E_Order57";
CM_ SG_ 623 S4_SRR_RL_Obj_EDynProp_26 "E2E_Order58";
CM_ SG_ 623 S4_SRR_RL_Obj_UiLifeCycles_26 "E2E_Order59";
CM_ SG_ 623 S4_SRR_RL_Obj_RCS_26 "E2E_Order60";
CM_ SG_ 623 S4_SRR_RL_Obj_8_E2EChecksum "DataID = 0x0F62";
CM_ BO_ 624 "The sending period is unstable, ranging from 40 to 80ms
E2E Profile1 Message";
CM_ SG_ 624 S4_SRR_RL_Obj_ID_27 "E2E_Order1";
CM_ SG_ 624 S4_SRR_RL_Obj_DistX_27 "E2E_Order2";
CM_ SG_ 624 S4_SRR_RL_Obj_RelVelX_27 "E2E_Order3";
CM_ SG_ 624 S4_SRR_RL_Obj_AccelX_27 "E2E_Order4";
CM_ SG_ 624 S4_SRR_RL_Obj_DistY_27 "E2E_Order5";
CM_ SG_ 624 S4_SRR_RL_Obj_RelVelY_27 "E2E_Order6";
CM_ SG_ 624 S4_SRR_RL_Obj_AccelY_27 "E2E_Order7";
CM_ SG_ 624 S4_SRR_RL_Obj_DistXStd_27 "E2E_Order8";
CM_ SG_ 624 S4_SRR_RL_Obj_RelVelXStd_27 "E2E_Order9";
CM_ SG_ 624 S4_SRR_RL_Obj_RAccelXStd_27 "E2E_Order10";
CM_ SG_ 624 S4_SRR_RL_Obj_DistYStd_27 "E2E_Order11";
CM_ SG_ 624 S4_SRR_RL_Obj_RelVelYStd_27 "E2E_Order12";
CM_ SG_ 624 S4_SRR_RL_Obj_RAccelYStd_27 "E2E_Order13";
CM_ SG_ 624 S4_SRR_RL_Obj_ValidFlag_27 "E2E_Order14";
CM_ SG_ 624 S4_SRR_RL_Obj_UpdateFlag_27 "E2E_Order15";
CM_ SG_ 624 S4_SRR_RL_Obj_ExistProb_27 "E2E_Order16";
CM_ SG_ 624 S4_SRR_RL_Obj_Type_27 "E2E_Order17";
CM_ SG_ 624 S4_SRR_RL_Obj_EDynProp_27 "E2E_Order18";
CM_ SG_ 624 S4_SRR_RL_Obj_UiLifeCycles_27 "E2E_Order19";
CM_ SG_ 624 S4_SRR_RL_Obj_RCS_27 "E2E_Order20";
CM_ SG_ 624 S4_SRR_RL_Obj_ID_28 "E2E_Order21";
CM_ SG_ 624 S4_SRR_RL_Obj_DistX_28 "E2E_Order22";
CM_ SG_ 624 S4_SRR_RL_Obj_RelVelX_28 "E2E_Order23";
CM_ SG_ 624 S4_SRR_RL_Obj_AccelX_28 "E2E_Order24";
CM_ SG_ 624 S4_SRR_RL_Obj_DistY_28 "E2E_Order25";
CM_ SG_ 624 S4_SRR_RL_Obj_RelVelY_28 "E2E_Order26";
CM_ SG_ 624 S4_SRR_RL_Obj_AccelY_28 "E2E_Order27";
CM_ SG_ 624 S4_SRR_RL_Obj_DistXStd_28 "E2E_Order28";
CM_ SG_ 624 S4_SRR_RL_Obj_RelVelXStd_28 "E2E_Order29";
CM_ SG_ 624 S4_SRR_RL_Obj_RAccelXStd_28 "E2E_Order30";
CM_ SG_ 624 S4_SRR_RL_Obj_DistYStd_28 "E2E_Order31";
CM_ SG_ 624 S4_SRR_RL_Obj_RelVelYStd_28 "E2E_Order32";
CM_ SG_ 624 S4_SRR_RL_Obj_RAccelYStd_28 "E2E_Order33";
CM_ SG_ 624 S4_SRR_RL_Obj_ValidFlag_28 "E2E_Order34";
CM_ SG_ 624 S4_SRR_RL_Obj_UpdateFlag_28 "E2E_Order35";
CM_ SG_ 624 S4_SRR_RL_Obj_ExistProb_28 "E2E_Order36";
CM_ SG_ 624 S4_SRR_RL_Obj_Type_28 "E2E_Order37";
CM_ SG_ 624 S4_SRR_RL_Obj_EDynProp_28 "E2E_Order38";
CM_ SG_ 624 S4_SRR_RL_Obj_UiLifeCycles_28 "E2E_Order39";
CM_ SG_ 624 S4_SRR_RL_Obj_RCS_28 "E2E_Order40";
CM_ SG_ 624 S4_SRR_RL_Obj_ID_29 "E2E_Order41";
CM_ SG_ 624 S4_SRR_RL_Obj_DistX_29 "E2E_Order42";
CM_ SG_ 624 S4_SRR_RL_Obj_RelVelX_29 "E2E_Order43";
CM_ SG_ 624 S4_SRR_RL_Obj_AccelX_29 "E2E_Order44";
CM_ SG_ 624 S4_SRR_RL_Obj_DistY_29 "E2E_Order45";
CM_ SG_ 624 S4_SRR_RL_Obj_RelVelY_29 "E2E_Order46";
CM_ SG_ 624 S4_SRR_RL_Obj_AccelY_29 "E2E_Order47";
CM_ SG_ 624 S4_SRR_RL_Obj_DistXStd_29 "E2E_Order48";
CM_ SG_ 624 S4_SRR_RL_Obj_RelVelXStd_29 "E2E_Order49";
CM_ SG_ 624 S4_SRR_RL_Obj_RAccelXStd_29 "E2E_Order50";
CM_ SG_ 624 S4_SRR_RL_Obj_DistYStd_29 "E2E_Order51";
CM_ SG_ 624 S4_SRR_RL_Obj_RelVelYStd_29 "E2E_Order52";
CM_ SG_ 624 S4_SRR_RL_Obj_RAccelYStd_29 "E2E_Order53";
CM_ SG_ 624 S4_SRR_RL_Obj_ValidFlag_29 "E2E_Order54";
CM_ SG_ 624 S4_SRR_RL_Obj_UpdateFlag_29 "E2E_Order55";
CM_ SG_ 624 S4_SRR_RL_Obj_ExistProb_29 "E2E_Order56";
CM_ SG_ 624 S4_SRR_RL_Obj_Type_29 "E2E_Order57";
CM_ SG_ 624 S4_SRR_RL_Obj_EDynProp_29 "E2E_Order58";
CM_ SG_ 624 S4_SRR_RL_Obj_UiLifeCycles_29 "E2E_Order59";
CM_ SG_ 624 S4_SRR_RL_Obj_RCS_29 "E2E_Order60";
CM_ SG_ 624 S4_SRR_RL_Obj_9_E2EChecksum "DataID = 0x0072";
CM_ BO_ 627 "The sending period is unstable, ranging from 40 to 80ms
E2E Profile1 Message";
CM_ SG_ 627 S4_SRR_RL_Obj_ID_30 "E2E_Order1";
CM_ SG_ 627 S4_SRR_RL_Obj_DistX_30 "E2E_Order2";
CM_ SG_ 627 S4_SRR_RL_Obj_RelVelX_30 "E2E_Order3";
CM_ SG_ 627 S4_SRR_RL_Obj_AccelX_30 "E2E_Order4";
CM_ SG_ 627 S4_SRR_RL_Obj_DistY_30 "E2E_Order5";
CM_ SG_ 627 S4_SRR_RL_Obj_RelVelY_30 "E2E_Order6";
CM_ SG_ 627 S4_SRR_RL_Obj_AccelY_30 "E2E_Order7";
CM_ SG_ 627 S4_SRR_RL_Obj_DistXStd_30 "E2E_Order8";
CM_ SG_ 627 S4_SRR_RL_Obj_RelVelXStd_30 "E2E_Order9";
CM_ SG_ 627 S4_SRR_RL_Obj_RAccelXStd_30 "E2E_Order10";
CM_ SG_ 627 S4_SRR_RL_Obj_DistYStd_30 "E2E_Order11";
CM_ SG_ 627 S4_SRR_RL_Obj_RelVelYStd_30 "E2E_Order12";
CM_ SG_ 627 S4_SRR_RL_Obj_RAccelYStd_30 "E2E_Order13";
CM_ SG_ 627 S4_SRR_RL_Obj_ValidFlag_30 "E2E_Order14";
CM_ SG_ 627 S4_SRR_RL_Obj_UpdateFlag_30 "E2E_Order15";
CM_ SG_ 627 S4_SRR_RL_Obj_ExistProb_30 "E2E_Order16";
CM_ SG_ 627 S4_SRR_RL_Obj_Type_30 "E2E_Order17";
CM_ SG_ 627 S4_SRR_RL_Obj_EDynProp_30 "E2E_Order18";
CM_ SG_ 627 S4_SRR_RL_Obj_UiLifeCycles_30 "E2E_Order19";
CM_ SG_ 627 S4_SRR_RL_Obj_RCS_30 "E2E_Order20";
CM_ SG_ 627 S4_SRR_RL_Obj_ID_31 "E2E_Order21";
CM_ SG_ 627 S4_SRR_RL_Obj_DistX_31 "E2E_Order22";
CM_ SG_ 627 S4_SRR_RL_Obj_RelVelX_31 "E2E_Order23";
CM_ SG_ 627 S4_SRR_RL_Obj_AccelX_31 "E2E_Order24";
CM_ SG_ 627 S4_SRR_RL_Obj_DistY_31 "E2E_Order25";
CM_ SG_ 627 S4_SRR_RL_Obj_RelVelY_31 "E2E_Order26";
CM_ SG_ 627 S4_SRR_RL_Obj_AccelY_31 "E2E_Order27";
CM_ SG_ 627 S4_SRR_RL_Obj_DistXStd_31 "E2E_Order28";
CM_ SG_ 627 S4_SRR_RL_Obj_RelVelXStd_31 "E2E_Order29";
CM_ SG_ 627 S4_SRR_RL_Obj_RAccelXStd_31 "E2E_Order30";
CM_ SG_ 627 S4_SRR_RL_Obj_DistYStd_31 "E2E_Order31";
CM_ SG_ 627 S4_SRR_RL_Obj_RelVelYStd_31 "E2E_Order32";
CM_ SG_ 627 S4_SRR_RL_Obj_RAccelYStd_31 "E2E_Order33";
CM_ SG_ 627 S4_SRR_RL_Obj_ValidFlag_31 "E2E_Order34";
CM_ SG_ 627 S4_SRR_RL_Obj_UpdateFlag_31 "E2E_Order35";
CM_ SG_ 627 S4_SRR_RL_Obj_ExistProb_31 "E2E_Order36";
CM_ SG_ 627 S4_SRR_RL_Obj_Type_31 "E2E_Order37";
CM_ SG_ 627 S4_SRR_RL_Obj_EDynProp_31 "E2E_Order38";
CM_ SG_ 627 S4_SRR_RL_Obj_UiLifeCycles_31 "E2E_Order39";
CM_ SG_ 627 S4_SRR_RL_Obj_RCS_31 "E2E_Order40";
CM_ SG_ 627 S4_SRR_RL_Obj_ID_32 "E2E_Order41";
CM_ SG_ 627 S4_SRR_RL_Obj_DistX_32 "E2E_Order42";
CM_ SG_ 627 S4_SRR_RL_Obj_RelVelX_32 "E2E_Order43";
CM_ SG_ 627 S4_SRR_RL_Obj_AccelX_32 "E2E_Order44";
CM_ SG_ 627 S4_SRR_RL_Obj_DistY_32 "E2E_Order45";
CM_ SG_ 627 S4_SRR_RL_Obj_RelVelY_32 "E2E_Order46";
CM_ SG_ 627 S4_SRR_RL_Obj_AccelY_32 "E2E_Order47";
CM_ SG_ 627 S4_SRR_RL_Obj_DistXStd_32 "E2E_Order48";
CM_ SG_ 627 S4_SRR_RL_Obj_RelVelXStd_32 "E2E_Order49";
CM_ SG_ 627 S4_SRR_RL_Obj_RAccelXStd_32 "E2E_Order50";
CM_ SG_ 627 S4_SRR_RL_Obj_DistYStd_32 "E2E_Order51";
CM_ SG_ 627 S4_SRR_RL_Obj_RelVelYStd_32 "E2E_Order52";
CM_ SG_ 627 S4_SRR_RL_Obj_RAccelYStd_32 "E2E_Order53";
CM_ SG_ 627 S4_SRR_RL_Obj_ValidFlag_32 "E2E_Order54";
CM_ SG_ 627 S4_SRR_RL_Obj_UpdateFlag_32 "E2E_Order55";
CM_ SG_ 627 S4_SRR_RL_Obj_ExistProb_32 "E2E_Order56";
CM_ SG_ 627 S4_SRR_RL_Obj_Type_32 "E2E_Order57";
CM_ SG_ 627 S4_SRR_RL_Obj_EDynProp_32 "E2E_Order58";
CM_ SG_ 627 S4_SRR_RL_Obj_UiLifeCycles_32 "E2E_Order59";
CM_ SG_ 627 S4_SRR_RL_Obj_RCS_32 "E2E_Order60";
CM_ SG_ 627 S4_SRR_RL_Obj_10_E2EChecksum "DataID = 0x0372";
CM_ BO_ 629 "The sending period is unstable, ranging from 40 to 80ms
E2E Profile1 Message";
CM_ SG_ 629 S4_SRR_RL_Obj_ID_33 "E2E_Order1";
CM_ SG_ 629 S4_SRR_RL_Obj_DistX_33 "E2E_Order2";
CM_ SG_ 629 S4_SRR_RL_Obj_RelVelX_33 "E2E_Order3";
CM_ SG_ 629 S4_SRR_RL_Obj_AccelX_33 "E2E_Order4";
CM_ SG_ 629 S4_SRR_RL_Obj_DistY_33 "E2E_Order5";
CM_ SG_ 629 S4_SRR_RL_Obj_RelVelY_33 "E2E_Order6";
CM_ SG_ 629 S4_SRR_RL_Obj_AccelY_33 "E2E_Order7";
CM_ SG_ 629 S4_SRR_RL_Obj_DistXStd_33 "E2E_Order8";
CM_ SG_ 629 S4_SRR_RL_Obj_RelVelXStd_33 "E2E_Order9";
CM_ SG_ 629 S4_SRR_RL_Obj_RAccelXStd_33 "E2E_Order10";
CM_ SG_ 629 S4_SRR_RL_Obj_DistYStd_33 "E2E_Order11";
CM_ SG_ 629 S4_SRR_RL_Obj_RelVelYStd_33 "E2E_Order12";
CM_ SG_ 629 S4_SRR_RL_Obj_RAccelYStd_33 "E2E_Order13";
CM_ SG_ 629 S4_SRR_RL_Obj_ValidFlag_33 "E2E_Order14";
CM_ SG_ 629 S4_SRR_RL_Obj_UpdateFlag_33 "E2E_Order15";
CM_ SG_ 629 S4_SRR_RL_Obj_ExistProb_33 "E2E_Order16";
CM_ SG_ 629 S4_SRR_RL_Obj_Type_33 "E2E_Order17";
CM_ SG_ 629 S4_SRR_RL_Obj_EDynProp_33 "E2E_Order18";
CM_ SG_ 629 S4_SRR_RL_Obj_UiLifeCycles_33 "E2E_Order19";
CM_ SG_ 629 S4_SRR_RL_Obj_RCS_33 "E2E_Order20";
CM_ SG_ 629 S4_SRR_RL_Obj_ID_34 "E2E_Order21";
CM_ SG_ 629 S4_SRR_RL_Obj_DistX_34 "E2E_Order22";
CM_ SG_ 629 S4_SRR_RL_Obj_RelVelX_34 "E2E_Order23";
CM_ SG_ 629 S4_SRR_RL_Obj_AccelX_34 "E2E_Order24";
CM_ SG_ 629 S4_SRR_RL_Obj_DistY_34 "E2E_Order25";
CM_ SG_ 629 S4_SRR_RL_Obj_RelVelY_34 "E2E_Order26";
CM_ SG_ 629 S4_SRR_RL_Obj_AccelY_34 "E2E_Order27";
CM_ SG_ 629 S4_SRR_RL_Obj_DistXStd_34 "E2E_Order28";
CM_ SG_ 629 S4_SRR_RL_Obj_RelVelXStd_34 "E2E_Order29";
CM_ SG_ 629 S4_SRR_RL_Obj_RAccelXStd_34 "E2E_Order30";
CM_ SG_ 629 S4_SRR_RL_Obj_DistYStd_34 "E2E_Order31";
CM_ SG_ 629 S4_SRR_RL_Obj_RelVelYStd_34 "E2E_Order32";
CM_ SG_ 629 S4_SRR_RL_Obj_RAccelYStd_34 "E2E_Order33";
CM_ SG_ 629 S4_SRR_RL_Obj_ValidFlag_34 "E2E_Order34";
CM_ SG_ 629 S4_SRR_RL_Obj_UpdateFlag_34 "E2E_Order35";
CM_ SG_ 629 S4_SRR_RL_Obj_ExistProb_34 "E2E_Order36";
CM_ SG_ 629 S4_SRR_RL_Obj_Type_34 "E2E_Order37";
CM_ SG_ 629 S4_SRR_RL_Obj_EDynProp_34 "E2E_Order38";
CM_ SG_ 629 S4_SRR_RL_Obj_UiLifeCycles_34 "E2E_Order39";
CM_ SG_ 629 S4_SRR_RL_Obj_RCS_34 "E2E_Order40";
CM_ SG_ 629 S4_SRR_RL_Obj_ID_35 "E2E_Order41";
CM_ SG_ 629 S4_SRR_RL_Obj_DistX_35 "E2E_Order42";
CM_ SG_ 629 S4_SRR_RL_Obj_RelVelX_35 "E2E_Order43";
CM_ SG_ 629 S4_SRR_RL_Obj_AccelX_35 "E2E_Order44";
CM_ SG_ 629 S4_SRR_RL_Obj_DistY_35 "E2E_Order45";
CM_ SG_ 629 S4_SRR_RL_Obj_RelVelY_35 "E2E_Order46";
CM_ SG_ 629 S4_SRR_RL_Obj_AccelY_35 "E2E_Order47";
CM_ SG_ 629 S4_SRR_RL_Obj_DistXStd_35 "E2E_Order48";
CM_ SG_ 629 S4_SRR_RL_Obj_RelVelXStd_35 "E2E_Order49";
CM_ SG_ 629 S4_SRR_RL_Obj_RAccelXStd_35 "E2E_Order50";
CM_ SG_ 629 S4_SRR_RL_Obj_DistYStd_35 "E2E_Order51";
CM_ SG_ 629 S4_SRR_RL_Obj_RelVelYStd_35 "E2E_Order52";
CM_ SG_ 629 S4_SRR_RL_Obj_RAccelYStd_35 "E2E_Order53";
CM_ SG_ 629 S4_SRR_RL_Obj_ValidFlag_35 "E2E_Order54";
CM_ SG_ 629 S4_SRR_RL_Obj_UpdateFlag_35 "E2E_Order55";
CM_ SG_ 629 S4_SRR_RL_Obj_ExistProb_35 "E2E_Order56";
CM_ SG_ 629 S4_SRR_RL_Obj_Type_35 "E2E_Order57";
CM_ SG_ 629 S4_SRR_RL_Obj_EDynProp_35 "E2E_Order58";
CM_ SG_ 629 S4_SRR_RL_Obj_UiLifeCycles_35 "E2E_Order59";
CM_ SG_ 629 S4_SRR_RL_Obj_RCS_35 "E2E_Order60";
CM_ SG_ 629 S4_SRR_RL_Obj_11_E2EChecksum "DataID = 0x0572";
CM_ BO_ 630 "The sending period is unstable, ranging from 40 to 80ms
E2E Profile1 Message";
CM_ SG_ 630 S4_SRR_RL_Obj_ID_36 "E2E_Order1";
CM_ SG_ 630 S4_SRR_RL_Obj_DistX_36 "E2E_Order2";
CM_ SG_ 630 S4_SRR_RL_Obj_RelVelX_36 "E2E_Order3";
CM_ SG_ 630 S4_SRR_RL_Obj_AccelX_36 "E2E_Order4";
CM_ SG_ 630 S4_SRR_RL_Obj_DistY_36 "E2E_Order5";
CM_ SG_ 630 S4_SRR_RL_Obj_RelVelY_36 "E2E_Order6";
CM_ SG_ 630 S4_SRR_RL_Obj_AccelY_36 "E2E_Order7";
CM_ SG_ 630 S4_SRR_RL_Obj_DistXStd_36 "E2E_Order8";
CM_ SG_ 630 S4_SRR_RL_Obj_RelVelXStd_36 "E2E_Order9";
CM_ SG_ 630 S4_SRR_RL_Obj_RAccelXStd_36 "E2E_Order10";
CM_ SG_ 630 S4_SRR_RL_Obj_DistYStd_36 "E2E_Order11";
CM_ SG_ 630 S4_SRR_RL_Obj_RelVelYStd_36 "E2E_Order12";
CM_ SG_ 630 S4_SRR_RL_Obj_RAccelYStd_36 "E2E_Order13";
CM_ SG_ 630 S4_SRR_RL_Obj_ValidFlag_36 "E2E_Order14";
CM_ SG_ 630 S4_SRR_RL_Obj_UpdateFlag_36 "E2E_Order15";
CM_ SG_ 630 S4_SRR_RL_Obj_ExistProb_36 "E2E_Order16";
CM_ SG_ 630 S4_SRR_RL_Obj_Type_36 "E2E_Order17";
CM_ SG_ 630 S4_SRR_RL_Obj_EDynProp_36 "E2E_Order18";
CM_ SG_ 630 S4_SRR_RL_Obj_UiLifeCycles_36 "E2E_Order19";
CM_ SG_ 630 S4_SRR_RL_Obj_RCS_36 "E2E_Order20";
CM_ SG_ 630 S4_SRR_RL_Obj_ID_37 "E2E_Order21";
CM_ SG_ 630 S4_SRR_RL_Obj_DistX_37 "E2E_Order22";
CM_ SG_ 630 S4_SRR_RL_Obj_RelVelX_37 "E2E_Order23";
CM_ SG_ 630 S4_SRR_RL_Obj_AccelX_37 "E2E_Order24";
CM_ SG_ 630 S4_SRR_RL_Obj_DistY_37 "E2E_Order25";
CM_ SG_ 630 S4_SRR_RL_Obj_RelVelY_37 "E2E_Order26";
CM_ SG_ 630 S4_SRR_RL_Obj_AccelY_37 "E2E_Order27";
CM_ SG_ 630 S4_SRR_RL_Obj_DistXStd_37 "E2E_Order28";
CM_ SG_ 630 S4_SRR_RL_Obj_RelVelXStd_37 "E2E_Order29";
CM_ SG_ 630 S4_SRR_RL_Obj_RAccelXStd_37 "E2E_Order30";
CM_ SG_ 630 S4_SRR_RL_Obj_DistYStd_37 "E2E_Order31";
CM_ SG_ 630 S4_SRR_RL_Obj_RelVelYStd_37 "E2E_Order32";
CM_ SG_ 630 S4_SRR_RL_Obj_RAccelYStd_37 "E2E_Order33";
CM_ SG_ 630 S4_SRR_RL_Obj_ValidFlag_37 "E2E_Order34";
CM_ SG_ 630 S4_SRR_RL_Obj_UpdateFlag_37 "E2E_Order35";
CM_ SG_ 630 S4_SRR_RL_Obj_ExistProb_37 "E2E_Order36";
CM_ SG_ 630 S4_SRR_RL_Obj_Type_37 "E2E_Order37";
CM_ SG_ 630 S4_SRR_RL_Obj_EDynProp_37 "E2E_Order38";
CM_ SG_ 630 S4_SRR_RL_Obj_UiLifeCycles_37 "E2E_Order39";
CM_ SG_ 630 S4_SRR_RL_Obj_RCS_37 "E2E_Order40";
CM_ SG_ 630 S4_SRR_RL_Obj_ID_38 "E2E_Order41";
CM_ SG_ 630 S4_SRR_RL_Obj_DistX_38 "E2E_Order42";
CM_ SG_ 630 S4_SRR_RL_Obj_RelVelX_38 "E2E_Order43";
CM_ SG_ 630 S4_SRR_RL_Obj_AccelX_38 "E2E_Order44";
CM_ SG_ 630 S4_SRR_RL_Obj_DistY_38 "E2E_Order45";
CM_ SG_ 630 S4_SRR_RL_Obj_RelVelY_38 "E2E_Order46";
CM_ SG_ 630 S4_SRR_RL_Obj_AccelY_38 "E2E_Order47";
CM_ SG_ 630 S4_SRR_RL_Obj_DistXStd_38 "E2E_Order48";
CM_ SG_ 630 S4_SRR_RL_Obj_RelVelXStd_38 "E2E_Order49";
CM_ SG_ 630 S4_SRR_RL_Obj_RAccelXStd_38 "E2E_Order50";
CM_ SG_ 630 S4_SRR_RL_Obj_DistYStd_38 "E2E_Order51";
CM_ SG_ 630 S4_SRR_RL_Obj_RelVelYStd_38 "E2E_Order52";
CM_ SG_ 630 S4_SRR_RL_Obj_RAccelYStd_38 "E2E_Order53";
CM_ SG_ 630 S4_SRR_RL_Obj_ValidFlag_38 "E2E_Order54";
CM_ SG_ 630 S4_SRR_RL_Obj_UpdateFlag_38 "E2E_Order55";
CM_ SG_ 630 S4_SRR_RL_Obj_ExistProb_38 "E2E_Order56";
CM_ SG_ 630 S4_SRR_RL_Obj_Type_38 "E2E_Order57";
CM_ SG_ 630 S4_SRR_RL_Obj_EDynProp_38 "E2E_Order58";
CM_ SG_ 630 S4_SRR_RL_Obj_UiLifeCycles_38 "E2E_Order59";
CM_ SG_ 630 S4_SRR_RL_Obj_RCS_38 "E2E_Order60";
CM_ SG_ 630 S4_SRR_RL_Obj_12_E2EChecksum "DataID = 0x0672";
CM_ BO_ 631 "The sending period is unstable, ranging from 40 to 80ms
E2E Profile1 Message";
CM_ SG_ 631 S4_SRR_RL_Obj_ID_39 "E2E_Order1";
CM_ SG_ 631 S4_SRR_RL_Obj_DistX_39 "E2E_Order2";
CM_ SG_ 631 S4_SRR_RL_Obj_RelVelX_39 "E2E_Order3";
CM_ SG_ 631 S4_SRR_RL_Obj_AccelX_39 "E2E_Order4";
CM_ SG_ 631 S4_SRR_RL_Obj_DistY_39 "E2E_Order5";
CM_ SG_ 631 S4_SRR_RL_Obj_RelVelY_39 "E2E_Order6";
CM_ SG_ 631 S4_SRR_RL_Obj_AccelY_39 "E2E_Order7";
CM_ SG_ 631 S4_SRR_RL_Obj_DistXStd_39 "E2E_Order8";
CM_ SG_ 631 S4_SRR_RL_Obj_RelVelXStd_39 "E2E_Order9";
CM_ SG_ 631 S4_SRR_RL_Obj_RAccelXStd_39 "E2E_Order10";
CM_ SG_ 631 S4_SRR_RL_Obj_DistYStd_39 "E2E_Order11";
CM_ SG_ 631 S4_SRR_RL_Obj_RelVelYStd_39 "E2E_Order12";
CM_ SG_ 631 S4_SRR_RL_Obj_RAccelYStd_39 "E2E_Order13";
CM_ SG_ 631 S4_SRR_RL_Obj_ValidFlag_39 "E2E_Order14";
CM_ SG_ 631 S4_SRR_RL_Obj_UpdateFlag_39 "E2E_Order15";
CM_ SG_ 631 S4_SRR_RL_Obj_ExistProb_39 "E2E_Order16";
CM_ SG_ 631 S4_SRR_RL_Obj_Type_39 "E2E_Order17";
CM_ SG_ 631 S4_SRR_RL_Obj_EDynProp_39 "E2E_Order18";
CM_ SG_ 631 S4_SRR_RL_Obj_UiLifeCycles_39 "E2E_Order19";
CM_ SG_ 631 S4_SRR_RL_Obj_RCS_39 "E2E_Order20";
CM_ SG_ 631 S4_SRR_RL_Obj_13_E2EChecksum "DataID = 0x0772";
CM_ SG_ 634 S4_SRR_RL_HWFailureSt "The SRR hardware failure status";
CM_ SG_ 634 S4_SRR_RL_Modulation_Status "The sensor shall provide its modulation state";
CM_ SG_ 634 S4_SRR_RL_CalibratedSt "SRR_RL Calibration status";
CM_ SG_ 634 S4_SRR_RL_Assist_CRC16Checksum "CRC16";
CM_ SG_ 950 S4_SRR_RL_VBAT_HIGH "voltage>16V, duration>3s";
CM_ SG_ 950 S4_SRR_RL_VBAT_LOW "voltage<9V, duration>3s";
CM_ SG_ 950 S4_SRR_RL_SFCAN_CANBUS "3 consecutive Bus-off";
CM_ SG_ 950 S4_SRR_RL_XPU_TIMEOUT "Any monitored message is missing for 10 times continuously
(monitored messages: choose at least one message every cycle as monitored messages)
S4_XPU_SRR_ECUConfig(0x313)
XPU_SYNC_FC 3AB";
CM_ SG_ 950 S4_SRR_RL_OVERTEMP_FAIL "When SRR working temperature > 140¡ã";
CM_ SG_ 950 S4_SRR_RL_UNDERTEMP_FAIL "When SRR working temperature <-37¡ã";
CM_ SG_ 950 S4_SRR_RL_RFCOM_ERROR "When the MMIC Communication errors detected.";
CM_ SG_ 950 S4_SRR_RL_SPT_ERROR "When signal processing error is detected.";
CM_ SG_ 950 S4_SRR_RL_RFWAVE_CHECK_ERROR "When the radio frequence waves detected are abnormal as expected.";
CM_ SG_ 950 S4_SRR_RL_SWEXETIMING_VIOLATION "When software running time is lager than expected range./ Watchdog error happen.";
CM_ SG_ 950 S4_SRR_RL_SRR_PERMHW_FAIL "SRR Hardware Permanent error is detected.";
CM_ SG_ 950 S4_SRR_RL_ECU_SELFTEST_FAIL "SRR self test not passed";
CM_ SG_ 950 S4_SRR_RL_SWHW_COMPAT_CHECK "During each ECU start up, Software monitoring check the hardware and software compatibility not passed. ";
CM_ SG_ 950 S4_SRR_RL_PLCM_SYS_ERROR "When Power Life Cycle Management system working abnormal.";
CM_ SG_ 950 S4_SRR_RL_RF_VOLT_FAULT "MMIC Voltage Fault is detected";
CM_ SG_ 950 S4_SRR_RL_RF_TEMP_FAULT "MMIC Temperature Fault is detected";
CM_ SG_ 950 S4_SRR_RL_SRR_NVM_FAIL "Internal non-volatile storage failure (wrong/corrupt data)";
CM_ SG_ 950 S4_SRR_RL_TIME_SYN_FAIL "the received time from master is different than the expected time with 5ms";
CM_ SG_ 950 S4_SRR_RL_SRR_POSNOTCONFIG "when Radar position not configued";
CM_ SG_ 950 S4_SRR_RL_SRR_POSCONFIG_FAIL "Radar Position Config wrong";
CM_ SG_ 950 S4_SRR_RL_SRR_POSCONFIG_UPDATE "Radar Position Config Updated when ignition on.";
CM_ SG_ 950 S4_SRR_RL_SRR_VDY_SIG_EXCEPTION "The calculated VDY signal, like  velocity, accerate, yawrate, has exception. 
Velocity Range: 0 to 115 m/s
Yawrate Range: -2.61799 to +2.61799 rad/s
Accelerate Range: -15 to +15 m/s^2

";
CM_ SG_ 950 S4_SRR_RL_CDCU_TotOdo_Miss_ERR "Monitored message is missing for 10 times continuously

CDCU_TotalOdoMeter 366";
CM_ SG_ 950 S4_SRR_RL_LDCU_SysSt_Miss_ERR "Monitored message is missing for 10 times continuously

LDCU_SysSt 117";
CM_ SG_ 950 S4_SRR_RL_LDCU_BSysSt1_Miss_ERR "Monitored message is missing for 10 times continuously

LDCU_BodySysSt1 224";
CM_ SG_ 950 S4_SRR_RL_RDCU_BSysSt1_Miss_ERR "Monitored message is missing for 10 times continuously

RDCU_BodySysSt1 225";
CM_ SG_ 950 S4_SRR_RL_RDCU_BSysSt2_Miss_ERR "Monitored message is missing for 10 times continuously

RDCU_BodySysSt2 227";
CM_ SG_ 950 S4_SRR_RL_ESP_SpdInfoF_Miss_ERR "Monitored message is missing for 10 times continuously

ESP_SpdInfoF 127";
CM_ SG_ 950 S4_SRR_RL_ESP_SpdInfoR_ERR "Monitored message is missing for 10 times continuously

ESP_SpdInfoR 128";
CM_ SG_ 950 S4_SRR_RL_ESP_SysSt_ERR "Monitored message is missing for 10 times continuously

ESP_SysSt 1A7";
CM_ SG_ 950 S4_SRR_RL_ESP_Accel_ERR "Monitored message is missing for 10 times continuously

ESP_Accel 1A8";
CM_ SG_ 950 S4_SRR_RL_ESP_AccelOffset_ERR "Monitored message is missing for 10 times continuously

ESP_AccelOffset 1A9";
CM_ SG_ 950 S4_SRR_RL_EPS_SASInfo_ERR "Monitored message is missing for 10 times continuously

EPS_SASInfo 115";
CM_ SG_ 950 S4_SRR_RL_TBOX_TimeInfo_ERR "Monitored message is missing for 10 times continuously

TBOX_TimeInfo 3A5";
CM_ SG_ 950 S4_SRR_RL_TBOX_GPSInfo_ERR "Monitored message is missing for 10 times continuously

TBOX_GPSInfo  2B4";
CM_ SG_ 950 S4_SRR_RL_LDCU_ALC_ERR "The Alivecounter value is repeated or the 
difference value more than 3 andstaty 10 cycle time
LDCU_SysSt 117";
CM_ SG_ 950 S4_SRR_RL_ESP_ALC_ERR "The Alivecounter value is repeated or the 
difference value more than 3 andstaty 10 cycle time
ESP_SpdInfoF 127
ESP_SpdInfoR 128
ESP_SysSt 1A7
ESP_Accel 1A8
ESP_AccelOffset 1A9";
CM_ SG_ 950 S4_SRR_RL_EPS_ALC_ERR "The Alivecounter value is repeated or the 
difference value more than 3 andstaty 10 cycle time
EPS_SASInfo 115";
CM_ SG_ 950 S4_SRR_RL_XPU_ALC_ERR "The Alivecounter value is repeated or the 
difference value more than 3 andstaty 10 cycle time
XPU_SRR 313";
CM_ SG_ 950 S4_SRR_RL_LDCU_CRC_ERR "The CheckSum Value error staty 10 cycle time
LDCU_SysSt 117";
CM_ SG_ 950 S4_SRR_RL_ESP_CRC_ERR "The CheckSum Value error staty 10 cycle time
ESP_SpdInfoF 127
ESP_SpdInfoR 128
ESP_SysSt 1A7
ESP_Accel 1A8
ESP_AccelOffset 1A9";
CM_ SG_ 950 S4_SRR_RL_EPS_CRC_ERR "The CheckSum Value error staty 10 cycle time
EPS_SASInfo 115";
CM_ SG_ 950 S4_SRR_RL_XPU_CRC_ERR "The CheckSum Value error staty 10 cycle time
XPU_SRR 313";
CM_ SG_ 950 S4_SRR_RL_ESP_WHLSPD_INVALID "ESP_WheelSpd at out of range  [0~240kmp]  or the ESP_WheelSpdVD value is not valid(0x0) stay 3 cylce";
CM_ SG_ 950 S4_SRR_RL_EPS_SASFAULT_INVALID "EPS_SASFault is fault";
CM_ SG_ 950 S4_SRR_RL_ESP_LGTACCE_INVALID "ESP_VehLongAccel at out of range  [-1.8~1.8g]  or the ESP_VehLongAccelVL value is not valid(0x0) stay 3 cylce or the               ESP_VehLongAccelOffsetValue is at out of range or invalid(FFF)           ";
CM_ SG_ 950 S4_SRR_RL_ESP_LATACCE_INVALID "ESP_VehLateralAccel at out of range  [-1.8~1.8g]  or the ESP_VehLateralAccelVL value is not valid(0x0) stay 3 cylce OR the ESP_VehLateralAccelOffsetValue is at out of range or INVALID(FFF)";
CM_ SG_ 950 S4_SRR_RL_ESP_YAWRATE_INVALID "ESP_YAWRate value at out of range [-93~93degps] or the ESP_YAWVD value is not valid(0x0) stay 3 cylce or ESP_YAWRateOffsetValue is invalid(FFF)";
CM_ SG_ 950 S4_SRR_RL_ESP_WHLMOVGDIR_IVD " ESP_WheelRotatedDirectionVN value is not valid(0x0) stay 3 cylce";
CM_ SG_ 950 S4_SRR_RL_EPS_SAVD_INVALID "Steering angle value is invalid(0x00) or Steering angle at out range of [-780~780 degree] stay 3 cylce";
CM_ SG_ 950 S4_SRR_RL_EPS_SASCALST_INVALID " EPS_SASCalibratedStVT value is not calibration(0x00) stay 3 cylce";
CM_ SG_ 950 S4_SRR_RL_LDCU_CurGearLev_ivd "LDCU_CurrentGearLev is invalid(0x00) stay 3 cylce";
CM_ SG_ 950 S4_SRR_RL_LDCU_AccPedalSig_IVD "LDCU_AccPedalSigVD signal is not valid£¨0x00£©";
CM_ SG_ 950 S4_SRR_RL_LDCU_BrkPedalSt_IVD "LDCU_BrkPedalStVD signal is not valid£¨0x00£©";
CM_ SG_ 950 S4_SRR_RL_EPS_SASPDSIG_IVD "Steering angle speed value is invalid(0x00) or Steering angle at out range of [0~1016 degree/s] stay 3 cylce";
CM_ SG_ 950 S4_SRR_RL_SRR_BLIND_FAIL "When SRR is detected blockage.";
CM_ SG_ 950 S4_SRR_RL_SENSOR_POS_FAIL "When SRR position deveation is out of noraml range.";
CM_ SG_ 950 S4_SRR_RL_SRR_NOT_ALN_FAIL "Alignment never performed.";
CM_ SG_ 950 S4_SRR_RL_SENSOR_MISALN_FAIL "SRR alignment failed.";
CM_ SG_ 787 S4_SRR_ECUConfig_MsgCounter "The MessageCounter is a 0 ~ 15 counter, increased of one unit on every message transmission";
CM_ SG_ 787 S4_SRR_ECUConfig_Checksum "XOR";
CM_ SG_ 939 S4_GlobalTimeMaster_B0 "0x20:Sync
0x28:Fup";
CM_ SG_ 939 S4_GlobalTimeMaster_B1 "Sync/Fup_CRC";
CM_ SG_ 939 S4_GlobalTimeMaster_B2 "Sync/Fup_TimeDomain";
CM_ SG_ 939 S4_GlobalTimeMaster_B3 "Sync:UserByte0
Fup:Reserved(5bit)+SGW(1bit)+OVS(2bit)";
CM_ SG_ 939 S4_GlobalTimeMaster_B4 "Sync(Byt4-Byte7):Sync_TimeSec
Fup(Byt4-Byte7):Fup_SyncTimeNSec";
CM_ SG_ 939 S4_GlobalTimeMaster_B5 "Sync(Byt4-Byte7):Sync_TimeSec
Fup(Byt4-Byte7):Fup_SyncTimeNSec";
CM_ SG_ 939 S4_GlobalTimeMaster_B6 "Sync(Byt4-Byte7):Sync_TimeSec
Fup(Byt4-Byte7):Fup_SyncTimeNSec";
CM_ SG_ 939 S4_GlobalTimeMaster_B7 "Sync(Byt4-Byte7):Sync_TimeSec
Fup(Byt4-Byte7):Fup_SyncTimeNSec";
CM_ SG_ 425 S4_IPB_VehLongAccelOffsetValue "0x0~0x4E2:valid value
invalid valve/Default value: FFF
vehicle longitudinal acceleration offset(the direction of vehicle move)when ESP_ActVehLongAccelVD=0x0:Not valid;ESP_VehLongAccel=0xFFF
rear of vehicle=negative
front of vehicle=positive";
CM_ SG_ 425 S4_IPB_VehLateralAccelOffsetValue "0x0~0x4E2:valid value
invalid valve/Default value: FFF
vehicle longitudinal acceleration offset(the direction of vehicle move)when ESP_ActVehLongAccelVD=0x0:Not valid;ESP_VehLongAccel=0xFFF
Wheel position to left=negative
Wheel position to right=positive
Wheel position straightforward=0(positive)";
CM_ SG_ 425 S4_IPB_YAWRateOffsetValue "0x0~0xBA0:valid value
invalid valve/Default value: FFF
this data indicates information regarding digital filtered yaw rate signal,when ESP_YAWVD=0x0:Not valid;ESP_YAW=0xFFF
Wheel position to left=negative
Wheel position to right=positive
Wheel position straightforward=0(positive)";
CM_ SG_ 425 S4_IPB_AccelOffsetMsgCounter "The MessageCounter is a 0 ~ 15 counter, increased of one unit on every message transmission";
CM_ SG_ 425 S4_IPB_AccelOffsetChecksum "XOR";
CM_ SG_ 279 S4_LDCU_CurrentGearLev "Current Gear lever";
CM_ SG_ 279 S4_LDCU_ExterTemp "External temperature";
CM_ SG_ 279 S4_LDCU_BrkPedalSt "Braking Signal for APB";
CM_ SG_ 279 S4_LDCU_AccPedalSigVD "the validity of Accelerator  Pedal  Sensor Signal";
CM_ SG_ 279 S4_LDCU_AccPedalSig "Accelerator  Pedal  Sensor Signal";
CM_ SG_ 279 S4_LDCU_SysStMsgCounter "The MessageCounter is a 0 ~ 15 counter, increased of one unit on every message transmission";
CM_ SG_ 279 S4_LDCU_SysStChecksum "XOR";
CM_ SG_ 870 S4_CDCU_TotalOdometer "Total odometer";
CM_ SG_ 539 S4_CDCU_BSDSwSt "BSD is turn ON or OFF";
CM_ SG_ 539 S4_CDCU_RCTASwSt "RCTA is turn ON or OFF";
CM_ SG_ 539 S4_CDCU_RCWSwSt "RCW is turn ON or OFF";
CM_ SG_ 539 S4_CDCU_DOWSwSt "DOW is turn ON or OFF";
CM_ SG_ 539 S4_CDCU_RadarEmissionSwSt "Radar is turn ON or OFF";
CM_ SG_ 399 S4_AS_DrvModSts "Drive Modes status";
CM_ SG_ 399 S4_AS_LvlChg "Level Changing Status";
CM_ SG_ 399 S4_AS_TarLvl "Target Level under current mode";
CM_ SG_ 658 S4_AS_wheelPosFLFilt_mm "Wheel position FL";
CM_ SG_ 658 S4_AS_wheelPosFRFilt_mm "Wheel position FR";
CM_ SG_ 658 S4_AS_wheelPosRLFilt_mm "Wheel position RL";
CM_ SG_ 658 S4_AS_wheelPosRRFilt_mm "Wheel position RR";
CM_ SG_ 658 S4_AS_PVlvBlk_kPa "Valve block pressure";
CM_ SG_ 658 S4_AS_LvlFLVD "Validation data for FL level sensor";
CM_ SG_ 658 S4_AS_LvlFRVD "Validation data for FR level sensor";
CM_ SG_ 658 S4_AS_LvlRLVD "Validation data for RL level sensor";
CM_ SG_ 658 S4_AS_LvlRRVD "Validation data for RR level sensor";
CM_ SG_ 658 S4_AS_bodyHeaveAccRaw_g "IMU - Body acceleration on Z";
CM_ BO_ 281 "E2E Profile1 Message";
CM_ SG_ 281 S4_RWS_Wheelangle "E2E_Order1";
CM_ SG_ 281 S4_RWS_WheelangleValid "E2E_Order2";
CM_ SG_ 281 S4_RWS_SysWarning "E2E_Order3";
CM_ SG_ 281 S4_RWS_ActualSts "E2E_Order5";
CM_ SG_ 281 S4_RWS_EndVMCCtrlReason "E2E_Order4, reason why RWS quits ANGLE control mode";
CM_ SG_ 281 S4_RWS_Sys_RollingCounter "The initial value is 0, The value 0xF is skipped (after 0xE the next is 0x0), as 0xF value represents the error value.";
CM_ SG_ 281 S4_RWS_Sys_E2EChecksum "DataID = 0x0911";
CM_ BO_ 294 "E2E Profile1 Message";
CM_ SG_ 294 S4_IPB_FLWheelSpd_E2E "E2E_Order1
valid:0x0~0x5DBF
invalid valve/Default value: 7FFF";
CM_ SG_ 294 S4_IPB_FLWheelSpdVD_E2E "E2E_Order2";
CM_ SG_ 294 S4_IPB_FRWheelSpd_E2E "E2E_Order3
valid:0x0~0x5DBF
invalid valve/Default value: 7FFF";
CM_ SG_ 294 S4_IPB_FRWheelSpdVD_E2E "E2E_Order4";
CM_ SG_ 294 S4_IPB_VehSpd_E2E "E2E_Order5
valid:0x0~0x5DBF
invalid valve/Default value: 7FFF";
CM_ SG_ 294 S4_IPB_VehSpdVD_E2E "E2E_Order6";
CM_ SG_ 294 S4_IPB_RLWheelSpd_E2E "E2E_Order7
valid:0x0~0x5DBF
invalid valve/Default value: 7FFF";
CM_ SG_ 294 S4_IPB_RLWheelSpdVD_E2E "E2E_Order8";
CM_ SG_ 294 S4_IPB_RRWheelSpd_E2E "E2E_Order9
valid:0x0~0x5DBF
invalid valve/Default value: 7FFF";
CM_ SG_ 294 S4_IPB_RRWheelSpdVD_E2E "E2E_Order10";
CM_ SG_ 294 S4_IPB_SpdInfo1_E2EMsgCounter "The initial value is 0, The value 0xF is skipped (after 0xE the next is 0x0), as 0xF value represents the error value.";
CM_ SG_ 294 S4_IPB_SpdInfo1_E2EChecksum "DataID = 0x0621";
CM_ BO_ 422 "E2E Profile1 Message";
CM_ SG_ 422 S4_IPB_BrkPedalSt_E2E "E2E_Order1";
CM_ SG_ 422 S4_IPB_BrkPedalStVD_E2E "E2E_Order2";
CM_ SG_ 422 S4_IPB_CDPAvl_E2E "E2E_Order3, CDP(Controlled Deceleration for Parking brake) interface available";
CM_ SG_ 422 S4_IPB_HpsAcknowledge_E2E "E2E_Order4, Confirmation that hydraulic pressure support (HPS) is achieved by the hydraulics";
CM_ SG_ 422 S4_IPB_HpsAvailability_E2E "E2E_Order5, Availability of hydraulic pressure support (HPS)";
CM_ SG_ 422 S4_IPB_ABSFault_E2E "E2E_Order6, ABS system has detected a failure which does no allow a reliable ABS regulation and is therefore switched off";
CM_ SG_ 422 S4_IPB_ABSActSt_E2E "E2E_Order7, Indication that ABS system currently performs a brake intervention";
CM_ SG_ 422 S4_IPB_VDCActSt_E2E "E2E_Order8, Indicates VDC in active or not";
CM_ SG_ 422 S4_IPB_TCSActSt_E2E "E2E_Order9, Indicates TCS in active or not";
CM_ SG_ 422 S4_IPB_BrkLightOnReq_E2E "E2E_Order10, Request to ignite the brake light";
CM_ SG_ 422 S4_IPB_CDDFaultSt_E2E "E2E_Order11, indicates CDD error";
CM_ SG_ 422 S4_IPB_CddAvl_E2E "E2E_Order12, indicates CDD is available or not";
CM_ SG_ 422 S4_IPB_VehLongAccel_E2E "E2E_Order13
0x0~0x4E2:valid value
invalid valve/Default value: FFF
vehicle longitudinal acceleration after offset(the direction of vehicle move)when ESP_ActVehLongAccelVD=0x0:Not valid;ESP_VehLongAccel=0xFFF
rear of vehicle=negative
front of vehicle=positive";
CM_ SG_ 422 S4_IPB_VehLateralAccel_E2E "E2E_Order14
0x0~0x4E2:valid value
invalid valve/Default value: FFF
vehicle longitudinal acceleration after offset(the direction of vehicle move)when ESP_ActVehLongAccelVD=0x0:Not valid;ESP_VehLongAccel=0xFFF
Wheel position to left=negative
Wheel position to right=positive
Wheel position straightforward=0(positive)";
CM_ SG_ 422 S4_IPB_VehLongAccelVD_E2E "E2E_Order15";
CM_ SG_ 422 S4_IPB_VehLateralAccelVD_E2E "E2E_Order16";
CM_ SG_ 422 S4_IPB_YAWRate_E2E "E2E_Order17
0x0~0xBA0:valid value
invalid valve/Default value: FFF
this data indicates information regarding digital filtered yaw rate signal,when ESP_YAWVD=0x0:Not valid;ESP_YAW=0xFFF
Wheel position to left=negative
Wheel position to right=positive
Wheel position straightforward=0(positive)";
CM_ SG_ 422 S4_IPB_YAWRateVD_E2E "E2E_Order18";
CM_ SG_ 422 S4_IPB_FLWheelRotatedDirct_E2E "E2E_Order19, FL wheel  Moving direction";
CM_ SG_ 422 S4_IPB_FLWheelRotatedDirctVD_E2E "E2E_Order20";
CM_ SG_ 422 S4_IPB_FRWheelRotatedDirct_E2E "E2E_Order21, FR wheel  Moving direction";
CM_ SG_ 422 S4_IPB_FRWheelRotatedDirctVD_E2E "E2E_Order22";
CM_ SG_ 422 S4_IPB_RLWheelRotatedDirct_E2E "E2E_Order23, RL wheel  Moving direction";
CM_ SG_ 422 S4_IPB_RLWheelRotatedDirctVD_E2E "E2E_Order24";
CM_ SG_ 422 S4_IPB_RRWheelRotatedDirct_E2E "E2E_Order25, RR wheel  Moving direction";
CM_ SG_ 422 S4_IPB_RRWheelRotatedDirctVD_E2E "E2E_Order27";
CM_ SG_ 422 S4_IPB_EPB_ParkReq_E2E "E2E_Order26";
CM_ SG_ 422 S4_IPB_SysSt_E2EMsgCounter "The initial value is 0, The value 0xF is skipped (after 0xE the next is 0x0), as 0xF value represents the error value.";
CM_ SG_ 422 S4_IPB_SysSt_E2EChecksum "DataID = 0x06A1";
CM_ BO_ 275 "E2E Profile1 Message";
CM_ SG_ 275 S4_EPS_SteeringAngleVD_E2E "E2E_Order1, SAS_SteeringAngle Valid Data";
CM_ SG_ 275 S4_EPS_SASCalibratedSt_E2E "E2E_Order2, the calibration information of steering angle sensor";
CM_ SG_ 275 S4_EPS_SASFault_E2E "E2E_Order3, SAS fault";
CM_ SG_ 275 S4_EPS_SASInterStFlags_E2E "E2E_Order4, H93 doesn't use";
CM_ SG_ 275 S4_EPS_SteeringAngle_E2E "E2E_Order5, 
steering wheel angle
Wheel position to left=positive
Wheel position to right=negative
Wheel position straightforward=0(positive)";
CM_ SG_ 275 S4_EPS_LDWCtrlSt_E2E "E2E_Order6";
CM_ SG_ 275 S4_EPS_PowerVoltage_E2E "E2E_Order7";
CM_ SG_ 275 S4_EPS_SteeringAngleSpd_E2E "E2E_Order8
steering wheel angle speed
left direction=positive
right direction=negative";
CM_ SG_ 275 S4_EPS_TorqCtrlMode "E2E_Order9";
CM_ SG_ 275 S4_EPS_SASInfo_E2EMsgCounter "The initial value is 0, The value 0xF is skipped (after 0xE the next is 0x0), as 0xF value represents the error value.";
CM_ SG_ 275 S4_EPS_SASInfo_E2EChecksum "DataID = 0x0311";
CM_ SG_ 423 S4_IPB_ABSFault "ABS system has detected a failure which does no allow a reliable ABS regulation and is therefore switched off";
CM_ SG_ 423 S4_IPB_ABSActSt "Indication that ABS system currently performs a brake intervention";
CM_ SG_ 423 S4_IPB_VDCActSt "Indicates VDC in active or not";
CM_ SG_ 423 S4_IPB_TCSActSt "Indicates TCS in active or not";
CM_ SG_ 423 S4_IPB_ESPPATA "indicate PATA pressed,when ESP function is deactivated£¬ESP_ESPPATA=0x2:Off,  when ESP function is in Sport Mode ESP_ESPPATA=0x1:sport;";
CM_ SG_ 423 S4_IPB_ESPFault "indicate TCS/VDC/DTC is fault";
CM_ SG_ 423 S4_IPB_StandStillSt "ndicates if CDD-S can hold the vehicle in standstill";
CM_ SG_ 423 S4_IPB_SysStMsgCounter "The MessageCounter is a 0 ~ 15 counter, increased of one unit on every message transmission";
CM_ SG_ 423 S4_IPB_SysStCRC8Checksum "CRC8";

BA_DEF_ BO_  "AliveTimeout" INT 0 100000;
BA_DEF_ BO_  "DiagDCM" ENUM  "Yes","No";
BA_DEF_ SG_  "InvalidHex" STRING ;
BA_DEF_ SG_  "GenSigEnvVarType" ENUM  "int","float","undef";
BA_DEF_ SG_  "GenSigStartValue" FLOAT 0 100000000000;
BA_DEF_ SG_  "GenSigSendType" ENUM  "Cyclic","OnWrite","OnWriteWithRepetition","OnChange","OnChangeWithRepetition","IfActive","IfActiveWithRepetition","NoSigSendType";
BA_DEF_ BO_  "DiagRequest" ENUM  "No","Yes";
BA_DEF_ BO_  "DiagResponse" ENUM  "No","Yes";
BA_DEF_ BO_  "CANFD_BRS" ENUM  "0","1";
BA_DEF_ BO_  "GenMsgCycleTimeFast" INT 0 100000;
BA_DEF_ BO_  "GenMsgNrOfRepetition" INT 0 100;
BA_DEF_ BO_  "NmMessage" ENUM  "No","Yes";
BA_DEF_ BO_  "GenMsgILSupport" ENUM  "No","Yes";
BA_DEF_ BO_  "GenMsgCycleTime" INT 0 15000;
BA_DEF_ BO_  "GenMsgSendType" ENUM  "FixedPeriodic","Event","EnabledPeriodic","Enable","NotUsed","EventPeriodic","NotUsed","NotUsed","NoMsgSendType";
BA_DEF_ BO_  "VFrameFormat" ENUM  "StandardCAN","ExtendedCAN","reserved","reserved","reserved","reserved","reserved","reserved","reserved","reserved","reserved","reserved","reserved","reserved","StandardCAN_FD","ExtendedCAN_FD";
BA_DEF_DEF_  "AliveTimeout" 0;
BA_DEF_DEF_  "DiagDCM" "No";
BA_DEF_DEF_  "InvalidHex" "";
BA_DEF_DEF_  "GenSigEnvVarType" "undef";
BA_DEF_DEF_  "GenSigStartValue" 0;
BA_DEF_DEF_  "GenSigSendType" "Cyclic";
BA_DEF_DEF_  "DiagRequest" "No";
BA_DEF_DEF_  "DiagResponse" "No";
BA_DEF_DEF_  "CANFD_BRS" "1";
BA_DEF_DEF_  "GenMsgCycleTimeFast" 0;
BA_DEF_DEF_  "GenMsgNrOfRepetition" 3;
BA_DEF_DEF_  "NmMessage" "No";
BA_DEF_DEF_  "GenMsgILSupport" "Yes";
BA_DEF_DEF_  "GenMsgCycleTime" 0;
BA_DEF_DEF_  "GenMsgSendType" "NoMsgSendType";
BA_DEF_DEF_  "VFrameFormat" "StandardCAN";
BA_ "VFrameFormat" BO_ 618 14;
BA_ "GenMsgSendType" BO_ 618 0;
BA_ "GenMsgCycleTime" BO_ 618 50;
BA_ "InvalidHex" SG_ 618 S4_SRR_RL_Obj_ID_9 "0x7F";
BA_ "GenSigStartValue" SG_ 618 S4_SRR_RL_Obj_DistX_9 15;
BA_ "GenSigStartValue" SG_ 618 S4_SRR_RL_Obj_DistY_9 15;
BA_ "GenSigStartValue" SG_ 618 S4_SRR_RL_Obj_ValidFlag_9 1;
BA_ "InvalidHex" SG_ 618 S4_SRR_RL_Obj_ID_10 "0x7F";
BA_ "GenSigStartValue" SG_ 618 S4_SRR_RL_Obj_DistX_10 15;
BA_ "GenSigStartValue" SG_ 618 S4_SRR_RL_Obj_DistY_10 15;
BA_ "GenSigStartValue" SG_ 618 S4_SRR_RL_Obj_ValidFlag_10 1;
BA_ "InvalidHex" SG_ 618 S4_SRR_RL_Obj_ID_11 "0x7F";
BA_ "GenSigStartValue" SG_ 618 S4_SRR_RL_Obj_DistX_11 15;
BA_ "GenSigStartValue" SG_ 618 S4_SRR_RL_Obj_DistY_11 15;
BA_ "GenSigStartValue" SG_ 618 S4_SRR_RL_Obj_ValidFlag_11 1;
BA_ "VFrameFormat" BO_ 619 14;
BA_ "GenMsgSendType" BO_ 619 0;
BA_ "GenMsgCycleTime" BO_ 619 50;
BA_ "InvalidHex" SG_ 619 S4_SRR_RL_Obj_ID_12 "0x7F";
BA_ "GenSigStartValue" SG_ 619 S4_SRR_RL_Obj_DistX_12 15;
BA_ "GenSigStartValue" SG_ 619 S4_SRR_RL_Obj_DistY_12 15;
BA_ "GenSigStartValue" SG_ 619 S4_SRR_RL_Obj_ValidFlag_12 1;
BA_ "InvalidHex" SG_ 619 S4_SRR_RL_Obj_ID_13 "0x7F";
BA_ "GenSigStartValue" SG_ 619 S4_SRR_RL_Obj_DistX_13 15;
BA_ "GenSigStartValue" SG_ 619 S4_SRR_RL_Obj_DistY_13 15;
BA_ "GenSigStartValue" SG_ 619 S4_SRR_RL_Obj_ValidFlag_13 1;
BA_ "InvalidHex" SG_ 619 S4_SRR_RL_Obj_ID_14 "0x7F";
BA_ "GenSigStartValue" SG_ 619 S4_SRR_RL_Obj_DistX_14 15;
BA_ "GenSigStartValue" SG_ 619 S4_SRR_RL_Obj_DistY_14 15;
BA_ "GenSigStartValue" SG_ 619 S4_SRR_RL_Obj_ValidFlag_14 1;
BA_ "VFrameFormat" BO_ 620 14;
BA_ "GenMsgSendType" BO_ 620 0;
BA_ "GenMsgCycleTime" BO_ 620 50;
BA_ "InvalidHex" SG_ 620 S4_SRR_RL_Obj_ID_15 "0x7F";
BA_ "GenSigStartValue" SG_ 620 S4_SRR_RL_Obj_DistX_15 15;
BA_ "GenSigStartValue" SG_ 620 S4_SRR_RL_Obj_DistY_15 15;
BA_ "GenSigStartValue" SG_ 620 S4_SRR_RL_Obj_ValidFlag_15 1;
BA_ "InvalidHex" SG_ 620 S4_SRR_RL_Obj_ID_16 "0x7F";
BA_ "GenSigStartValue" SG_ 620 S4_SRR_RL_Obj_DistX_16 15;
BA_ "GenSigStartValue" SG_ 620 S4_SRR_RL_Obj_DistY_16 15;
BA_ "GenSigStartValue" SG_ 620 S4_SRR_RL_Obj_ValidFlag_16 1;
BA_ "InvalidHex" SG_ 620 S4_SRR_RL_Obj_ID_17 "0x7F";
BA_ "GenSigStartValue" SG_ 620 S4_SRR_RL_Obj_DistX_17 15;
BA_ "GenSigStartValue" SG_ 620 S4_SRR_RL_Obj_DistY_17 15;
BA_ "GenSigStartValue" SG_ 620 S4_SRR_RL_Obj_ValidFlag_17 1;
BA_ "VFrameFormat" BO_ 621 14;
BA_ "GenMsgSendType" BO_ 621 0;
BA_ "GenMsgCycleTime" BO_ 621 50;
BA_ "InvalidHex" SG_ 621 S4_SRR_RL_Obj_ID_18 "0x7F";
BA_ "GenSigStartValue" SG_ 621 S4_SRR_RL_Obj_DistX_18 15;
BA_ "GenSigStartValue" SG_ 621 S4_SRR_RL_Obj_DistY_18 15;
BA_ "GenSigStartValue" SG_ 621 S4_SRR_RL_Obj_ValidFlag_18 1;
BA_ "InvalidHex" SG_ 621 S4_SRR_RL_Obj_ID_19 "0x7F";
BA_ "GenSigStartValue" SG_ 621 S4_SRR_RL_Obj_DistX_19 15;
BA_ "GenSigStartValue" SG_ 621 S4_SRR_RL_Obj_DistY_19 15;
BA_ "GenSigStartValue" SG_ 621 S4_SRR_RL_Obj_ValidFlag_19 1;
BA_ "InvalidHex" SG_ 621 S4_SRR_RL_Obj_ID_20 "0x7F";
BA_ "GenSigStartValue" SG_ 621 S4_SRR_RL_Obj_DistX_20 15;
BA_ "GenSigStartValue" SG_ 621 S4_SRR_RL_Obj_DistY_20 15;
BA_ "GenSigStartValue" SG_ 621 S4_SRR_RL_Obj_ValidFlag_20 1;
BA_ "VFrameFormat" BO_ 622 14;
BA_ "GenMsgSendType" BO_ 622 0;
BA_ "GenMsgCycleTime" BO_ 622 50;
BA_ "InvalidHex" SG_ 622 S4_SRR_RL_Obj_ID_21 "0x7F";
BA_ "GenSigStartValue" SG_ 622 S4_SRR_RL_Obj_DistX_21 15;
BA_ "GenSigStartValue" SG_ 622 S4_SRR_RL_Obj_DistY_21 15;
BA_ "GenSigStartValue" SG_ 622 S4_SRR_RL_Obj_ValidFlag_21 1;
BA_ "InvalidHex" SG_ 622 S4_SRR_RL_Obj_ID_22 "0x7F";
BA_ "GenSigStartValue" SG_ 622 S4_SRR_RL_Obj_DistX_22 15;
BA_ "GenSigStartValue" SG_ 622 S4_SRR_RL_Obj_DistY_22 15;
BA_ "GenSigStartValue" SG_ 622 S4_SRR_RL_Obj_ValidFlag_22 1;
BA_ "InvalidHex" SG_ 622 S4_SRR_RL_Obj_ID_23 "0x7F";
BA_ "GenSigStartValue" SG_ 622 S4_SRR_RL_Obj_DistX_23 15;
BA_ "GenSigStartValue" SG_ 622 S4_SRR_RL_Obj_DistY_23 15;
BA_ "GenSigStartValue" SG_ 622 S4_SRR_RL_Obj_ValidFlag_23 1;
BA_ "VFrameFormat" BO_ 623 14;
BA_ "GenMsgSendType" BO_ 623 0;
BA_ "GenMsgCycleTime" BO_ 623 50;
BA_ "InvalidHex" SG_ 623 S4_SRR_RL_Obj_ID_24 "0x7F";
BA_ "GenSigStartValue" SG_ 623 S4_SRR_RL_Obj_DistX_24 15;
BA_ "GenSigStartValue" SG_ 623 S4_SRR_RL_Obj_DistY_24 15;
BA_ "GenSigStartValue" SG_ 623 S4_SRR_RL_Obj_ValidFlag_24 1;
BA_ "InvalidHex" SG_ 623 S4_SRR_RL_Obj_ID_25 "0x7F";
BA_ "GenSigStartValue" SG_ 623 S4_SRR_RL_Obj_DistX_25 15;
BA_ "GenSigStartValue" SG_ 623 S4_SRR_RL_Obj_DistY_25 15;
BA_ "GenSigStartValue" SG_ 623 S4_SRR_RL_Obj_ValidFlag_25 1;
BA_ "InvalidHex" SG_ 623 S4_SRR_RL_Obj_ID_26 "0x7F";
BA_ "GenSigStartValue" SG_ 623 S4_SRR_RL_Obj_DistX_26 15;
BA_ "GenSigStartValue" SG_ 623 S4_SRR_RL_Obj_DistY_26 15;
BA_ "GenSigStartValue" SG_ 623 S4_SRR_RL_Obj_ValidFlag_26 1;
BA_ "VFrameFormat" BO_ 624 14;
BA_ "GenMsgSendType" BO_ 624 0;
BA_ "GenMsgCycleTime" BO_ 624 50;
BA_ "InvalidHex" SG_ 624 S4_SRR_RL_Obj_ID_27 "0x7F";
BA_ "GenSigStartValue" SG_ 624 S4_SRR_RL_Obj_DistX_27 15;
BA_ "GenSigStartValue" SG_ 624 S4_SRR_RL_Obj_DistY_27 15;
BA_ "GenSigStartValue" SG_ 624 S4_SRR_RL_Obj_ValidFlag_27 1;
BA_ "InvalidHex" SG_ 624 S4_SRR_RL_Obj_ID_28 "0x7F";
BA_ "GenSigStartValue" SG_ 624 S4_SRR_RL_Obj_DistX_28 15;
BA_ "GenSigStartValue" SG_ 624 S4_SRR_RL_Obj_DistY_28 15;
BA_ "GenSigStartValue" SG_ 624 S4_SRR_RL_Obj_ValidFlag_28 1;
BA_ "InvalidHex" SG_ 624 S4_SRR_RL_Obj_ID_29 "0x7F";
BA_ "GenSigStartValue" SG_ 624 S4_SRR_RL_Obj_DistX_29 15;
BA_ "GenSigStartValue" SG_ 624 S4_SRR_RL_Obj_DistY_29 15;
BA_ "GenSigStartValue" SG_ 624 S4_SRR_RL_Obj_ValidFlag_29 1;
BA_ "VFrameFormat" BO_ 627 14;
BA_ "GenMsgSendType" BO_ 627 0;
BA_ "GenMsgCycleTime" BO_ 627 50;
BA_ "InvalidHex" SG_ 627 S4_SRR_RL_Obj_ID_30 "0x7F";
BA_ "GenSigStartValue" SG_ 627 S4_SRR_RL_Obj_DistX_30 15;
BA_ "GenSigStartValue" SG_ 627 S4_SRR_RL_Obj_DistY_30 15;
BA_ "GenSigStartValue" SG_ 627 S4_SRR_RL_Obj_ValidFlag_30 1;
BA_ "InvalidHex" SG_ 627 S4_SRR_RL_Obj_ID_31 "0x7F";
BA_ "GenSigStartValue" SG_ 627 S4_SRR_RL_Obj_DistX_31 15;
BA_ "GenSigStartValue" SG_ 627 S4_SRR_RL_Obj_DistY_31 15;
BA_ "GenSigStartValue" SG_ 627 S4_SRR_RL_Obj_ValidFlag_31 1;
BA_ "InvalidHex" SG_ 627 S4_SRR_RL_Obj_ID_32 "0x7F";
BA_ "GenSigStartValue" SG_ 627 S4_SRR_RL_Obj_DistX_32 15;
BA_ "GenSigStartValue" SG_ 627 S4_SRR_RL_Obj_DistY_32 15;
BA_ "GenSigStartValue" SG_ 627 S4_SRR_RL_Obj_ValidFlag_32 1;
BA_ "VFrameFormat" BO_ 629 14;
BA_ "GenMsgSendType" BO_ 629 0;
BA_ "GenMsgCycleTime" BO_ 629 50;
BA_ "InvalidHex" SG_ 629 S4_SRR_RL_Obj_ID_33 "0x7F";
BA_ "GenSigStartValue" SG_ 629 S4_SRR_RL_Obj_DistX_33 15;
BA_ "GenSigStartValue" SG_ 629 S4_SRR_RL_Obj_DistY_33 15;
BA_ "GenSigStartValue" SG_ 629 S4_SRR_RL_Obj_ValidFlag_33 1;
BA_ "InvalidHex" SG_ 629 S4_SRR_RL_Obj_ID_34 "0x7F";
BA_ "GenSigStartValue" SG_ 629 S4_SRR_RL_Obj_DistX_34 15;
BA_ "GenSigStartValue" SG_ 629 S4_SRR_RL_Obj_DistY_34 15;
BA_ "GenSigStartValue" SG_ 629 S4_SRR_RL_Obj_ValidFlag_34 1;
BA_ "InvalidHex" SG_ 629 S4_SRR_RL_Obj_ID_35 "0x7F";
BA_ "GenSigStartValue" SG_ 629 S4_SRR_RL_Obj_DistX_35 15;
BA_ "GenSigStartValue" SG_ 629 S4_SRR_RL_Obj_DistY_35 15;
BA_ "GenSigStartValue" SG_ 629 S4_SRR_RL_Obj_ValidFlag_35 1;
BA_ "VFrameFormat" BO_ 630 14;
BA_ "GenMsgSendType" BO_ 630 0;
BA_ "GenMsgCycleTime" BO_ 630 50;
BA_ "InvalidHex" SG_ 630 S4_SRR_RL_Obj_ID_36 "0x7F";
BA_ "GenSigStartValue" SG_ 630 S4_SRR_RL_Obj_DistX_36 15;
BA_ "GenSigStartValue" SG_ 630 S4_SRR_RL_Obj_DistY_36 15;
BA_ "GenSigStartValue" SG_ 630 S4_SRR_RL_Obj_ValidFlag_36 1;
BA_ "InvalidHex" SG_ 630 S4_SRR_RL_Obj_ID_37 "0x7F";
BA_ "GenSigStartValue" SG_ 630 S4_SRR_RL_Obj_DistX_37 15;
BA_ "GenSigStartValue" SG_ 630 S4_SRR_RL_Obj_DistY_37 15;
BA_ "GenSigStartValue" SG_ 630 S4_SRR_RL_Obj_ValidFlag_37 1;
BA_ "InvalidHex" SG_ 630 S4_SRR_RL_Obj_ID_38 "0x7F";
BA_ "GenSigStartValue" SG_ 630 S4_SRR_RL_Obj_DistX_38 15;
BA_ "GenSigStartValue" SG_ 630 S4_SRR_RL_Obj_DistY_38 15;
BA_ "GenSigStartValue" SG_ 630 S4_SRR_RL_Obj_ValidFlag_38 1;
BA_ "VFrameFormat" BO_ 631 14;
BA_ "GenMsgSendType" BO_ 631 0;
BA_ "GenMsgCycleTime" BO_ 631 50;
BA_ "InvalidHex" SG_ 631 S4_SRR_RL_Obj_ID_39 "0x7F";
BA_ "GenSigStartValue" SG_ 631 S4_SRR_RL_Obj_DistX_39 15;
BA_ "GenSigStartValue" SG_ 631 S4_SRR_RL_Obj_DistY_39 15;
BA_ "GenSigStartValue" SG_ 631 S4_SRR_RL_Obj_ValidFlag_39 1;
BA_ "VFrameFormat" BO_ 222 14;
BA_ "GenMsgSendType" BO_ 222 1;
BA_ "GenMsgCycleTimeFast" BO_ 222 10;
BA_ "GenSigSendType" SG_ 222 S4_SRR_RL_BSD_ID 3;
BA_ "GenSigStartValue" SG_ 222 S4_SRR_RL_BSD_DistX 15;
BA_ "GenSigSendType" SG_ 222 S4_SRR_RL_BSD_DistX 3;
BA_ "GenSigSendType" SG_ 222 S4_SRR_RL_BSD_RelVelX 3;
BA_ "GenSigStartValue" SG_ 222 S4_SRR_RL_BSD_DistY 15;
BA_ "GenSigSendType" SG_ 222 S4_SRR_RL_BSD_DistY 3;
BA_ "GenSigSendType" SG_ 222 S4_SRR_RL_BSD_RelVelY 3;
BA_ "GenSigSendType" SG_ 222 S4_SRR_RL_BSD_BlockCounter 3;
BA_ "VFrameFormat" BO_ 223 14;
BA_ "GenMsgSendType" BO_ 223 1;
BA_ "GenMsgCycleTimeFast" BO_ 223 10;
BA_ "GenSigSendType" SG_ 223 S4_SRR_RL_DOW_ID 3;
BA_ "GenSigStartValue" SG_ 223 S4_SRR_RL_DOW_DistX 15;
BA_ "GenSigSendType" SG_ 223 S4_SRR_RL_DOW_DistX 3;
BA_ "GenSigSendType" SG_ 223 S4_SRR_RL_DOW_RelVelX 3;
BA_ "GenSigStartValue" SG_ 223 S4_SRR_RL_DOW_DistY 15;
BA_ "GenSigSendType" SG_ 223 S4_SRR_RL_DOW_DistY 3;
BA_ "GenSigSendType" SG_ 223 S4_SRR_RL_DOW_RelVelY 3;
BA_ "GenSigSendType" SG_ 223 S4_SRR_RL_DOW_BlockCounter 3;
BA_ "VFrameFormat" BO_ 634 14;
BA_ "GenMsgSendType" BO_ 634 0;
BA_ "GenMsgCycleTime" BO_ 634 50;
BA_ "GenSigStartValue" SG_ 634 S4_SRR_RL_EolHoriAng 1000;
BA_ "GenSigStartValue" SG_ 634 S4_SRR_RL_OnlineHoriAng 1000;
BA_ "GenSigStartValue" SG_ 634 S4_SRR_RL_ICTemp 130;
BA_ "GenSigStartValue" SG_ 634 S4_SRR_RL_EolVerAng 500;
BA_ "GenSigStartValue" SG_ 634 S4_SRR_RL_OnlineVerAng 500;
BA_ "VFrameFormat" BO_ 950 14;
BA_ "GenMsgSendType" BO_ 950 0;
BA_ "GenMsgCycleTime" BO_ 950 500;
BA_ "VFrameFormat" BO_ 787 14;
BA_ "GenMsgSendType" BO_ 787 0;
BA_ "GenMsgCycleTime" BO_ 787 100;
BA_ "AliveTimeout" BO_ 787 1000;
BA_ "GenSigStartValue" SG_ 787 S4_SRR_eSensorID 3;
BA_ "VFrameFormat" BO_ 939 14;
BA_ "GenMsgILSupport" BO_ 939 0;
BA_ "VFrameFormat" BO_ 1842 14;
BA_ "GenMsgSendType" BO_ 1842 1;
BA_ "GenMsgCycleTimeFast" BO_ 1842 10;
BA_ "DiagRequest" BO_ 1842 1;
BA_ "DiagDCM" BO_ 1842 0;
BA_ "GenSigSendType" SG_ 1842 S4_TETSER_SRR_RL_DiagReq_Sig 3;
BA_ "VFrameFormat" BO_ 1970 14;
BA_ "GenMsgSendType" BO_ 1970 1;
BA_ "GenMsgCycleTimeFast" BO_ 1970 10;
BA_ "DiagResponse" BO_ 1970 1;
BA_ "DiagDCM" BO_ 1970 0;
BA_ "GenSigSendType" SG_ 1970 S4_SRR_RL_TETSER_DiagResp_Sig 3;
BA_ "VFrameFormat" BO_ 2015 14;
BA_ "GenMsgSendType" BO_ 2015 1;
BA_ "GenMsgCycleTimeFast" BO_ 2015 10;
BA_ "DiagRequest" BO_ 2015 1;
BA_ "DiagDCM" BO_ 2015 0;
BA_ "GenSigSendType" SG_ 2015 S4_TETSER_FunctionDiagReq_Sig 3;
BA_ "VFrameFormat" BO_ 425 14;
BA_ "GenMsgSendType" BO_ 425 0;
BA_ "GenMsgCycleTime" BO_ 425 20;
BA_ "AliveTimeout" BO_ 425 200;
BA_ "GenSigStartValue" SG_ 425 S4_IPB_VehLongAccelOffsetValue 625;
BA_ "InvalidHex" SG_ 425 S4_IPB_VehLongAccelOffsetValue "0xFFF";
BA_ "GenSigStartValue" SG_ 425 S4_IPB_VehLateralAccelOffsetValue 625;
BA_ "InvalidHex" SG_ 425 S4_IPB_VehLateralAccelOffsetValue "0xFFF";
BA_ "GenSigStartValue" SG_ 425 S4_IPB_YAWRateOffsetValue 1488;
BA_ "InvalidHex" SG_ 425 S4_IPB_YAWRateOffsetValue "0xFFF";
BA_ "VFrameFormat" BO_ 279 14;
BA_ "GenMsgSendType" BO_ 279 0;
BA_ "GenMsgCycleTime" BO_ 279 10;
BA_ "AliveTimeout" BO_ 279 100;
BA_ "GenSigStartValue" SG_ 279 S4_LDCU_ExterTemp 120;
BA_ "VFrameFormat" BO_ 870 14;
BA_ "GenMsgSendType" BO_ 870 0;
BA_ "GenMsgCycleTime" BO_ 870 200;
BA_ "AliveTimeout" BO_ 870 2000;
BA_ "VFrameFormat" BO_ 548 14;
BA_ "GenMsgSendType" BO_ 548 0;
BA_ "GenMsgCycleTime" BO_ 548 40;
BA_ "AliveTimeout" BO_ 548 400;
BA_ "VFrameFormat" BO_ 549 14;
BA_ "GenMsgSendType" BO_ 549 0;
BA_ "GenMsgCycleTime" BO_ 549 40;
BA_ "AliveTimeout" BO_ 549 400;
BA_ "VFrameFormat" BO_ 551 14;
BA_ "GenMsgSendType" BO_ 551 0;
BA_ "GenMsgCycleTime" BO_ 551 40;
BA_ "AliveTimeout" BO_ 551 400;
BA_ "VFrameFormat" BO_ 933 14;
BA_ "GenMsgSendType" BO_ 933 0;
BA_ "GenMsgCycleTime" BO_ 933 1000;
BA_ "AliveTimeout" BO_ 933 10000;
BA_ "VFrameFormat" BO_ 539 14;
BA_ "GenMsgSendType" BO_ 539 0;
BA_ "GenMsgCycleTime" BO_ 539 50;
BA_ "AliveTimeout" BO_ 539 500;
BA_ "VFrameFormat" BO_ 399 14;
BA_ "GenMsgSendType" BO_ 399 0;
BA_ "GenMsgCycleTime" BO_ 399 20;
BA_ "AliveTimeout" BO_ 399 200;
BA_ "GenSigStartValue" SG_ 399 S4_AS_DrvModSts 4;
BA_ "GenSigStartValue" SG_ 399 S4_AS_MaintainMode 4;
BA_ "VFrameFormat" BO_ 658 14;
BA_ "GenMsgSendType" BO_ 658 0;
BA_ "GenMsgCycleTime" BO_ 658 20;
BA_ "AliveTimeout" BO_ 658 200;
BA_ "GenSigStartValue" SG_ 658 S4_AS_wheelPosFLFilt_mm 1000;
BA_ "GenSigStartValue" SG_ 658 S4_AS_wheelPosFRFilt_mm 1000;
BA_ "GenSigStartValue" SG_ 658 S4_AS_wheelPosRLFilt_mm 1000;
BA_ "GenSigStartValue" SG_ 658 S4_AS_wheelPosRRFilt_mm 1000;
BA_ "GenSigStartValue" SG_ 658 S4_AS_PVlvBlk_kPa 3000;
BA_ "GenSigStartValue" SG_ 658 S4_AS_bodyHeaveAccRaw_g 2;
BA_ "VFrameFormat" BO_ 281 14;
BA_ "GenMsgSendType" BO_ 281 0;
BA_ "GenMsgCycleTime" BO_ 281 10;
BA_ "AliveTimeout" BO_ 281 100;
BA_ "GenSigStartValue" SG_ 281 S4_RWS_Wheelangle 32768;
BA_ "VFrameFormat" BO_ 294 14;
BA_ "GenMsgSendType" BO_ 294 0;
BA_ "GenMsgCycleTime" BO_ 294 5;
BA_ "AliveTimeout" BO_ 294 50;
BA_ "InvalidHex" SG_ 294 S4_IPB_FLWheelSpd_E2E "0x7FFF";
BA_ "InvalidHex" SG_ 294 S4_IPB_FRWheelSpd_E2E "0x7FFF";
BA_ "InvalidHex" SG_ 294 S4_IPB_VehSpd_E2E "0x7FFF";
BA_ "InvalidHex" SG_ 294 S4_IPB_RLWheelSpd_E2E "0x7FFF";
BA_ "InvalidHex" SG_ 294 S4_IPB_RRWheelSpd_E2E "0x7FFF";
BA_ "VFrameFormat" BO_ 422 14;
BA_ "GenMsgSendType" BO_ 422 0;
BA_ "GenMsgCycleTime" BO_ 422 20;
BA_ "AliveTimeout" BO_ 422 200;
BA_ "GenSigStartValue" SG_ 422 S4_IPB_ABSFault_E2E 1;
BA_ "GenSigStartValue" SG_ 422 S4_IPB_CDDFaultSt_E2E 1;
BA_ "GenSigStartValue" SG_ 422 S4_IPB_VehLongAccel_E2E 625;
BA_ "InvalidHex" SG_ 422 S4_IPB_VehLongAccel_E2E "0xFFF";
BA_ "GenSigStartValue" SG_ 422 S4_IPB_VehLateralAccel_E2E 625;
BA_ "InvalidHex" SG_ 422 S4_IPB_VehLateralAccel_E2E "0xFFF";
BA_ "GenSigStartValue" SG_ 422 S4_IPB_YAWRate_E2E 1488;
BA_ "InvalidHex" SG_ 422 S4_IPB_YAWRate_E2E "0xFFF";
BA_ "VFrameFormat" BO_ 275 14;
BA_ "GenMsgSendType" BO_ 275 0;
BA_ "GenMsgCycleTime" BO_ 275 10;
BA_ "AliveTimeout" BO_ 275 100;
BA_ "GenSigStartValue" SG_ 275 S4_EPS_SteeringAngle_E2E 7800;
BA_ "InvalidHex" SG_ 275 S4_EPS_SteeringAngle_E2E "0xFFFF";
BA_ "InvalidHex" SG_ 275 S4_EPS_PowerVoltage_E2E "0xFF";
BA_ "GenSigStartValue" SG_ 275 S4_EPS_SteeringAngleSpd_E2E 1016;
BA_ "InvalidHex" SG_ 275 S4_EPS_SteeringAngleSpd_E2E "0x7FFF";
BA_ "VFrameFormat" BO_ 423 14;
BA_ "GenMsgSendType" BO_ 423 0;
BA_ "GenMsgCycleTime" BO_ 423 20;
BA_ "AliveTimeout" BO_ 423 200;
BA_ "GenSigStartValue" SG_ 423 S4_IPB_ABSFault 1;
BA_ "GenSigStartValue" SG_ 423 S4_IPB_ESPPATA 2;
BA_ "GenSigStartValue" SG_ 423 S4_IPB_ESPFault 1;
BA_ "VFrameFormat" BO_ 638 14;
BA_ "GenMsgSendType" BO_ 638 0;
BA_ "GenMsgCycleTime" BO_ 638 40;
BA_ "AliveTimeout" BO_ 638 400;
VAL_ 618 S4_SRR_RL_Obj_ValidFlag_9 0 "valid" 1 "invalid" ;
VAL_ 618 S4_SRR_RL_Obj_UpdateFlag_9 0 "Measured" 1 "New" ;
VAL_ 618 S4_SRR_RL_Obj_Type_9 0 "OBJ_CLASS_POINT" 1 "OBJ_CLASS_CAR" 2 "OBJ_CLASS_TRUCK" 3 "OBJ_CLASS_PEDESTRIAN" 4 "OBJ_CLASS_MOTORCYCLE" 5 "OBJ_CLASS_BICYCLE" 6 "OBJ_CLASS_WIDE" 7 "OBJ_CLASS_UNCLASSIFIED" 8 "OBJ_CLASS_OTHER_VEHICLE" 9 "OBJ_CLASS_MAX_DIFF_TYPES" ;
VAL_ 618 S4_SRR_RL_Obj_EDynProp_9 0 "MOVING_DYNAMICPROPERTY" 1 "STATIONARY_DYNAMICPROPERTY" 2 "ONCOMING_DYNAMICPROPERTY" 3 "CROSSING_LEFT_TO_RIGHT_DYNAMICPR" 4 "CROSSING_RIGHT_TO_LEFT_DYNAMICPR" 5 "UNKNOWN_DYNAMICPROPERTY" 6 "STOPPED_DYNAMICPROPERTY" 7 "RESERVED" ;
VAL_ 618 S4_SRR_RL_Obj_UiLifeCycles_9 126 "MAX_CYCLE_OBJ_LIFECYCLE" 127 "INVALID_OBJ_LIFECYCLE" ;
VAL_ 618 S4_SRR_RL_Obj_ValidFlag_10 0 "valid" 1 "invalid" ;
VAL_ 618 S4_SRR_RL_Obj_UpdateFlag_10 0 "Measured" 1 "New" ;
VAL_ 618 S4_SRR_RL_Obj_Type_10 0 "OBJ_CLASS_POINT" 1 "OBJ_CLASS_CAR" 2 "OBJ_CLASS_TRUCK" 3 "OBJ_CLASS_PEDESTRIAN" 4 "OBJ_CLASS_MOTORCYCLE" 5 "OBJ_CLASS_BICYCLE" 6 "OBJ_CLASS_WIDE" 7 "OBJ_CLASS_UNCLASSIFIED" 8 "OBJ_CLASS_OTHER_VEHICLE" 9 "OBJ_CLASS_MAX_DIFF_TYPES" ;
VAL_ 618 S4_SRR_RL_Obj_EDynProp_10 0 "MOVING_DYNAMICPROPERTY" 1 "STATIONARY_DYNAMICPROPERTY" 2 "ONCOMING_DYNAMICPROPERTY" 3 "CROSSING_LEFT_TO_RIGHT_DYNAMICPR" 4 "CROSSING_RIGHT_TO_LEFT_DYNAMICPR" 5 "UNKNOWN_DYNAMICPROPERTY" 6 "STOPPED_DYNAMICPROPERTY" 7 "RESERVED" ;
VAL_ 618 S4_SRR_RL_Obj_UiLifeCycles_10 126 "MAX_CYCLE_OBJ_LIFECYCLE" 127 "INVALID_OBJ_LIFECYCLE" ;
VAL_ 618 S4_SRR_RL_Obj_ValidFlag_11 0 "valid" 1 "invalid" ;
VAL_ 618 S4_SRR_RL_Obj_UpdateFlag_11 0 "Measured" 1 "New" ;
VAL_ 618 S4_SRR_RL_Obj_Type_11 0 "OBJ_CLASS_POINT" 1 "OBJ_CLASS_CAR" 2 "OBJ_CLASS_TRUCK" 3 "OBJ_CLASS_PEDESTRIAN" 4 "OBJ_CLASS_MOTORCYCLE" 5 "OBJ_CLASS_BICYCLE" 6 "OBJ_CLASS_WIDE" 7 "OBJ_CLASS_UNCLASSIFIED" 8 "OBJ_CLASS_OTHER_VEHICLE" 9 "OBJ_CLASS_MAX_DIFF_TYPES" ;
VAL_ 618 S4_SRR_RL_Obj_EDynProp_11 0 "MOVING_DYNAMICPROPERTY" 1 "STATIONARY_DYNAMICPROPERTY" 2 "ONCOMING_DYNAMICPROPERTY" 3 "CROSSING_LEFT_TO_RIGHT_DYNAMICPR" 4 "CROSSING_RIGHT_TO_LEFT_DYNAMICPR" 5 "UNKNOWN_DYNAMICPROPERTY" 6 "STOPPED_DYNAMICPROPERTY" 7 "RESERVED" ;
VAL_ 618 S4_SRR_RL_Obj_UiLifeCycles_11 126 "MAX_CYCLE_OBJ_LIFECYCLE" 127 "INVALID_OBJ_LIFECYCLE" ;
VAL_ 619 S4_SRR_RL_Obj_ValidFlag_12 0 "valid" 1 "invalid" ;
VAL_ 619 S4_SRR_RL_Obj_UpdateFlag_12 0 "Measured" 1 "New" ;
VAL_ 619 S4_SRR_RL_Obj_Type_12 0 "OBJ_CLASS_POINT" 1 "OBJ_CLASS_CAR" 2 "OBJ_CLASS_TRUCK" 3 "OBJ_CLASS_PEDESTRIAN" 4 "OBJ_CLASS_MOTORCYCLE" 5 "OBJ_CLASS_BICYCLE" 6 "OBJ_CLASS_WIDE" 7 "OBJ_CLASS_UNCLASSIFIED" 8 "OBJ_CLASS_OTHER_VEHICLE" 9 "OBJ_CLASS_MAX_DIFF_TYPES" ;
VAL_ 619 S4_SRR_RL_Obj_EDynProp_12 0 "MOVING_DYNAMICPROPERTY" 1 "STATIONARY_DYNAMICPROPERTY" 2 "ONCOMING_DYNAMICPROPERTY" 3 "CROSSING_LEFT_TO_RIGHT_DYNAMICPR" 4 "CROSSING_RIGHT_TO_LEFT_DYNAMICPR" 5 "UNKNOWN_DYNAMICPROPERTY" 6 "STOPPED_DYNAMICPROPERTY" 7 "RESERVED" ;
VAL_ 619 S4_SRR_RL_Obj_UiLifeCycles_12 126 "MAX_CYCLE_OBJ_LIFECYCLE" 127 "INVALID_OBJ_LIFECYCLE" ;
VAL_ 619 S4_SRR_RL_Obj_ValidFlag_13 0 "valid" 1 "invalid" ;
VAL_ 619 S4_SRR_RL_Obj_UpdateFlag_13 0 "Measured" 1 "New" ;
VAL_ 619 S4_SRR_RL_Obj_Type_13 0 "OBJ_CLASS_POINT" 1 "OBJ_CLASS_CAR" 2 "OBJ_CLASS_TRUCK" 3 "OBJ_CLASS_PEDESTRIAN" 4 "OBJ_CLASS_MOTORCYCLE" 5 "OBJ_CLASS_BICYCLE" 6 "OBJ_CLASS_WIDE" 7 "OBJ_CLASS_UNCLASSIFIED" 8 "OBJ_CLASS_OTHER_VEHICLE" 9 "OBJ_CLASS_MAX_DIFF_TYPES" ;
VAL_ 619 S4_SRR_RL_Obj_EDynProp_13 0 "MOVING_DYNAMICPROPERTY" 1 "STATIONARY_DYNAMICPROPERTY" 2 "ONCOMING_DYNAMICPROPERTY" 3 "CROSSING_LEFT_TO_RIGHT_DYNAMICPR" 4 "CROSSING_RIGHT_TO_LEFT_DYNAMICPR" 5 "UNKNOWN_DYNAMICPROPERTY" 6 "STOPPED_DYNAMICPROPERTY" 7 "RESERVED" ;
VAL_ 619 S4_SRR_RL_Obj_UiLifeCycles_13 126 "MAX_CYCLE_OBJ_LIFECYCLE" 127 "INVALID_OBJ_LIFECYCLE" ;
VAL_ 619 S4_SRR_RL_Obj_ValidFlag_14 0 "valid" 1 "invalid" ;
VAL_ 619 S4_SRR_RL_Obj_UpdateFlag_14 0 "Measured" 1 "New" ;
VAL_ 619 S4_SRR_RL_Obj_Type_14 0 "OBJ_CLASS_POINT" 1 "OBJ_CLASS_CAR" 2 "OBJ_CLASS_TRUCK" 3 "OBJ_CLASS_PEDESTRIAN" 4 "OBJ_CLASS_MOTORCYCLE" 5 "OBJ_CLASS_BICYCLE" 6 "OBJ_CLASS_WIDE" 7 "OBJ_CLASS_UNCLASSIFIED" 8 "OBJ_CLASS_OTHER_VEHICLE" 9 "OBJ_CLASS_MAX_DIFF_TYPES" ;
VAL_ 619 S4_SRR_RL_Obj_EDynProp_14 0 "MOVING_DYNAMICPROPERTY" 1 "STATIONARY_DYNAMICPROPERTY" 2 "ONCOMING_DYNAMICPROPERTY" 3 "CROSSING_LEFT_TO_RIGHT_DYNAMICPR" 4 "CROSSING_RIGHT_TO_LEFT_DYNAMICPR" 5 "UNKNOWN_DYNAMICPROPERTY" 6 "STOPPED_DYNAMICPROPERTY" 7 "RESERVED" ;
VAL_ 619 S4_SRR_RL_Obj_UiLifeCycles_14 126 "MAX_CYCLE_OBJ_LIFECYCLE" 127 "INVALID_OBJ_LIFECYCLE" ;
VAL_ 620 S4_SRR_RL_Obj_ValidFlag_15 0 "valid" 1 "invalid" ;
VAL_ 620 S4_SRR_RL_Obj_UpdateFlag_15 0 "Measured" 1 "New" ;
VAL_ 620 S4_SRR_RL_Obj_Type_15 0 "OBJ_CLASS_POINT" 1 "OBJ_CLASS_CAR" 2 "OBJ_CLASS_TRUCK" 3 "OBJ_CLASS_PEDESTRIAN" 4 "OBJ_CLASS_MOTORCYCLE" 5 "OBJ_CLASS_BICYCLE" 6 "OBJ_CLASS_WIDE" 7 "OBJ_CLASS_UNCLASSIFIED" 8 "OBJ_CLASS_OTHER_VEHICLE" 9 "OBJ_CLASS_MAX_DIFF_TYPES" ;
VAL_ 620 S4_SRR_RL_Obj_EDynProp_15 0 "MOVING_DYNAMICPROPERTY" 1 "STATIONARY_DYNAMICPROPERTY" 2 "ONCOMING_DYNAMICPROPERTY" 3 "CROSSING_LEFT_TO_RIGHT_DYNAMICPR" 4 "CROSSING_RIGHT_TO_LEFT_DYNAMICPR" 5 "UNKNOWN_DYNAMICPROPERTY" 6 "STOPPED_DYNAMICPROPERTY" 7 "RESERVED" ;
VAL_ 620 S4_SRR_RL_Obj_UiLifeCycles_15 126 "MAX_CYCLE_OBJ_LIFECYCLE" 127 "INVALID_OBJ_LIFECYCLE" ;
VAL_ 620 S4_SRR_RL_Obj_ValidFlag_16 0 "valid" 1 "invalid" ;
VAL_ 620 S4_SRR_RL_Obj_UpdateFlag_16 0 "Measured" 1 "New" ;
VAL_ 620 S4_SRR_RL_Obj_Type_16 0 "OBJ_CLASS_POINT" 1 "OBJ_CLASS_CAR" 2 "OBJ_CLASS_TRUCK" 3 "OBJ_CLASS_PEDESTRIAN" 4 "OBJ_CLASS_MOTORCYCLE" 5 "OBJ_CLASS_BICYCLE" 6 "OBJ_CLASS_WIDE" 7 "OBJ_CLASS_UNCLASSIFIED" 8 "OBJ_CLASS_OTHER_VEHICLE" 9 "OBJ_CLASS_MAX_DIFF_TYPES" ;
VAL_ 620 S4_SRR_RL_Obj_EDynProp_16 0 "MOVING_DYNAMICPROPERTY" 1 "STATIONARY_DYNAMICPROPERTY" 2 "ONCOMING_DYNAMICPROPERTY" 3 "CROSSING_LEFT_TO_RIGHT_DYNAMICPR" 4 "CROSSING_RIGHT_TO_LEFT_DYNAMICPR" 5 "UNKNOWN_DYNAMICPROPERTY" 6 "STOPPED_DYNAMICPROPERTY" 7 "RESERVED" ;
VAL_ 620 S4_SRR_RL_Obj_UiLifeCycles_16 126 "MAX_CYCLE_OBJ_LIFECYCLE" 127 "INVALID_OBJ_LIFECYCLE" ;
VAL_ 620 S4_SRR_RL_Obj_ValidFlag_17 0 "valid" 1 "invalid" ;
VAL_ 620 S4_SRR_RL_Obj_UpdateFlag_17 0 "Measured" 1 "New" ;
VAL_ 620 S4_SRR_RL_Obj_Type_17 0 "OBJ_CLASS_POINT" 1 "OBJ_CLASS_CAR" 2 "OBJ_CLASS_TRUCK" 3 "OBJ_CLASS_PEDESTRIAN" 4 "OBJ_CLASS_MOTORCYCLE" 5 "OBJ_CLASS_BICYCLE" 6 "OBJ_CLASS_WIDE" 7 "OBJ_CLASS_UNCLASSIFIED" 8 "OBJ_CLASS_OTHER_VEHICLE" 9 "OBJ_CLASS_MAX_DIFF_TYPES" ;
VAL_ 620 S4_SRR_RL_Obj_EDynProp_17 0 "MOVING_DYNAMICPROPERTY" 1 "STATIONARY_DYNAMICPROPERTY" 2 "ONCOMING_DYNAMICPROPERTY" 3 "CROSSING_LEFT_TO_RIGHT_DYNAMICPR" 4 "CROSSING_RIGHT_TO_LEFT_DYNAMICPR" 5 "UNKNOWN_DYNAMICPROPERTY" 6 "STOPPED_DYNAMICPROPERTY" 7 "RESERVED" ;
VAL_ 620 S4_SRR_RL_Obj_UiLifeCycles_17 126 "MAX_CYCLE_OBJ_LIFECYCLE" 127 "INVALID_OBJ_LIFECYCLE" ;
VAL_ 621 S4_SRR_RL_Obj_ValidFlag_18 0 "valid" 1 "invalid" ;
VAL_ 621 S4_SRR_RL_Obj_UpdateFlag_18 0 "Measured" 1 "New" ;
VAL_ 621 S4_SRR_RL_Obj_Type_18 0 "OBJ_CLASS_POINT" 1 "OBJ_CLASS_CAR" 2 "OBJ_CLASS_TRUCK" 3 "OBJ_CLASS_PEDESTRIAN" 4 "OBJ_CLASS_MOTORCYCLE" 5 "OBJ_CLASS_BICYCLE" 6 "OBJ_CLASS_WIDE" 7 "OBJ_CLASS_UNCLASSIFIED" 8 "OBJ_CLASS_OTHER_VEHICLE" 9 "OBJ_CLASS_MAX_DIFF_TYPES" ;
VAL_ 621 S4_SRR_RL_Obj_EDynProp_18 0 "MOVING_DYNAMICPROPERTY" 1 "STATIONARY_DYNAMICPROPERTY" 2 "ONCOMING_DYNAMICPROPERTY" 3 "CROSSING_LEFT_TO_RIGHT_DYNAMICPR" 4 "CROSSING_RIGHT_TO_LEFT_DYNAMICPR" 5 "UNKNOWN_DYNAMICPROPERTY" 6 "STOPPED_DYNAMICPROPERTY" 7 "RESERVED" ;
VAL_ 621 S4_SRR_RL_Obj_UiLifeCycles_18 126 "MAX_CYCLE_OBJ_LIFECYCLE" 127 "INVALID_OBJ_LIFECYCLE" ;
VAL_ 621 S4_SRR_RL_Obj_ValidFlag_19 0 "valid" 1 "invalid" ;
VAL_ 621 S4_SRR_RL_Obj_UpdateFlag_19 0 "Measured" 1 "New" ;
VAL_ 621 S4_SRR_RL_Obj_Type_19 0 "OBJ_CLASS_POINT" 1 "OBJ_CLASS_CAR" 2 "OBJ_CLASS_TRUCK" 3 "OBJ_CLASS_PEDESTRIAN" 4 "OBJ_CLASS_MOTORCYCLE" 5 "OBJ_CLASS_BICYCLE" 6 "OBJ_CLASS_WIDE" 7 "OBJ_CLASS_UNCLASSIFIED" 8 "OBJ_CLASS_OTHER_VEHICLE" 9 "OBJ_CLASS_MAX_DIFF_TYPES" ;
VAL_ 621 S4_SRR_RL_Obj_EDynProp_19 0 "MOVING_DYNAMICPROPERTY" 1 "STATIONARY_DYNAMICPROPERTY" 2 "ONCOMING_DYNAMICPROPERTY" 3 "CROSSING_LEFT_TO_RIGHT_DYNAMICPR" 4 "CROSSING_RIGHT_TO_LEFT_DYNAMICPR" 5 "UNKNOWN_DYNAMICPROPERTY" 6 "STOPPED_DYNAMICPROPERTY" 7 "RESERVED" ;
VAL_ 621 S4_SRR_RL_Obj_UiLifeCycles_19 126 "MAX_CYCLE_OBJ_LIFECYCLE" 127 "INVALID_OBJ_LIFECYCLE" ;
VAL_ 621 S4_SRR_RL_Obj_ValidFlag_20 0 "valid" 1 "invalid" ;
VAL_ 621 S4_SRR_RL_Obj_UpdateFlag_20 0 "Measured" 1 "New" ;
VAL_ 621 S4_SRR_RL_Obj_Type_20 0 "OBJ_CLASS_POINT" 1 "OBJ_CLASS_CAR" 2 "OBJ_CLASS_TRUCK" 3 "OBJ_CLASS_PEDESTRIAN" 4 "OBJ_CLASS_MOTORCYCLE" 5 "OBJ_CLASS_BICYCLE" 6 "OBJ_CLASS_WIDE" 7 "OBJ_CLASS_UNCLASSIFIED" 8 "OBJ_CLASS_OTHER_VEHICLE" 9 "OBJ_CLASS_MAX_DIFF_TYPES" ;
VAL_ 621 S4_SRR_RL_Obj_EDynProp_20 0 "MOVING_DYNAMICPROPERTY" 1 "STATIONARY_DYNAMICPROPERTY" 2 "ONCOMING_DYNAMICPROPERTY" 3 "CROSSING_LEFT_TO_RIGHT_DYNAMICPR" 4 "CROSSING_RIGHT_TO_LEFT_DYNAMICPR" 5 "UNKNOWN_DYNAMICPROPERTY" 6 "STOPPED_DYNAMICPROPERTY" 7 "RESERVED" ;
VAL_ 621 S4_SRR_RL_Obj_UiLifeCycles_20 126 "MAX_CYCLE_OBJ_LIFECYCLE" 127 "INVALID_OBJ_LIFECYCLE" ;
VAL_ 622 S4_SRR_RL_Obj_ValidFlag_21 0 "valid" 1 "invalid" ;
VAL_ 622 S4_SRR_RL_Obj_UpdateFlag_21 0 "Measured" 1 "New" ;
VAL_ 622 S4_SRR_RL_Obj_Type_21 0 "OBJ_CLASS_POINT" 1 "OBJ_CLASS_CAR" 2 "OBJ_CLASS_TRUCK" 3 "OBJ_CLASS_PEDESTRIAN" 4 "OBJ_CLASS_MOTORCYCLE" 5 "OBJ_CLASS_BICYCLE" 6 "OBJ_CLASS_WIDE" 7 "OBJ_CLASS_UNCLASSIFIED" 8 "OBJ_CLASS_OTHER_VEHICLE" 9 "OBJ_CLASS_MAX_DIFF_TYPES" ;
VAL_ 622 S4_SRR_RL_Obj_EDynProp_21 0 "MOVING_DYNAMICPROPERTY" 1 "STATIONARY_DYNAMICPROPERTY" 2 "ONCOMING_DYNAMICPROPERTY" 3 "CROSSING_LEFT_TO_RIGHT_DYNAMICPR" 4 "CROSSING_RIGHT_TO_LEFT_DYNAMICPR" 5 "UNKNOWN_DYNAMICPROPERTY" 6 "STOPPED_DYNAMICPROPERTY" 7 "RESERVED" ;
VAL_ 622 S4_SRR_RL_Obj_UiLifeCycles_21 126 "MAX_CYCLE_OBJ_LIFECYCLE" 127 "INVALID_OBJ_LIFECYCLE" ;
VAL_ 622 S4_SRR_RL_Obj_ValidFlag_22 0 "valid" 1 "invalid" ;
VAL_ 622 S4_SRR_RL_Obj_UpdateFlag_22 0 "Measured" 1 "New" ;
VAL_ 622 S4_SRR_RL_Obj_Type_22 0 "OBJ_CLASS_POINT" 1 "OBJ_CLASS_CAR" 2 "OBJ_CLASS_TRUCK" 3 "OBJ_CLASS_PEDESTRIAN" 4 "OBJ_CLASS_MOTORCYCLE" 5 "OBJ_CLASS_BICYCLE" 6 "OBJ_CLASS_WIDE" 7 "OBJ_CLASS_UNCLASSIFIED" 8 "OBJ_CLASS_OTHER_VEHICLE" 9 "OBJ_CLASS_MAX_DIFF_TYPES" ;
VAL_ 622 S4_SRR_RL_Obj_EDynProp_22 0 "MOVING_DYNAMICPROPERTY" 1 "STATIONARY_DYNAMICPROPERTY" 2 "ONCOMING_DYNAMICPROPERTY" 3 "CROSSING_LEFT_TO_RIGHT_DYNAMICPR" 4 "CROSSING_RIGHT_TO_LEFT_DYNAMICPR" 5 "UNKNOWN_DYNAMICPROPERTY" 6 "STOPPED_DYNAMICPROPERTY" 7 "RESERVED" ;
VAL_ 622 S4_SRR_RL_Obj_UiLifeCycles_22 126 "MAX_CYCLE_OBJ_LIFECYCLE" 127 "INVALID_OBJ_LIFECYCLE" ;
VAL_ 622 S4_SRR_RL_Obj_ValidFlag_23 0 "valid" 1 "invalid" ;
VAL_ 622 S4_SRR_RL_Obj_UpdateFlag_23 0 "Measured" 1 "New" ;
VAL_ 622 S4_SRR_RL_Obj_Type_23 0 "OBJ_CLASS_POINT" 1 "OBJ_CLASS_CAR" 2 "OBJ_CLASS_TRUCK" 3 "OBJ_CLASS_PEDESTRIAN" 4 "OBJ_CLASS_MOTORCYCLE" 5 "OBJ_CLASS_BICYCLE" 6 "OBJ_CLASS_WIDE" 7 "OBJ_CLASS_UNCLASSIFIED" 8 "OBJ_CLASS_OTHER_VEHICLE" 9 "OBJ_CLASS_MAX_DIFF_TYPES" ;
VAL_ 622 S4_SRR_RL_Obj_EDynProp_23 0 "MOVING_DYNAMICPROPERTY" 1 "STATIONARY_DYNAMICPROPERTY" 2 "ONCOMING_DYNAMICPROPERTY" 3 "CROSSING_LEFT_TO_RIGHT_DYNAMICPR" 4 "CROSSING_RIGHT_TO_LEFT_DYNAMICPR" 5 "UNKNOWN_DYNAMICPROPERTY" 6 "STOPPED_DYNAMICPROPERTY" 7 "RESERVED" ;
VAL_ 622 S4_SRR_RL_Obj_UiLifeCycles_23 126 "MAX_CYCLE_OBJ_LIFECYCLE" 127 "INVALID_OBJ_LIFECYCLE" ;
VAL_ 623 S4_SRR_RL_Obj_ValidFlag_24 0 "valid" 1 "invalid" ;
VAL_ 623 S4_SRR_RL_Obj_UpdateFlag_24 0 "Measured" 1 "New" ;
VAL_ 623 S4_SRR_RL_Obj_Type_24 0 "OBJ_CLASS_POINT" 1 "OBJ_CLASS_CAR" 2 "OBJ_CLASS_TRUCK" 3 "OBJ_CLASS_PEDESTRIAN" 4 "OBJ_CLASS_MOTORCYCLE" 5 "OBJ_CLASS_BICYCLE" 6 "OBJ_CLASS_WIDE" 7 "OBJ_CLASS_UNCLASSIFIED" 8 "OBJ_CLASS_OTHER_VEHICLE" 9 "OBJ_CLASS_MAX_DIFF_TYPES" ;
VAL_ 623 S4_SRR_RL_Obj_EDynProp_24 0 "MOVING_DYNAMICPROPERTY" 1 "STATIONARY_DYNAMICPROPERTY" 2 "ONCOMING_DYNAMICPROPERTY" 3 "CROSSING_LEFT_TO_RIGHT_DYNAMICPR" 4 "CROSSING_RIGHT_TO_LEFT_DYNAMICPR" 5 "UNKNOWN_DYNAMICPROPERTY" 6 "STOPPED_DYNAMICPROPERTY" 7 "RESERVED" ;
VAL_ 623 S4_SRR_RL_Obj_UiLifeCycles_24 126 "MAX_CYCLE_OBJ_LIFECYCLE" 127 "INVALID_OBJ_LIFECYCLE" ;
VAL_ 623 S4_SRR_RL_Obj_ValidFlag_25 0 "valid" 1 "invalid" ;
VAL_ 623 S4_SRR_RL_Obj_UpdateFlag_25 0 "Measured" 1 "New" ;
VAL_ 623 S4_SRR_RL_Obj_Type_25 0 "OBJ_CLASS_POINT" 1 "OBJ_CLASS_CAR" 2 "OBJ_CLASS_TRUCK" 3 "OBJ_CLASS_PEDESTRIAN" 4 "OBJ_CLASS_MOTORCYCLE" 5 "OBJ_CLASS_BICYCLE" 6 "OBJ_CLASS_WIDE" 7 "OBJ_CLASS_UNCLASSIFIED" 8 "OBJ_CLASS_OTHER_VEHICLE" 9 "OBJ_CLASS_MAX_DIFF_TYPES" ;
VAL_ 623 S4_SRR_RL_Obj_EDynProp_25 0 "MOVING_DYNAMICPROPERTY" 1 "STATIONARY_DYNAMICPROPERTY" 2 "ONCOMING_DYNAMICPROPERTY" 3 "CROSSING_LEFT_TO_RIGHT_DYNAMICPR" 4 "CROSSING_RIGHT_TO_LEFT_DYNAMICPR" 5 "UNKNOWN_DYNAMICPROPERTY" 6 "STOPPED_DYNAMICPROPERTY" 7 "RESERVED" ;
VAL_ 623 S4_SRR_RL_Obj_UiLifeCycles_25 126 "MAX_CYCLE_OBJ_LIFECYCLE" 127 "INVALID_OBJ_LIFECYCLE" ;
VAL_ 623 S4_SRR_RL_Obj_ValidFlag_26 0 "valid" 1 "invalid" ;
VAL_ 623 S4_SRR_RL_Obj_UpdateFlag_26 0 "Measured" 1 "New" ;
VAL_ 623 S4_SRR_RL_Obj_Type_26 0 "OBJ_CLASS_POINT" 1 "OBJ_CLASS_CAR" 2 "OBJ_CLASS_TRUCK" 3 "OBJ_CLASS_PEDESTRIAN" 4 "OBJ_CLASS_MOTORCYCLE" 5 "OBJ_CLASS_BICYCLE" 6 "OBJ_CLASS_WIDE" 7 "OBJ_CLASS_UNCLASSIFIED" 8 "OBJ_CLASS_OTHER_VEHICLE" 9 "OBJ_CLASS_MAX_DIFF_TYPES" ;
VAL_ 623 S4_SRR_RL_Obj_EDynProp_26 0 "MOVING_DYNAMICPROPERTY" 1 "STATIONARY_DYNAMICPROPERTY" 2 "ONCOMING_DYNAMICPROPERTY" 3 "CROSSING_LEFT_TO_RIGHT_DYNAMICPR" 4 "CROSSING_RIGHT_TO_LEFT_DYNAMICPR" 5 "UNKNOWN_DYNAMICPROPERTY" 6 "STOPPED_DYNAMICPROPERTY" 7 "RESERVED" ;
VAL_ 623 S4_SRR_RL_Obj_UiLifeCycles_26 126 "MAX_CYCLE_OBJ_LIFECYCLE" 127 "INVALID_OBJ_LIFECYCLE" ;
VAL_ 624 S4_SRR_RL_Obj_ValidFlag_27 0 "valid" 1 "invalid" ;
VAL_ 624 S4_SRR_RL_Obj_UpdateFlag_27 0 "Measured" 1 "New" ;
VAL_ 624 S4_SRR_RL_Obj_Type_27 0 "OBJ_CLASS_POINT" 1 "OBJ_CLASS_CAR" 2 "OBJ_CLASS_TRUCK" 3 "OBJ_CLASS_PEDESTRIAN" 4 "OBJ_CLASS_MOTORCYCLE" 5 "OBJ_CLASS_BICYCLE" 6 "OBJ_CLASS_WIDE" 7 "OBJ_CLASS_UNCLASSIFIED" 8 "OBJ_CLASS_OTHER_VEHICLE" 9 "OBJ_CLASS_MAX_DIFF_TYPES" ;
VAL_ 624 S4_SRR_RL_Obj_EDynProp_27 0 "MOVING_DYNAMICPROPERTY" 1 "STATIONARY_DYNAMICPROPERTY" 2 "ONCOMING_DYNAMICPROPERTY" 3 "CROSSING_LEFT_TO_RIGHT_DYNAMICPR" 4 "CROSSING_RIGHT_TO_LEFT_DYNAMICPR" 5 "UNKNOWN_DYNAMICPROPERTY" 6 "STOPPED_DYNAMICPROPERTY" 7 "RESERVED" ;
VAL_ 624 S4_SRR_RL_Obj_UiLifeCycles_27 126 "MAX_CYCLE_OBJ_LIFECYCLE" 127 "INVALID_OBJ_LIFECYCLE" ;
VAL_ 624 S4_SRR_RL_Obj_ValidFlag_28 0 "valid" 1 "invalid" ;
VAL_ 624 S4_SRR_RL_Obj_UpdateFlag_28 0 "Measured" 1 "New" ;
VAL_ 624 S4_SRR_RL_Obj_Type_28 0 "OBJ_CLASS_POINT" 1 "OBJ_CLASS_CAR" 2 "OBJ_CLASS_TRUCK" 3 "OBJ_CLASS_PEDESTRIAN" 4 "OBJ_CLASS_MOTORCYCLE" 5 "OBJ_CLASS_BICYCLE" 6 "OBJ_CLASS_WIDE" 7 "OBJ_CLASS_UNCLASSIFIED" 8 "OBJ_CLASS_OTHER_VEHICLE" 9 "OBJ_CLASS_MAX_DIFF_TYPES" ;
VAL_ 624 S4_SRR_RL_Obj_EDynProp_28 0 "MOVING_DYNAMICPROPERTY" 1 "STATIONARY_DYNAMICPROPERTY" 2 "ONCOMING_DYNAMICPROPERTY" 3 "CROSSING_LEFT_TO_RIGHT_DYNAMICPR" 4 "CROSSING_RIGHT_TO_LEFT_DYNAMICPR" 5 "UNKNOWN_DYNAMICPROPERTY" 6 "STOPPED_DYNAMICPROPERTY" 7 "RESERVED" ;
VAL_ 624 S4_SRR_RL_Obj_UiLifeCycles_28 126 "MAX_CYCLE_OBJ_LIFECYCLE" 127 "INVALID_OBJ_LIFECYCLE" ;
VAL_ 624 S4_SRR_RL_Obj_ValidFlag_29 0 "valid" 1 "invalid" ;
VAL_ 624 S4_SRR_RL_Obj_UpdateFlag_29 0 "Measured" 1 "New" ;
VAL_ 624 S4_SRR_RL_Obj_Type_29 0 "OBJ_CLASS_POINT" 1 "OBJ_CLASS_CAR" 2 "OBJ_CLASS_TRUCK" 3 "OBJ_CLASS_PEDESTRIAN" 4 "OBJ_CLASS_MOTORCYCLE" 5 "OBJ_CLASS_BICYCLE" 6 "OBJ_CLASS_WIDE" 7 "OBJ_CLASS_UNCLASSIFIED" 8 "OBJ_CLASS_OTHER_VEHICLE" 9 "OBJ_CLASS_MAX_DIFF_TYPES" ;
VAL_ 624 S4_SRR_RL_Obj_EDynProp_29 0 "MOVING_DYNAMICPROPERTY" 1 "STATIONARY_DYNAMICPROPERTY" 2 "ONCOMING_DYNAMICPROPERTY" 3 "CROSSING_LEFT_TO_RIGHT_DYNAMICPR" 4 "CROSSING_RIGHT_TO_LEFT_DYNAMICPR" 5 "UNKNOWN_DYNAMICPROPERTY" 6 "STOPPED_DYNAMICPROPERTY" 7 "RESERVED" ;
VAL_ 624 S4_SRR_RL_Obj_UiLifeCycles_29 126 "MAX_CYCLE_OBJ_LIFECYCLE" 127 "INVALID_OBJ_LIFECYCLE" ;
VAL_ 627 S4_SRR_RL_Obj_ValidFlag_30 0 "valid" 1 "invalid" ;
VAL_ 627 S4_SRR_RL_Obj_UpdateFlag_30 0 "Measured" 1 "New" ;
VAL_ 627 S4_SRR_RL_Obj_Type_30 0 "OBJ_CLASS_POINT" 1 "OBJ_CLASS_CAR" 2 "OBJ_CLASS_TRUCK" 3 "OBJ_CLASS_PEDESTRIAN" 4 "OBJ_CLASS_MOTORCYCLE" 5 "OBJ_CLASS_BICYCLE" 6 "OBJ_CLASS_WIDE" 7 "OBJ_CLASS_UNCLASSIFIED" 8 "OBJ_CLASS_OTHER_VEHICLE" 9 "OBJ_CLASS_MAX_DIFF_TYPES" ;
VAL_ 627 S4_SRR_RL_Obj_EDynProp_30 0 "MOVING_DYNAMICPROPERTY" 1 "STATIONARY_DYNAMICPROPERTY" 2 "ONCOMING_DYNAMICPROPERTY" 3 "CROSSING_LEFT_TO_RIGHT_DYNAMICPR" 4 "CROSSING_RIGHT_TO_LEFT_DYNAMICPR" 5 "UNKNOWN_DYNAMICPROPERTY" 6 "STOPPED_DYNAMICPROPERTY" 7 "RESERVED" ;
VAL_ 627 S4_SRR_RL_Obj_UiLifeCycles_30 126 "MAX_CYCLE_OBJ_LIFECYCLE" 127 "INVALID_OBJ_LIFECYCLE" ;
VAL_ 627 S4_SRR_RL_Obj_ValidFlag_31 0 "valid" 1 "invalid" ;
VAL_ 627 S4_SRR_RL_Obj_UpdateFlag_31 0 "Measured" 1 "New" ;
VAL_ 627 S4_SRR_RL_Obj_Type_31 0 "OBJ_CLASS_POINT" 1 "OBJ_CLASS_CAR" 2 "OBJ_CLASS_TRUCK" 3 "OBJ_CLASS_PEDESTRIAN" 4 "OBJ_CLASS_MOTORCYCLE" 5 "OBJ_CLASS_BICYCLE" 6 "OBJ_CLASS_WIDE" 7 "OBJ_CLASS_UNCLASSIFIED" 8 "OBJ_CLASS_OTHER_VEHICLE" 9 "OBJ_CLASS_MAX_DIFF_TYPES" ;
VAL_ 627 S4_SRR_RL_Obj_EDynProp_31 0 "MOVING_DYNAMICPROPERTY" 1 "STATIONARY_DYNAMICPROPERTY" 2 "ONCOMING_DYNAMICPROPERTY" 3 "CROSSING_LEFT_TO_RIGHT_DYNAMICPR" 4 "CROSSING_RIGHT_TO_LEFT_DYNAMICPR" 5 "UNKNOWN_DYNAMICPROPERTY" 6 "STOPPED_DYNAMICPROPERTY" 7 "RESERVED" ;
VAL_ 627 S4_SRR_RL_Obj_UiLifeCycles_31 126 "MAX_CYCLE_OBJ_LIFECYCLE" 127 "INVALID_OBJ_LIFECYCLE" ;
VAL_ 627 S4_SRR_RL_Obj_ValidFlag_32 0 "valid" 1 "invalid" ;
VAL_ 627 S4_SRR_RL_Obj_UpdateFlag_32 0 "Measured" 1 "New" ;
VAL_ 627 S4_SRR_RL_Obj_Type_32 0 "OBJ_CLASS_POINT" 1 "OBJ_CLASS_CAR" 2 "OBJ_CLASS_TRUCK" 3 "OBJ_CLASS_PEDESTRIAN" 4 "OBJ_CLASS_MOTORCYCLE" 5 "OBJ_CLASS_BICYCLE" 6 "OBJ_CLASS_WIDE" 7 "OBJ_CLASS_UNCLASSIFIED" 8 "OBJ_CLASS_OTHER_VEHICLE" 9 "OBJ_CLASS_MAX_DIFF_TYPES" ;
VAL_ 627 S4_SRR_RL_Obj_EDynProp_32 0 "MOVING_DYNAMICPROPERTY" 1 "STATIONARY_DYNAMICPROPERTY" 2 "ONCOMING_DYNAMICPROPERTY" 3 "CROSSING_LEFT_TO_RIGHT_DYNAMICPR" 4 "CROSSING_RIGHT_TO_LEFT_DYNAMICPR" 5 "UNKNOWN_DYNAMICPROPERTY" 6 "STOPPED_DYNAMICPROPERTY" 7 "RESERVED" ;
VAL_ 627 S4_SRR_RL_Obj_UiLifeCycles_32 126 "MAX_CYCLE_OBJ_LIFECYCLE" 127 "INVALID_OBJ_LIFECYCLE" ;
VAL_ 629 S4_SRR_RL_Obj_ValidFlag_33 0 "valid" 1 "invalid" ;
VAL_ 629 S4_SRR_RL_Obj_UpdateFlag_33 0 "Measured" 1 "New" ;
VAL_ 629 S4_SRR_RL_Obj_Type_33 0 "OBJ_CLASS_POINT" 1 "OBJ_CLASS_CAR" 2 "OBJ_CLASS_TRUCK" 3 "OBJ_CLASS_PEDESTRIAN" 4 "OBJ_CLASS_MOTORCYCLE" 5 "OBJ_CLASS_BICYCLE" 6 "OBJ_CLASS_WIDE" 7 "OBJ_CLASS_UNCLASSIFIED" 8 "OBJ_CLASS_OTHER_VEHICLE" 9 "OBJ_CLASS_MAX_DIFF_TYPES" ;
VAL_ 629 S4_SRR_RL_Obj_EDynProp_33 0 "MOVING_DYNAMICPROPERTY" 1 "STATIONARY_DYNAMICPROPERTY" 2 "ONCOMING_DYNAMICPROPERTY" 3 "CROSSING_LEFT_TO_RIGHT_DYNAMICPR" 4 "CROSSING_RIGHT_TO_LEFT_DYNAMICPR" 5 "UNKNOWN_DYNAMICPROPERTY" 6 "STOPPED_DYNAMICPROPERTY" 7 "RESERVED" ;
VAL_ 629 S4_SRR_RL_Obj_UiLifeCycles_33 126 "MAX_CYCLE_OBJ_LIFECYCLE" 127 "INVALID_OBJ_LIFECYCLE" ;
VAL_ 629 S4_SRR_RL_Obj_ValidFlag_34 0 "valid" 1 "invalid" ;
VAL_ 629 S4_SRR_RL_Obj_UpdateFlag_34 0 "Measured" 1 "New" ;
VAL_ 629 S4_SRR_RL_Obj_Type_34 0 "OBJ_CLASS_POINT" 1 "OBJ_CLASS_CAR" 2 "OBJ_CLASS_TRUCK" 3 "OBJ_CLASS_PEDESTRIAN" 4 "OBJ_CLASS_MOTORCYCLE" 5 "OBJ_CLASS_BICYCLE" 6 "OBJ_CLASS_WIDE" 7 "OBJ_CLASS_UNCLASSIFIED" 8 "OBJ_CLASS_OTHER_VEHICLE" 9 "OBJ_CLASS_MAX_DIFF_TYPES" ;
VAL_ 629 S4_SRR_RL_Obj_EDynProp_34 0 "MOVING_DYNAMICPROPERTY" 1 "STATIONARY_DYNAMICPROPERTY" 2 "ONCOMING_DYNAMICPROPERTY" 3 "CROSSING_LEFT_TO_RIGHT_DYNAMICPR" 4 "CROSSING_RIGHT_TO_LEFT_DYNAMICPR" 5 "UNKNOWN_DYNAMICPROPERTY" 6 "STOPPED_DYNAMICPROPERTY" 7 "RESERVED" ;
VAL_ 629 S4_SRR_RL_Obj_UiLifeCycles_34 126 "MAX_CYCLE_OBJ_LIFECYCLE" 127 "INVALID_OBJ_LIFECYCLE" ;
VAL_ 629 S4_SRR_RL_Obj_ValidFlag_35 0 "valid" 1 "invalid" ;
VAL_ 629 S4_SRR_RL_Obj_UpdateFlag_35 0 "Measured" 1 "New" ;
VAL_ 629 S4_SRR_RL_Obj_Type_35 0 "OBJ_CLASS_POINT" 1 "OBJ_CLASS_CAR" 2 "OBJ_CLASS_TRUCK" 3 "OBJ_CLASS_PEDESTRIAN" 4 "OBJ_CLASS_MOTORCYCLE" 5 "OBJ_CLASS_BICYCLE" 6 "OBJ_CLASS_WIDE" 7 "OBJ_CLASS_UNCLASSIFIED" 8 "OBJ_CLASS_OTHER_VEHICLE" 9 "OBJ_CLASS_MAX_DIFF_TYPES" ;
VAL_ 629 S4_SRR_RL_Obj_EDynProp_35 0 "MOVING_DYNAMICPROPERTY" 1 "STATIONARY_DYNAMICPROPERTY" 2 "ONCOMING_DYNAMICPROPERTY" 3 "CROSSING_LEFT_TO_RIGHT_DYNAMICPR" 4 "CROSSING_RIGHT_TO_LEFT_DYNAMICPR" 5 "UNKNOWN_DYNAMICPROPERTY" 6 "STOPPED_DYNAMICPROPERTY" 7 "RESERVED" ;
VAL_ 629 S4_SRR_RL_Obj_UiLifeCycles_35 126 "MAX_CYCLE_OBJ_LIFECYCLE" 127 "INVALID_OBJ_LIFECYCLE" ;
VAL_ 630 S4_SRR_RL_Obj_ValidFlag_36 0 "valid" 1 "invalid" ;
VAL_ 630 S4_SRR_RL_Obj_UpdateFlag_36 0 "Measured" 1 "New" ;
VAL_ 630 S4_SRR_RL_Obj_Type_36 0 "OBJ_CLASS_POINT" 1 "OBJ_CLASS_CAR" 2 "OBJ_CLASS_TRUCK" 3 "OBJ_CLASS_PEDESTRIAN" 4 "OBJ_CLASS_MOTORCYCLE" 5 "OBJ_CLASS_BICYCLE" 6 "OBJ_CLASS_WIDE" 7 "OBJ_CLASS_UNCLASSIFIED" 8 "OBJ_CLASS_OTHER_VEHICLE" 9 "OBJ_CLASS_MAX_DIFF_TYPES" ;
VAL_ 630 S4_SRR_RL_Obj_EDynProp_36 0 "MOVING_DYNAMICPROPERTY" 1 "STATIONARY_DYNAMICPROPERTY" 2 "ONCOMING_DYNAMICPROPERTY" 3 "CROSSING_LEFT_TO_RIGHT_DYNAMICPR" 4 "CROSSING_RIGHT_TO_LEFT_DYNAMICPR" 5 "UNKNOWN_DYNAMICPROPERTY" 6 "STOPPED_DYNAMICPROPERTY" 7 "RESERVED" ;
VAL_ 630 S4_SRR_RL_Obj_UiLifeCycles_36 126 "MAX_CYCLE_OBJ_LIFECYCLE" 127 "INVALID_OBJ_LIFECYCLE" ;
VAL_ 630 S4_SRR_RL_Obj_ValidFlag_37 0 "valid" 1 "invalid" ;
VAL_ 630 S4_SRR_RL_Obj_UpdateFlag_37 0 "Measured" 1 "New" ;
VAL_ 630 S4_SRR_RL_Obj_Type_37 0 "OBJ_CLASS_POINT" 1 "OBJ_CLASS_CAR" 2 "OBJ_CLASS_TRUCK" 3 "OBJ_CLASS_PEDESTRIAN" 4 "OBJ_CLASS_MOTORCYCLE" 5 "OBJ_CLASS_BICYCLE" 6 "OBJ_CLASS_WIDE" 7 "OBJ_CLASS_UNCLASSIFIED" 8 "OBJ_CLASS_OTHER_VEHICLE" 9 "OBJ_CLASS_MAX_DIFF_TYPES" ;
VAL_ 630 S4_SRR_RL_Obj_EDynProp_37 0 "MOVING_DYNAMICPROPERTY" 1 "STATIONARY_DYNAMICPROPERTY" 2 "ONCOMING_DYNAMICPROPERTY" 3 "CROSSING_LEFT_TO_RIGHT_DYNAMICPR" 4 "CROSSING_RIGHT_TO_LEFT_DYNAMICPR" 5 "UNKNOWN_DYNAMICPROPERTY" 6 "STOPPED_DYNAMICPROPERTY" 7 "RESERVED" ;
VAL_ 630 S4_SRR_RL_Obj_UiLifeCycles_37 126 "MAX_CYCLE_OBJ_LIFECYCLE" 127 "INVALID_OBJ_LIFECYCLE" ;
VAL_ 630 S4_SRR_RL_Obj_ValidFlag_38 0 "valid" 1 "invalid" ;
VAL_ 630 S4_SRR_RL_Obj_UpdateFlag_38 0 "Measured" 1 "New" ;
VAL_ 630 S4_SRR_RL_Obj_Type_38 0 "OBJ_CLASS_POINT" 1 "OBJ_CLASS_CAR" 2 "OBJ_CLASS_TRUCK" 3 "OBJ_CLASS_PEDESTRIAN" 4 "OBJ_CLASS_MOTORCYCLE" 5 "OBJ_CLASS_BICYCLE" 6 "OBJ_CLASS_WIDE" 7 "OBJ_CLASS_UNCLASSIFIED" 8 "OBJ_CLASS_OTHER_VEHICLE" 9 "OBJ_CLASS_MAX_DIFF_TYPES" ;
VAL_ 630 S4_SRR_RL_Obj_EDynProp_38 0 "MOVING_DYNAMICPROPERTY" 1 "STATIONARY_DYNAMICPROPERTY" 2 "ONCOMING_DYNAMICPROPERTY" 3 "CROSSING_LEFT_TO_RIGHT_DYNAMICPR" 4 "CROSSING_RIGHT_TO_LEFT_DYNAMICPR" 5 "UNKNOWN_DYNAMICPROPERTY" 6 "STOPPED_DYNAMICPROPERTY" 7 "RESERVED" ;
VAL_ 630 S4_SRR_RL_Obj_UiLifeCycles_38 126 "MAX_CYCLE_OBJ_LIFECYCLE" 127 "INVALID_OBJ_LIFECYCLE" ;
VAL_ 631 S4_SRR_RL_Obj_ValidFlag_39 0 "valid" 1 "invalid" ;
VAL_ 631 S4_SRR_RL_Obj_UpdateFlag_39 0 "Measured" 1 "New" ;
VAL_ 631 S4_SRR_RL_Obj_Type_39 0 "OBJ_CLASS_POINT" 1 "OBJ_CLASS_CAR" 2 "OBJ_CLASS_TRUCK" 3 "OBJ_CLASS_PEDESTRIAN" 4 "OBJ_CLASS_MOTORCYCLE" 5 "OBJ_CLASS_BICYCLE" 6 "OBJ_CLASS_WIDE" 7 "OBJ_CLASS_UNCLASSIFIED" 8 "OBJ_CLASS_OTHER_VEHICLE" 9 "OBJ_CLASS_MAX_DIFF_TYPES" ;
VAL_ 631 S4_SRR_RL_Obj_EDynProp_39 0 "MOVING_DYNAMICPROPERTY" 1 "STATIONARY_DYNAMICPROPERTY" 2 "ONCOMING_DYNAMICPROPERTY" 3 "CROSSING_LEFT_TO_RIGHT_DYNAMICPR" 4 "CROSSING_RIGHT_TO_LEFT_DYNAMICPR" 5 "UNKNOWN_DYNAMICPROPERTY" 6 "STOPPED_DYNAMICPROPERTY" 7 "RESERVED" ;
VAL_ 631 S4_SRR_RL_Obj_UiLifeCycles_39 126 "MAX_CYCLE_OBJ_LIFECYCLE" 127 "INVALID_OBJ_LIFECYCLE" ;
VAL_ 634 S4_SRR_RL_Clu_Valid 0 "Valid" 1 "Not Valid" ;
VAL_ 634 S4_SRR_RL_Obj_Valid 0 "Valid" 1 "Not Valid" ;
VAL_ 634 S4_SRR_RL_HWFailureSt 0 "No failure" 1 "Failure" ;
VAL_ 634 S4_SRR_RL_MisAliSt 0 "Not misalignment" 1 "Misalignment" ;
VAL_ 634 S4_SRR_RL_BlockSt 0 "Not block" 1 "Block" ;
VAL_ 634 S4_SRR_RL_TempOutofRange 0 "Not active" 1 "Active" ;
VAL_ 634 S4_SRR_RL_Modulation_Status 0 "No Failure" 1 "Time Sync Failure" 2 "Modulation Failure" 3 "Reserved" ;
VAL_ 634 S4_SRR_RL_BSDLeftSt 0 "Off" 1 "On" 2 "Fail" 3 "off-observatory" 4 "off-trailer mode" 5 "reserved" 6 "reserved" 7 "reserved" ;
VAL_ 634 S4_SRR_RL_BSDLeftWarning 0 "no warning" 1 "warning level 1" 2 "warning level 2" 3 "reserved" ;
VAL_ 634 S4_SRR_RL_DOWLeft 0 "Off" 1 "On" 2 "Fail" 3 "off-observatory" 4 "off-trailer mode" 5 "reserved" 6 "reserved" 7 "reserved" ;
VAL_ 634 S4_SRR_RL_DOWLeftWarning 0 "no warning" 1 "RML and ATLS ON" 2 "RML ON" 3 "reserved" ;
VAL_ 634 S4_SRR_RL_RCTALeftSt 0 "Off" 1 "On" 2 "Fail" 3 "off-observatory" 4 "off-trailer mode" 5 "reserved" 6 "reserved" 7 "reserved" ;
VAL_ 634 S4_SRR_RL_RCTALeftWarning 0 "no warning" 1 "warning level 1" 2 "reserved" 3 "reserved" ;
VAL_ 634 S4_SRR_RL_RCWLeftSt 0 "Off" 1 "On" 2 "Fail" 3 "off-observatory" 4 "off-trailer mode" 5 "reserved" 6 "reserved" 7 "reserved" ;
VAL_ 634 S4_SRR_RL_RCWLeftWarn 0 "no warning" 1 "warning level 1" 2 "reserved" 3 "reserved" ;
VAL_ 634 S4_SRR_RL_CalibratedSt 0 "Not Calibration" 1 "Calibrated" 2 "EOL Calibration running" 3 "Dynamic Calibration running" 4 "Calibration failure" 5 "reserved" 6 "reserved" 7 "reserved" ;
VAL_ 634 S4_SRR_RL_RadarEmissionSt 0 "Off" 1 "On" 2 "Fial" 3 "reserved" ;
VAL_ 634 S4_SRR_RL_DataUpload_St 0 "Normal" 1 "Warning" 2 "Level 1 Error" 3 "Level 2 Error" 4 "Level 3 Error" 5 "Level 4 Error" 6 "Level 5 Error" 7 "Reserved" ;
VAL_ 634 S4_SRR_RL_InitialState 0 "initialization not OK" 1 "initializing" 2 "initialization done" 3 "initialization failure" ;
VAL_ 950 S4_SRR_RL_VBAT_HIGH 0 "Not active" 1 "Active" ;
VAL_ 950 S4_SRR_RL_VBAT_LOW 0 "Not active" 1 "Active" ;
VAL_ 950 S4_SRR_RL_SFCAN_CANBUS 0 "Not active" 1 "Active" ;
VAL_ 950 S4_SRR_RL_XPU_TIMEOUT 0 "Not active" 1 "Active" ;
VAL_ 950 S4_SRR_RL_OVERTEMP_FAIL 0 "Not active" 1 "Active" ;
VAL_ 950 S4_SRR_RL_UNDERTEMP_FAIL 0 "Not active" 1 "Active" ;
VAL_ 950 S4_SRR_RL_RFCOM_ERROR 0 "Not active" 1 "Active" ;
VAL_ 950 S4_SRR_RL_SPT_ERROR 0 "Not active" 1 "Active" ;
VAL_ 950 S4_SRR_RL_RFWAVE_CHECK_ERROR 0 "Not active" 1 "Active" ;
VAL_ 950 S4_SRR_RL_SWEXETIMING_VIOLATION 0 "Not active" 1 "Active" ;
VAL_ 950 S4_SRR_RL_SRR_PERMHW_FAIL 0 "Not active" 1 "Active" ;
VAL_ 950 S4_SRR_RL_ECU_SELFTEST_FAIL 0 "Not active" 1 "Active" ;
VAL_ 950 S4_SRR_RL_SWHW_COMPAT_CHECK 0 "Not active" 1 "Active" ;
VAL_ 950 S4_SRR_RL_PLCM_SYS_ERROR 0 "Not active" 1 "Active" ;
VAL_ 950 S4_SRR_RL_RF_VOLT_FAULT 0 "Not active" 1 "Active" ;
VAL_ 950 S4_SRR_RL_RF_TEMP_FAULT 0 "Not active" 1 "Active" ;
VAL_ 950 S4_SRR_RL_SRR_NVM_FAIL 0 "Not active" 1 "Active" ;
VAL_ 950 S4_SRR_RL_TIME_SYN_FAIL 0 "Not active" 1 "Active" ;
VAL_ 950 S4_SRR_RL_SRR_POSNOTCONFIG 0 "Not active" 1 "Active" ;
VAL_ 950 S4_SRR_RL_SRR_POSCONFIG_FAIL 0 "Not active" 1 "Active" ;
VAL_ 950 S4_SRR_RL_SRR_POSCONFIG_UPDATE 0 "Not active" 1 "Active" ;
VAL_ 950 S4_SRR_RL_SRR_VDY_SIG_EXCEPTION 0 "Not active" 1 "Active" ;
VAL_ 950 S4_SRR_RL_CDCU_TotOdo_Miss_ERR 0 "Not active" 1 "Active" ;
VAL_ 950 S4_SRR_RL_LDCU_SysSt_Miss_ERR 0 "Not active" 1 "Active" ;
VAL_ 950 S4_SRR_RL_LDCU_BSysSt1_Miss_ERR 0 "Not active" 1 "Active" ;
VAL_ 950 S4_SRR_RL_RDCU_BSysSt1_Miss_ERR 0 "Not active" 1 "Active" ;
VAL_ 950 S4_SRR_RL_RDCU_BSysSt2_Miss_ERR 0 "Not active" 1 "Active" ;
VAL_ 950 S4_SRR_RL_ESP_SpdInfoF_Miss_ERR 0 "Not active" 1 "Active" ;
VAL_ 950 S4_SRR_RL_ESP_SpdInfoR_ERR 0 "Not active" 1 "Active" ;
VAL_ 950 S4_SRR_RL_ESP_SysSt_ERR 0 "Not active" 1 "Active" ;
VAL_ 950 S4_SRR_RL_ESP_Accel_ERR 0 "Not active" 1 "Active" ;
VAL_ 950 S4_SRR_RL_ESP_AccelOffset_ERR 0 "Not active" 1 "Active" ;
VAL_ 950 S4_SRR_RL_EPS_SASInfo_ERR 0 "Not active" 1 "Active" ;
VAL_ 950 S4_SRR_RL_TBOX_TimeInfo_ERR 0 "Not active" 1 "Active" ;
VAL_ 950 S4_SRR_RL_TBOX_GPSInfo_ERR 0 "Not active" 1 "Active" ;
VAL_ 950 S4_SRR_RL_LDCU_ALC_ERR 0 "Not active" 1 "Active" ;
VAL_ 950 S4_SRR_RL_ESP_ALC_ERR 0 "Not active" 1 "Active" ;
VAL_ 950 S4_SRR_RL_EPS_ALC_ERR 0 "Not active" 1 "Active" ;
VAL_ 950 S4_SRR_RL_XPU_ALC_ERR 0 "Not active" 1 "Active" ;
VAL_ 950 S4_SRR_RL_LDCU_CRC_ERR 0 "Not active" 1 "Active" ;
VAL_ 950 S4_SRR_RL_ESP_CRC_ERR 0 "Not active" 1 "Active" ;
VAL_ 950 S4_SRR_RL_EPS_CRC_ERR 0 "Not active" 1 "Active" ;
VAL_ 950 S4_SRR_RL_XPU_CRC_ERR 0 "Not active" 1 "Active" ;
VAL_ 950 S4_SRR_RL_ESP_WHLSPD_INVALID 0 "Not active" 1 "Active" ;
VAL_ 950 S4_SRR_RL_EPS_SASFAULT_INVALID 0 "Not active" 1 "Active" ;
VAL_ 950 S4_SRR_RL_ESP_LGTACCE_INVALID 0 "Not active" 1 "Active" ;
VAL_ 950 S4_SRR_RL_ESP_LATACCE_INVALID 0 "Not active" 1 "Active" ;
VAL_ 950 S4_SRR_RL_ESP_YAWRATE_INVALID 0 "Not active" 1 "Active" ;
VAL_ 950 S4_SRR_RL_ESP_WHLMOVGDIR_IVD 0 "Not active" 1 "Active" ;
VAL_ 950 S4_SRR_RL_EPS_SAVD_INVALID 0 "Not active" 1 "Active" ;
VAL_ 950 S4_SRR_RL_EPS_SASCALST_INVALID 0 "Not active" 1 "Active" ;
VAL_ 950 S4_SRR_RL_LDCU_CurGearLev_ivd 0 "Not active" 1 "Active" ;
VAL_ 950 S4_SRR_RL_LDCU_AccPedalSig_IVD 0 "Not active" 1 "Active" ;
VAL_ 950 S4_SRR_RL_LDCU_BrkPedalSt_IVD 0 "Not active" 1 "Active" ;
VAL_ 950 S4_SRR_RL_EPS_SASPDSIG_IVD 0 "Not active" 1 "Active" ;
VAL_ 950 S4_SRR_RL_SRR_BLIND_FAIL 0 "Not active" 1 "Active" ;
VAL_ 950 S4_SRR_RL_SENSOR_POS_FAIL 0 "Not active" 1 "Active" ;
VAL_ 950 S4_SRR_RL_SRR_NOT_ALN_FAIL 0 "Not active" 1 "Active" ;
VAL_ 950 S4_SRR_RL_SENSOR_MISALN_FAIL 0 "Not active" 1 "Active" ;
VAL_ 950 S4_SRR_RL_Distortion_Flag 0 "valid" 1 "invalid" ;
VAL_ 950 S4_SRR_RL_Absorption_Flag 0 "valid" 1 "invalid" ;
VAL_ 950 S4_SRR_RL_Driverset_Active_FAIL 0 "Not active" 1 "Active" ;
VAL_ 950 S4_SRR_RL_Production_Data_FAIL 0 "Not active" 1 "Active" ;
VAL_ 950 S4_SRR_RL_Powermanege_Over_Voltage_FAIL 0 "Not active" 1 "Active" ;
VAL_ 950 S4_SRR_RL_MMIC_Over_Voltage_FAIL 0 "Not active" 1 "Active" ;
VAL_ 950 S4_SRR_RL_Powermanege_Under_Voltage_FAIL 0 "Not active" 1 "Active" ;
VAL_ 950 S4_SRR_RL_MMIC_Under_Voltage_FAIL 0 "Not active" 1 "Active" ;
VAL_ 950 S4_SRR_RL_Modulation_config_FAIL 0 "Not active" 1 "Active" ;
VAL_ 950 S4_SRR_RL_Modulation_FAIL 0 "Not active" 1 "Active" ;
VAL_ 950 S4_SRR_RL_SW_FAIL 0 "Not active" 1 "Active" ;
VAL_ 950 S4_SRR_RL_SW_TEMP_FAIL 0 "Not active" 1 "Active" ;
VAL_ 950 S4_SRR_RL_UC_Over_TEMP_FAIL 0 "Not active" 1 "Active" ;
VAL_ 950 S4_SRR_RL_Radar_HW_FAIL 0 "Not active" 1 "Active" ;
VAL_ 950 S4_SRR_RL_Production_Mode_FAIL 0 "Not active" 1 "Active" ;
VAL_ 950 S4_SRR_RL_SYNC_timebase_FAIL 0 "Not active" 1 "Active" ;
VAL_ 950 S4_SRR_RL_SYNC_timeout_FAIL 0 "Not active" 1 "Active" ;
VAL_ 950 S4_SRR_RL_SYNC_timeleap_FAIL 0 "Not active" 1 "Active" ;
VAL_ 950 S4_SRR_RL_Variant_FAIL 0 "Not active" 1 "Active" ;
VAL_ 950 S4_SRR_RL_ESP_SysSt_E2E_ERR 0 "Not active" 1 "Active" ;
VAL_ 950 S4_SRR_RL_AS_SysSt1_Missing_ERR 0 "Not active" 1 "Active" ;
VAL_ 950 S4_SRR_RL_AS_SysSt2_Missing_ERR 0 "Not active" 1 "Active" ;
VAL_ 950 S4_SRR_RL_RWS_Sys_Missing_ERR 0 "Not active" 1 "Active" ;
VAL_ 950 S4_SRR_RL_RWS_CRC_ERR 0 "Not active" 1 "Active" ;
VAL_ 950 S4_SRR_RL_RWS_ALC_ERR 0 "Not active" 1 "Active" ;
VAL_ 950 S4_SRR_RL_IPB_Wheelspd_INVALID 0 "Not active" 1 "Active" ;
VAL_ 950 S4_SRR_RL_ESP_ABS_fault 0 "Not active" 1 "Active" ;
VAL_ 950 S4_SRR_RL_ESP_Standstill_INVALID 0 "Not active" 1 "Active" ;
VAL_ 950 S4_SRR_RL_IPB_LGTACCE_INVALID 0 "Not active" 1 "Active" ;
VAL_ 950 S4_SRR_RL_IPB_LATACCE_INVALID 0 "Not active" 1 "Active" ;
VAL_ 950 S4_SRR_RL_IPB_YAWRATE_INVALID 0 "Not active" 1 "Active" ;
VAL_ 950 S4_SRR_RL_AS_level_invalid 0 "Not active" 1 "Active" ;
VAL_ 950 S4_SRR_RL_RWS_wheelangle_invalid 0 "Not active" 1 "Active" ;
VAL_ 787 S4_SRR_eSensorID 0 "INVALID" 1 "Front_Left" 2 "Front_Right" 3 "Rear_Left" 4 "Rear_Right" 255 "Not_Configured" ;
VAL_ 787 S4_XPU_LanechangeStatus 0 "No action" 1 "Left change" 2 "Right change" 3 "Reserved" ;
VAL_ 279 S4_LDCU_CurrentGearLev 0 "Invalid" 1 "D" 2 "N" 3 "R" 4 "P" 5 "Reserved" 6 "Reserved" 7 "Reserved" ;
VAL_ 279 S4_LDCU_ExterTempVD 0 "Not valid" 1 "Valid" ;
VAL_ 279 S4_LDCU_BrkPedalSt 0 "Not Pressed" 1 "Pressed" ;
VAL_ 279 S4_LDCU_BrkPedalStVD 0 "Not valid" 1 "Valid" ;
VAL_ 279 S4_LDCU_AccPedalSigVD 0 "Not valid" 1 "Valid" ;
VAL_ 870 S4_CDCU_TotalOdometerVD 0 "Not valid" 1 "Valid" ;
VAL_ 548 S4_LDCU_PowerMode 0 "OFF" 1 "Local ON" 2 "Remote ON" 3 "Reserved" ;
VAL_ 548 S4_LDCU_DriverDoorAjarSt 0 "Closed" 1 "Open" ;
VAL_ 548 S4_LDCU_RLDoorAjarSt 0 "Closed" 1 "Open" ;
VAL_ 549 S4_RDCU_PsngrDoorAjarSt 0 "Closed" 1 "Open" ;
VAL_ 549 S4_RDCU_RRDoorAjarSt 0 "Closed" 1 "Open" ;
VAL_ 549 S4_RDCU_HazardLampOutputSt 0 "Not Active" 1 "Active" ;
VAL_ 549 S4_RDCU_FWiperSwSt 0 "OFF" 1 "Low" 2 "High" 3 "INT(Auto)" 4 "reserved" 5 "reserved" 6 "reserved" 7 "reserved" ;
VAL_ 551 S4_RDCU_LTurnLampSwSt 0 "OFF" 1 "ON" ;
VAL_ 551 S4_RDCU_RTurnLampSwSt 0 "OFF" 1 "ON" ;
VAL_ 551 S4_RDCU_LTurnLampOutputSt 0 "Not active" 1 "Active" ;
VAL_ 551 S4_RDCU_RTurnLampOutputSt 0 "Not active" 1 "Active" ;
VAL_ 539 S4_CDCU_BSDSwSt 0 "No comment" 1 "Off" 2 "On" 3 "Reserved" ;
VAL_ 539 S4_CDCU_RCTASwSt 0 "No comment" 1 "Off" 2 "On" 3 "Reserved" ;
VAL_ 539 S4_CDCU_RCWSwSt 0 "No comment" 1 "Off" 2 "On" 3 "Reserved" ;
VAL_ 539 S4_CDCU_DOWSwSt 0 "No comment" 1 "Off" 2 "On" 3 "Reserved" ;
VAL_ 539 S4_CDCU_RadarEmissionSwSt 0 "No comment" 1 "Off" 2 "On" 3 "Reserved" ;
VAL_ 399 S4_AS_DrvModSts 0 "ECO" 1 "Comfort" 2 "Normal" 3 "Sport" 4 "Customer mode" 5 "Offroad" ;
VAL_ 399 S4_AS_LvlChg 0 "No Change" 1 "Going Down" 2 "Going Up" ;
VAL_ 399 S4_AS_TarLvl 0 "HL2" 1 "HL1" 2 "NL" 3 "LL1" 4 "LL2" 5 "LL3" 6 "Not Valid" 7 "Reserved" ;
VAL_ 399 S4_AS_HeightLvl 0 "HL2" 1 "HL1" 2 "NL" 3 "LL1" 4 "LL2" 5 "LL3" 6 "Not Valid" 7 "Reserved" ;
VAL_ 399 S4_AS_MaintainMode 0 "No Request" 1 "maintenance Mode" 2 "Transport Mode" 3 "Trailer Mode" 4 "Reserved" 5 "Reserved" 6 "Camping Mode" ;
VAL_ 399 S4_AS_HoistMode 0 "not active" 1 "active" ;
VAL_ 658 S4_AS_LvlFLVD 0 "Not valid" 1 "valid" ;
VAL_ 658 S4_AS_LvlFRVD 0 "Not valid" 1 "valid" ;
VAL_ 658 S4_AS_LvlRLVD 0 "Not valid" 1 "valid" ;
VAL_ 658 S4_AS_LvlRRVD 0 "Not valid" 1 "valid" ;
VAL_ 281 S4_RWS_WheelangleValid 0 "Not valid" 1 "Valid" ;
VAL_ 281 S4_RWS_SysWarning 0 "normal" 1 "critical failure" 2 "general failure" 3 "reserved" ;
VAL_ 281 S4_RWS_ActualSts 0 "Not Controllable" 1 "Ready For Control" 2 "Controlled" 3 "Error" 4 "reserved" 5 "reserved" 6 "reserved" 7 "reserved" 8 "reserved" 9 "reserved" 10 "reserved" 11 "reserved" 12 "reserved" 13 "reserved" 14 "reserved" 15 "reserved" ;
VAL_ 281 S4_RWS_EndVMCCtrlReason 0 "Normal Operation" 1 "Over speed" 2 "angle request exceeds" 4 "Abnormal CAN Input" 5 "RWS failure" 6 "VMC failure" 7 "reserved" ;
VAL_ 294 S4_IPB_FLWheelSpdVD_E2E 0 "Not valid" 1 "valid" ;
VAL_ 294 S4_IPB_FRWheelSpdVD_E2E 0 "Not valid" 1 "valid" ;
VAL_ 294 S4_IPB_VehSpdVD_E2E 0 "Not Initialized" 1 "valid" 2 "Invalid" 3 "Reserved" ;
VAL_ 294 S4_IPB_RLWheelSpdVD_E2E 0 "Not valid" 1 "valid" ;
VAL_ 294 S4_IPB_RRWheelSpdVD_E2E 0 "Not valid" 1 "valid" ;
VAL_ 422 S4_IPB_BrkPedalSt_E2E 0 "Not Pressed" 1 "Pressed" ;
VAL_ 422 S4_IPB_BrkPedalStVD_E2E 0 "Not valid" 1 "Valid" ;
VAL_ 422 S4_IPB_CDPAvl_E2E 0 "Not available" 1 "Available" ;
VAL_ 422 S4_IPB_HpsAcknowledge_E2E 0 "NotAcknowledged" 1 "Acknowledged" ;
VAL_ 422 S4_IPB_HpsAvailability_E2E 0 "NotAvailable" 1 "Available" ;
VAL_ 422 S4_IPB_ABSFault_E2E 0 "Not fault" 1 "Fault" ;
VAL_ 422 S4_IPB_ABSActSt_E2E 0 "Not active" 1 "Active" ;
VAL_ 422 S4_IPB_VDCActSt_E2E 0 "Not active" 1 "active" ;
VAL_ 422 S4_IPB_TCSActSt_E2E 0 "Not active" 1 "active" ;
VAL_ 422 S4_IPB_BrkLightOnReq_E2E 0 "Off" 1 "On" ;
VAL_ 422 S4_IPB_CDDFaultSt_E2E 0 "Not fault" 1 "Fault" ;
VAL_ 422 S4_IPB_CddAvl_E2E 0 "not available" 1 "available" ;
VAL_ 422 S4_IPB_VehLongAccelVD_E2E 0 "Not valid" 1 "valid" ;
VAL_ 422 S4_IPB_VehLateralAccelVD_E2E 0 "Not valid" 1 "valid" ;
VAL_ 422 S4_IPB_YAWRateVD_E2E 0 "Not valid" 1 "valid" ;
VAL_ 422 S4_IPB_FLWheelRotatedDirct_E2E 0 "Not valid" 1 "forward" 2 "backward" 3 "stop" ;
VAL_ 422 S4_IPB_FLWheelRotatedDirctVD_E2E 0 "Not valid" 1 "valid" ;
VAL_ 422 S4_IPB_FRWheelRotatedDirct_E2E 0 "Not valid" 1 "forward" 2 "backward" 3 "stop" ;
VAL_ 422 S4_IPB_FRWheelRotatedDirctVD_E2E 0 "Not valid" 1 "valid" ;
VAL_ 422 S4_IPB_RLWheelRotatedDirct_E2E 0 "Not valid" 1 "forward" 2 "backward" 3 "stop" ;
VAL_ 422 S4_IPB_RLWheelRotatedDirctVD_E2E 0 "Not valid" 1 "valid" ;
VAL_ 422 S4_IPB_RRWheelRotatedDirct_E2E 0 "Not valid" 1 "forward" 2 "backward" 3 "stop" ;
VAL_ 422 S4_IPB_RRWheelRotatedDirctVD_E2E 0 "Not valid" 1 "valid" ;
VAL_ 422 S4_IPB_EPB_ParkReq_E2E 0 "No request" 1 "Relese bake request" 2 "Lock bake request" 3 "Invailid" ;
VAL_ 275 S4_EPS_SteeringAngleVD_E2E 0 "Not Valid" 1 "Valid" ;
VAL_ 275 S4_EPS_SASCalibratedSt_E2E 0 "Notcalibration" 1 "Calibration" ;
VAL_ 275 S4_EPS_SASFault_E2E 0 "Not Valid" 1 "Valid" ;
VAL_ 275 S4_EPS_SASInterStFlags_E2E 0 "Notcalibration" 1 "Calibration" ;
VAL_ 275 S4_EPS_LDWCtrlSt_E2E 0 "Deactivated" 1 "Inactive" 2 "Active" 3 "Reserved" ;
VAL_ 275 S4_EPS_TorqCtrlMode 0 "init" 1 "APA" 2 "RPA" 3 "LCC" 4 "ELK" 5 "Reserved" 6 "Reserved" 7 "Reserved" ;
VAL_ 423 S4_IPB_ABSFault 0 "Not fault" 1 "Fault" ;
VAL_ 423 S4_IPB_ABSActSt 0 "Not active" 1 "Active" ;
VAL_ 423 S4_IPB_VDCActSt 0 "Not active" 1 "active" ;
VAL_ 423 S4_IPB_TCSActSt 0 "Not active" 1 "active" ;
VAL_ 423 S4_IPB_ESPPATA 0 "normal" 1 "sport" 2 "off" 3 "reserved" ;
VAL_ 423 S4_IPB_ESPFault 0 "Not fault" 1 "Fault" ;
VAL_ 423 S4_IPB_StandStillSt 0 "not standstill" 1 "standstill" 2 "invalid" 3 "reserved" ;
VAL_ 423 S4_IPB_EmerLightReq 0 "Off" 1 "On" ;
VAL_ 638 S4_TTM_HookStatus 0 "Closed" 1 "Opened" 2 "Middle" 3 "Reserved" ;
VAL_ 638 S4_TTM_SysErr 0 "No Error" 1 "Error" ;
